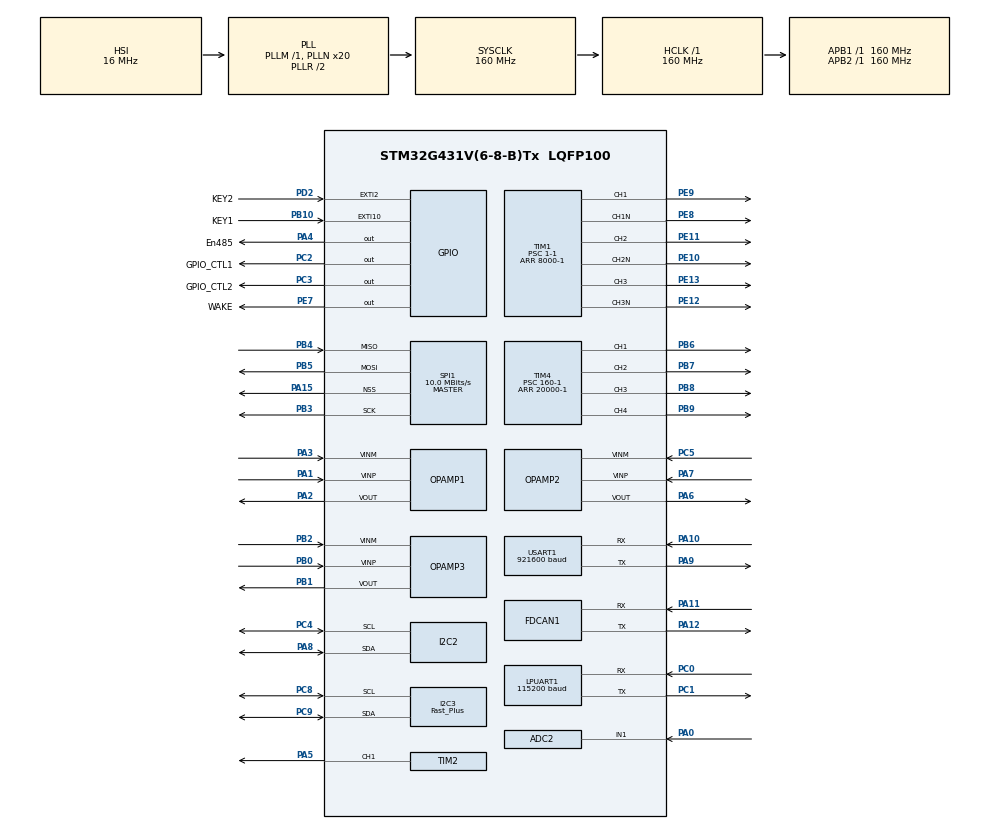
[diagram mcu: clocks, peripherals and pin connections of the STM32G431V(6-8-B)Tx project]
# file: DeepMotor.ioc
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ADC1.Channel-0\#ChannelRegularConversion=ADC_CHANNEL_3
ADC1.EnableInjectedConversion=ENABLE
ADC1.ExternalTrigInjecConv=ADC_EXTERNALTRIGINJEC_T1_CC4
ADC1.InjNumberOfConversion=2
ADC1.InjectedChannel-1\#ChannelInjectedConversion=ADC_CHANNEL_3
ADC1.InjectedChannel-2\#ChannelInjectedConversion=ADC_CHANNEL_12
ADC1.InjectedOffsetNumber-1\#ChannelInjectedConversion=ADC_OFFSET_NONE
ADC1.InjectedOffsetNumber-2\#ChannelInjectedConversion=ADC_OFFSET_NONE
ADC1.InjectedRank-1\#ChannelInjectedConversion=1
ADC1.InjectedRank-2\#ChannelInjectedConversion=2
ADC1.InjectedSamplingTime-1\#ChannelInjectedConversion=ADC_SAMPLETIME_2CYCLES_5
ADC1.InjectedSamplingTime-2\#ChannelInjectedConversion=ADC_SAMPLETIME_2CYCLES_5
ADC1.NbrOfConversionFlag=1
ADC1.OffsetNumber-0\#ChannelRegularConversion=ADC_OFFSET_NONE
ADC1.Rank-0\#ChannelRegularConversion=1
ADC1.SamplingTime-0\#ChannelRegularConversion=ADC_SAMPLETIME_2CYCLES_5
ADC1.master=1
ADC2.Channel-0\#ChannelRegularConversion=ADC_CHANNEL_1
ADC2.EnableInjectedConversion=ENABLE
ADC2.ExternalTrigInjecConv=ADC_EXTERNALTRIGINJEC_T1_CC4
ADC2.InjNumberOfConversion=1
ADC2.InjectedChannel-1\#ChannelInjectedConversion=ADC_CHANNEL_3
ADC2.InjectedOffsetNumber-1\#ChannelInjectedConversion=ADC_OFFSET_NONE
ADC2.InjectedRank-1\#ChannelInjectedConversion=1
ADC2.InjectedSamplingTime-1\#ChannelInjectedConversion=ADC_SAMPLETIME_2CYCLES_5
ADC2.NbrOfConversionFlag=1
ADC2.OffsetNumber-0\#ChannelRegularConversion=ADC_OFFSET_NONE
ADC2.Rank-0\#ChannelRegularConversion=1
ADC2.Rank1_Channel=ADC_CHANNEL_3
ADC2.SamplingTime-0\#ChannelRegularConversion=ADC_SAMPLETIME_2CYCLES_5
COMP1.TriggerMode=COMP_TRIGGERMODE_IT_RISING
Dma.Request0=USART1_TX
Dma.Request1=SPI1_RX
Dma.Request2=SPI1_TX
Dma.SPI1_RX.1.Direction=DMA_PERIPH_TO_MEMORY
Dma.SPI1_RX.1.EventEnable=DISABLE
Dma.SPI1_RX.1.Instance=DMA1_Channel2
Dma.SPI1_RX.1.MemDataAlignment=DMA_MDATAALIGN_HALFWORD
Dma.SPI1_RX.1.MemInc=DMA_MINC_ENABLE
Dma.SPI1_RX.1.Mode=DMA_NORMAL
Dma.SPI1_RX.1.PeriphDataAlignment=DMA_PDATAALIGN_HALFWORD
Dma.SPI1_RX.1.PeriphInc=DMA_PINC_DISABLE
Dma.SPI1_RX.1.Polarity=HAL_DMAMUX_REQ_GEN_RISING
Dma.SPI1_RX.1.Priority=DMA_PRIORITY_LOW
Dma.SPI1_RX.1.RequestNumber=1
Dma.SPI1_RX.1.SignalID=NONE
Dma.SPI1_RX.1.SyncEnable=DISABLE
Dma.SPI1_RX.1.SyncPolarity=HAL_DMAMUX_SYNC_NO_EVENT
Dma.SPI1_RX.1.SyncRequestNumber=1
Dma.SPI1_RX.1.SyncSignalID=NONE
Dma.SPI1_TX.2.Direction=DMA_MEMORY_TO_PERIPH
Dma.SPI1_TX.2.EventEnable=DISABLE
Dma.SPI1_TX.2.Instance=DMA1_Channel3
Dma.SPI1_TX.2.MemDataAlignment=DMA_MDATAALIGN_HALFWORD
Dma.SPI1_TX.2.MemInc=DMA_MINC_ENABLE
Dma.SPI1_TX.2.Mode=DMA_NORMAL
Dma.SPI1_TX.2.PeriphDataAlignment=DMA_PDATAALIGN_HALFWORD
Dma.SPI1_TX.2.PeriphInc=DMA_PINC_DISABLE
Dma.SPI1_TX.2.Polarity=HAL_DMAMUX_REQ_GEN_RISING
Dma.SPI1_TX.2.Priority=DMA_PRIORITY_LOW
Dma.SPI1_TX.2.RequestNumber=1
Dma.SPI1_TX.2.SignalID=NONE
Dma.SPI1_TX.2.SyncEnable=DISABLE
Dma.SPI1_TX.2.SyncPolarity=HAL_DMAMUX_SYNC_NO_EVENT
Dma.SPI1_TX.2.SyncRequestNumber=1
Dma.SPI1_TX.2.SyncSignalID=NONE
Dma.USART1_TX.0.Direction=DMA_MEMORY_TO_PERIPH
Dma.USART1_TX.0.EventEnable=DISABLE
Dma.USART1_TX.0.Instance=DMA1_Channel1
Dma.USART1_TX.0.MemDataAlignment=DMA_MDATAALIGN_BYTE
Dma.USART1_TX.0.MemInc=DMA_MINC_ENABLE
Dma.USART1_TX.0.Mode=DMA_NORMAL
Dma.USART1_TX.0.PeriphDataAlignment=DMA_PDATAALIGN_BYTE
Dma.USART1_TX.0.PeriphInc=DMA_PINC_DISABLE
Dma.USART1_TX.0.Polarity=HAL_DMAMUX_REQ_GEN_RISING
Dma.USART1_TX.0.Priority=DMA_PRIORITY_LOW
Dma.USART1_TX.0.RequestNumber=1
Dma.USART1_TX.0.SignalID=NONE
Dma.USART1_TX.0.SyncEnable=DISABLE
Dma.USART1_TX.0.SyncPolarity=HAL_DMAMUX_SYNC_NO_EVENT
Dma.USART1_TX.0.SyncRequestNumber=1
Dma.USART1_TX.0.SyncSignalID=NONE
FDCAN1.CalculateBaudRateNominal=1000000
FDCAN1.CalculateTimeBitNominal=1000
FDCAN1.CalculateTimeQuantumNominal=62.5
FDCAN1.DataPrescaler=10
FDCAN1.DataTimeSeg1=10
FDCAN1.DataTimeSeg2=5
FDCAN1.Mode=FDCAN_MODE_NORMAL
FDCAN1.NominalPrescaler=10
FDCAN1.NominalTimeSeg1=10
FDCAN1.NominalTimeSeg2=5
I2C2.Timing=0x30D29DE4
I2C3.I2C_Speed_Mode=I2C_Fast_Plus
I2C3.Timing=0x10B30F25
LPUART1.BaudRate=115200
Mcu.Family=STM32G4
Mcu.Name=STM32G431V(6-8-B)Tx
Mcu.Package=LQFP100
NVIC.ADC1_2_IRQn=true\:0\:0\:false\:false\:true\:true\:true\:true
NVIC.COMP1_2_3_IRQn=true\:0\:0\:false\:false\:true\:false\:true\:true
NVIC.DMA1_Channel1_IRQn=true\:0\:0\:false\:false\:true\:false\:true\:true
NVIC.DMA1_Channel2_IRQn=true\:0\:0\:false\:false\:true\:false\:true\:true
NVIC.DMA1_Channel3_IRQn=true\:0\:0\:false\:false\:true\:false\:true\:true
NVIC.EXTI15_10_IRQn=true\:0\:0\:false\:false\:true\:true\:true\:true
NVIC.EXTI2_IRQn=true\:0\:0\:false\:false\:true\:true\:true\:true
NVIC.FDCAN1_IT0_IRQn=true\:0\:0\:false\:false\:true\:true\:true\:true
NVIC.PriorityGroup=NVIC_PRIORITYGROUP_4
NVIC.TIM1_BRK_TIM15_IRQn=true\:0\:0\:false\:false\:true\:true\:true\:true
NVIC.TIM1_CC_IRQn=true\:0\:0\:false\:false\:true\:true\:true\:true
NVIC.TIM1_UP_TIM16_IRQn=true\:0\:0\:false\:false\:true\:true\:true\:true
NVIC.USART1_IRQn=true\:0\:0\:false\:false\:true\:true\:true\:true
PA0.Mode=IN1-Single-Ended
PA0.Signal=ADC2_IN1
PA1.Mode=Standalone
PA1.Signal=OPAMP1_VINP
PA10.Mode=Asynchronous
PA10.Signal=USART1_RX
PA11.Mode=FDCAN_Activate
PA11.Signal=FDCAN1_RX
PA12.Mode=FDCAN_Activate
PA12.Signal=FDCAN1_TX
PA13.Mode=Serial_Wire
PA13.Signal=SYS_JTMS-SWDIO
PA14.Mode=Serial_Wire
PA14.Signal=SYS_JTCK-SWCLK
PA15.GPIO_PuPd=GPIO_PULLUP
PA15.Mode=NSS_Signal_Hard_Output
PA15.Signal=SPI1_NSS
PA2.Signal=SharedAnalog_PA2
PA3.Mode=Standalone
PA3.Signal=OPAMP1_VINM
PA4.GPIO_Label=En485
PA4.Signal=GPIO_Output
PA5.Signal=S_TIM2_CH1
PA6.Signal=SharedAnalog_PA6
PA7.Mode=Standalone
PA7.Signal=OPAMP2_VINP
PA8.Mode=I2C
PA8.Signal=I2C2_SDA
PA9.Mode=Asynchronous
PA9.Signal=USART1_TX
PB0.Mode=Standalone
PB0.Signal=OPAMP3_VINP
PB1.Signal=SharedAnalog_PB1
PB10.GPIO_Label=KEY1
PB10.Signal=GPXTI10
PB2.Mode=Standalone
PB2.Signal=OPAMP3_VINM
PB3.GPIO_PuPd=GPIO_PULLUP
PB3.Mode=Full_Duplex_Master
PB3.Signal=SPI1_SCK
PB4.GPIO_PuPd=GPIO_PULLUP
PB4.Mode=Full_Duplex_Master
PB4.Signal=SPI1_MISO
PB5.GPIO_PuPd=GPIO_PULLUP
PB5.Mode=Full_Duplex_Master
PB5.Signal=SPI1_MOSI
PB6.GPIO_PuPd=GPIO_NOPULL
PB6.Signal=S_TIM4_CH1
PB7.GPIO_PuPd=GPIO_NOPULL
PB7.Signal=S_TIM4_CH2
PB8-BOOT0.Signal=S_TIM4_CH3
PB9.GPIO_PuPd=GPIO_NOPULL
PB9.Signal=S_TIM4_CH4
PC0.Mode=Asynchronous
PC0.Signal=LPUART1_RX
PC1.Mode=Asynchronous
PC1.Signal=LPUART1_TX
PC2.GPIO_Label=GPIO_CTL1
PC2.Signal=GPIO_Output
PC3.GPIO_Label=GPIO_CTL2
PC3.Signal=GPIO_Output
PC4.Mode=I2C
PC4.Signal=I2C2_SCL
PC5.Mode=Standalone
PC5.Signal=OPAMP2_VINM
PC8.Mode=I2C
PC8.Signal=I2C3_SCL
PC9.Mode=I2C
PC9.Signal=I2C3_SDA
PD2.GPIO_Label=KEY2
PD2.Signal=GPXTI2
PE10.Mode=PWM Generation2 CH2 CH2N
PE10.Signal=TIM1_CH2N
PE11.Signal=S_TIM1_CH2
PE12.Mode=PWM Generation3 CH3 CH3N
PE12.Signal=TIM1_CH3N
PE13.Signal=S_TIM1_CH3
PE7.GPIO_Label=WAKE
PE7.PinState=GPIO_PIN_SET
PE7.Signal=GPIO_Output
PE8.Mode=PWM Generation1 CH1 CH1N
PE8.Signal=TIM1_CH1N
PE9.Signal=S_TIM1_CH1
ProjectManager.HeapSize=0x200
ProjectManager.StackSize=0x400
ProjectManager.TargetToolchain=MDK-ARM V5
RCC.ADC12Freq_Value=160000000
RCC.AHBFreq_Value=160000000
RCC.APB1Freq_Value=160000000
RCC.APB1TimFreq_Value=160000000
RCC.APB2Freq_Value=160000000
RCC.APB2TimFreq_Value=160000000
RCC.CortexFreq_Value=160000000
RCC.EXTERNAL_CLOCK_VALUE=12288000
RCC.HCLKFreq_Value=160000000
RCC.HSE_VALUE=24000000
RCC.HSI48_VALUE=48000000
RCC.HSI_VALUE=16000000
RCC.LSE_VALUE=32768
RCC.PLLN=20
RCC.SYSCLKFreq_VALUE=160000000
RCC.SYSCLKSource=RCC_SYSCLKSOURCE_PLLCLK
RCC.USBFreq_Value=160000000
RCC.VCOOutputFreq_Value=320000000
SH.S_TIM1_CH1.0=TIM1_CH1,PWM Generation1 CH1 CH1N
SH.S_TIM1_CH2.0=TIM1_CH2,PWM Generation2 CH2 CH2N
SH.S_TIM1_CH3.0=TIM1_CH3,PWM Generation3 CH3 CH3N
SH.S_TIM2_CH1.0=TIM2_CH1,PWM Generation1 CH1
SH.S_TIM4_CH1.0=TIM4_CH1,PWM Generation1 CH1
SH.S_TIM4_CH2.0=TIM4_CH2,PWM Generation2 CH2
SH.S_TIM4_CH3.0=TIM4_CH3,PWM Generation3 CH3
SH.S_TIM4_CH4.0=TIM4_CH4,PWM Generation4 CH4
SH.SharedAnalog_PA2.0=OPAMP1_VOUT,Standalone
SH.SharedAnalog_PA2.1=ADC1_IN3,IN3-Single-Ended
SH.SharedAnalog_PA6.0=OPAMP2_VOUT,Standalone
SH.SharedAnalog_PA6.1=ADC2_IN3,IN3-Single-Ended
SH.SharedAnalog_PB1.0=OPAMP3_VOUT,Standalone
SH.SharedAnalog_PB1.1=ADC1_IN12,IN12-Single-Ended
SH.SharedAnalog_PB1.2=COMP1_INP,INP
SPI1.BaudRatePrescaler=SPI_BAUDRATEPRESCALER_16
SPI1.CLKPhase=SPI_PHASE_2EDGE
SPI1.CalculateBaudRate=10.0 MBits/s
SPI1.DataSize=SPI_DATASIZE_16BIT
SPI1.Direction=SPI_DIRECTION_2LINES
SPI1.Mode=SPI_MODE_MASTER
SPI1.VirtualNSS=VM_NSSHARD
SPI1.VirtualType=VM_MASTER
STMicroelectronics.X-CUBE-ALGOBUILD.1.3.0.LibraryCcDSPOoLibraryJjDSPOoLibrary=true
TIM1.BreakFilter=2
TIM1.BreakState=TIM_BREAK_ENABLE
TIM1.Channel-PWM\ Generation1\ CH1\ CH1N=TIM_CHANNEL_1
TIM1.Channel-PWM\ Generation2\ CH2\ CH2N=TIM_CHANNEL_2
TIM1.Channel-PWM\ Generation3\ CH3\ CH3N=TIM_CHANNEL_3
TIM1.Channel-PWM\ Generation4\ No\ Output=TIM_CHANNEL_4
TIM1.ClockDivision=TIM_CLOCKDIVISION_DIV2
TIM1.CounterMode=TIM_COUNTERMODE_CENTERALIGNED1
TIM1.DeadTime=120
TIM1.OCMode_PWM-PWM\ Generation4\ No\ Output=TIM_OCMODE_PWM2
TIM1.PeriodNoDither=8000-1
TIM1.Prescaler=1-1
TIM1.PulseNoDither_4=8000-2
TIM1.RepetitionCounter=1
TIM1.SourceBRKCOMP1=TIM_BREAKINPUTSOURCE_ENABLE
TIM1.TIM_MasterOutputTrigger=TIM_TRGO_OC4REF
TIM2.Channel-PWM\ Generation1\ CH1=TIM_CHANNEL_1
TIM2.PeriodNoDither=20000-1
TIM2.Prescaler=160-1
TIM2.PulseNoDither_1=1000
TIM4.Channel-PWM\ Generation1\ CH1=TIM_CHANNEL_1
TIM4.Channel-PWM\ Generation2\ CH2=TIM_CHANNEL_2
TIM4.Channel-PWM\ Generation3\ CH3=TIM_CHANNEL_3
TIM4.Channel-PWM\ Generation4\ CH4=TIM_CHANNEL_4
TIM4.PeriodNoDither=20000-1
TIM4.Prescaler=160-1
TIM4.PulseNoDither_1=500
TIM4.PulseNoDither_2=1000
TIM4.PulseNoDither_3=1500
USART1.BaudRate=921600
USART1.VirtualMode-Asynchronous=VM_ASYNC
VP_COMP1_VS_DAC3OUT1.Mode=INM_DAC3OUT1
VP_DAC3_VS_DACI1.Mode=DAC_OUT1_Int
VP_STMicroelectronics.X-CUBE-ALGOBUILD_VS_DSPOoLibraryJjLibrary_1.3.0_1.3.0.Mode=DSPOoLibraryJjLibrary
VP_SYS_VS_DBSignals.Mode=DisableDeadBatterySignals
VP_TIM1_VS_ClockSourceINT.Mode=Internal
VP_TIM1_VS_no_output4.Mode=PWM Generation4 No Output
VP_TIM2_VS_ClockSourceINT.Mode=Internal
VP_TIM4_VS_ClockSourceINT.Mode=Internal
board=custom

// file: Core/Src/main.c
/* USER CODE BEGIN Header */
/**
  ******************************************************************************
  * @file           : main.c
  * @brief          : Main program body
  ******************************************************************************
  * @attention
  *
  * Copyright (c) 2023 STMicroelectronics.
  * All rights reserved.
  *
  * This software is licensed under terms that can be found in the LICENSE file
  * in the root directory of this software component.
  * If no LICENSE file comes with this software, it is provided AS-IS.
  *
  ******************************************************************************
  */

/* USER CODE END Header */
#include "main.h"
#include "adc.h"
#include "comp.h"
#include "dac.h"
#include "dma.h"
#include "fdcan.h"
#include "i2c.h"
#include "usart.h"
#include "opamp.h"
#include "spi.h"
#include "tim.h"
#include "gpio.h"

/* USER CODE BEGIN Includes */

#define ADC4_SAMPLINGTIME_COMMON_1 LL_ADC_SAMPLINGTIME_COMMON_1
#define ADC4_SAMPLINGTIME_COMMON_2 LL_ADC_SAMPLINGTIME_COMMON_2
#define ADC4_SAMPLINGTIME_COMMON_1 LL_ADC_SAMPLINGTIME_COMMON_1
#define ADC4_SAMPLINGTIME_COMMON_2 LL_ADC_SAMPLINGTIME_COMMON_2
#define ADC4_SAMPLINGTIME_COMMON_1 LL_ADC_SAMPLINGTIME_COMMON_1
#define ADC4_SAMPLINGTIME_COMMON_2 LL_ADC_SAMPLINGTIME_COMMON_2
#define ADC4_SAMPLINGTIME_COMMON_1 LL_ADC_SAMPLINGTIME_COMMON_1
#define ADC4_SAMPLINGTIME_COMMON_2 LL_ADC_SAMPLINGTIME_COMMON_2
#define ADC4_SAMPLINGTIME_COMMON_1 LL_ADC_SAMPLINGTIME_COMMON_1
#define ADC4_SAMPLINGTIME_COMMON_2 LL_ADC_SAMPLINGTIME_COMMON_2
#define ADC4_SAMPLINGTIME_COMMON_1 LL_ADC_SAMPLINGTIME_COMMON_1
#define ADC4_SAMPLINGTIME_COMMON_2 LL_ADC_SAMPLINGTIME_COMMON_2
#define ADC4_SAMPLINGTIME_COMMON_1 LL_ADC_SAMPLINGTIME_COMMON_1
#define ADC4_SAMPLINGTIME_COMMON_2 LL_ADC_SAMPLINGTIME_COMMON_2
#define ADC4_SAMPLINGTIME_COMMON_1 LL_ADC_SAMPLINGTIME_COMMON_1
#define ADC4_SAMPLINGTIME_COMMON_2 LL_ADC_SAMPLINGTIME_COMMON_2
#define ADC4_SAMPLINGTIME_COMMON_1 LL_ADC_SAMPLINGTIME_COMMON_1
#define ADC4_SAMPLINGTIME_COMMON_2 LL_ADC_SAMPLINGTIME_COMMON_2
#define ADC4_SAMPLINGTIME_COMMON_1 LL_ADC_SAMPLINGTIME_COMMON_1
#define ADC4_SAMPLINGTIME_COMMON_2 LL_ADC_SAMPLINGTIME_COMMON_2
#define ADC4_SAMPLINGTIME_COMMON_1 LL_ADC_SAMPLINGTIME_COMMON_1
#define ADC4_SAMPLINGTIME_COMMON_2 LL_ADC_SAMPLINGTIME_COMMON_2
#define ADC4_SAMPLINGTIME_COMMON_1 LL_ADC_SAMPLINGTIME_COMMON_1
#define ADC4_SAMPLINGTIME_COMMON_2 LL_ADC_SAMPLINGTIME_COMMON_2
#define ADC4_SAMPLINGTIME_COMMON_1 LL_ADC_SAMPLINGTIME_COMMON_1
#define ADC4_SAMPLINGTIME_COMMON_2 LL_ADC_SAMPLINGTIME_COMMON_2
#define ADC4_SAMPLINGTIME_COMMON_1 LL_ADC_SAMPLINGTIME_COMMON_1
#define ADC4_SAMPLINGTIME_COMMON_2 LL_ADC_SAMPLINGTIME_COMMON_2
#define ADC4_SAMPLINGTIME_COMMON_1 LL_ADC_SAMPLINGTIME_COMMON_1
#define ADC4_SAMPLINGTIME_COMMON_2 LL_ADC_SAMPLINGTIME_COMMON_2
#define ADC4_SAMPLINGTIME_COMMON_1 LL_ADC_SAMPLINGTIME_COMMON_1
#define ADC4_SAMPLINGTIME_COMMON_2 LL_ADC_SAMPLINGTIME_COMMON_2
#define ADC4_SAMPLINGTIME_COMMON_1 LL_ADC_SAMPLINGTIME_COMMON_1
#define ADC4_SAMPLINGTIME_COMMON_2 LL_ADC_SAMPLINGTIME_COMMON_2
#define ADC4_SAMPLINGTIME_COMMON_1 LL_ADC_SAMPLINGTIME_COMMON_1
#define ADC4_SAMPLINGTIME_COMMON_2 LL_ADC_SAMPLINGTIME_COMMON_2
#define ADC4_SAMPLINGTIME_COMMON_1 LL_ADC_SAMPLINGTIME_COMMON_1
#define ADC4_SAMPLINGTIME_COMMON_2 LL_ADC_SAMPLINGTIME_COMMON_2
#define ADC4_SAMPLINGTIME_COMMON_1 LL_ADC_SAMPLINGTIME_COMMON_1
#define ADC4_SAMPLINGTIME_COMMON_2 LL_ADC_SAMPLINGTIME_COMMON_2
#define ADC4_SAMPLINGTIME_COMMON_1 LL_ADC_SAMPLINGTIME_COMMON_1
#define ADC4_SAMPLINGTIME_COMMON_2 LL_ADC_SAMPLINGTIME_COMMON_2
#define ADC4_SAMPLINGTIME_COMMON_1 LL_ADC_SAMPLINGTIME_COMMON_1
#define ADC4_SAMPLINGTIME_COMMON_2 LL_ADC_SAMPLINGTIME_COMMON_2
#define ADC4_SAMPLINGTIME_COMMON_1 LL_ADC_SAMPLINGTIME_COMMON_1
#define ADC4_SAMPLINGTIME_COMMON_2 LL_ADC_SAMPLINGTIME_COMMON_2
#define ADC4_SAMPLINGTIME_COMMON_1 LL_ADC_SAMPLINGTIME_COMMON_1
#define ADC4_SAMPLINGTIME_COMMON_2 LL_ADC_SAMPLINGTIME_COMMON_2
#define ADC4_SAMPLINGTIME_COMMON_1 LL_ADC_SAMPLINGTIME_COMMON_1
#define ADC4_SAMPLINGTIME_COMMON_2 LL_ADC_SAMPLINGTIME_COMMON_2
#define ADC4_SAMPLINGTIME_COMMON_1 LL_ADC_SAMPLINGTIME_COMMON_1
#define ADC4_SAMPLINGTIME_COMMON_2 LL_ADC_SAMPLINGTIME_COMMON_2
#define ADC4_SAMPLINGTIME_COMMON_1 LL_ADC_SAMPLINGTIME_COMMON_1
#define ADC4_SAMPLINGTIME_COMMON_2 LL_ADC_SAMPLINGTIME_COMMON_2
#define ADC4_SAMPLINGTIME_COMMON_1 LL_ADC_SAMPLINGTIME_COMMON_1
#define ADC4_SAMPLINGTIME_COMMON_2 LL_ADC_SAMPLINGTIME_COMMON_2
#define ADC4_SAMPLINGTIME_COMMON_1 LL_ADC_SAMPLINGTIME_COMMON_1
#define ADC4_SAMPLINGTIME_COMMON_2 LL_ADC_SAMPLINGTIME_COMMON_2
#define ADC4_SAMPLINGTIME_COMMON_1 LL_ADC_SAMPLINGTIME_COMMON_1
#define ADC4_SAMPLINGTIME_COMMON_2 LL_ADC_SAMPLINGTIME_COMMON_2
#define ADC4_SAMPLINGTIME_COMMON_1 LL_ADC_SAMPLINGTIME_COMMON_1
#define ADC4_SAMPLINGTIME_COMMON_2 LL_ADC_SAMPLINGTIME_COMMON_2
#define ADC4_SAMPLINGTIME_COMMON_1 LL_ADC_SAMPLINGTIME_COMMON_1
#define ADC4_SAMPLINGTIME_COMMON_2 LL_ADC_SAMPLINGTIME_COMMON_2
#define ADC4_SAMPLINGTIME_COMMON_1 LL_ADC_SAMPLINGTIME_COMMON_1
#define ADC4_SAMPLINGTIME_COMMON_2 LL_ADC_SAMPLINGTIME_COMMON_2
#define ADC4_SAMPLINGTIME_COMMON_1 LL_ADC_SAMPLINGTIME_COMMON_1
#define ADC4_SAMPLINGTIME_COMMON_2 LL_ADC_SAMPLINGTIME_COMMON_2
#define ADC4_SAMPLINGTIME_COMMON_1 LL_ADC_SAMPLINGTIME_COMMON_1
#define ADC4_SAMPLINGTIME_COMMON_2 LL_ADC_SAMPLINGTIME_COMMON_2
#define ADC4_SAMPLINGTIME_COMMON_1 LL_ADC_SAMPLINGTIME_COMMON_1
#define ADC4_SAMPLINGTIME_COMMON_2 LL_ADC_SAMPLINGTIME_COMMON_2
#define ADC4_SAMPLINGTIME_COMMON_1 LL_ADC_SAMPLINGTIME_COMMON_1
#define ADC4_SAMPLINGTIME_COMMON_2 LL_ADC_SAMPLINGTIME_COMMON_2
#define ADC4_SAMPLINGTIME_COMMON_1 LL_ADC_SAMPLINGTIME_COMMON_1
#define ADC4_SAMPLINGTIME_COMMON_2 LL_ADC_SAMPLINGTIME_COMMON_2
#define ADC4_SAMPLINGTIME_COMMON_1 LL_ADC_SAMPLINGTIME_COMMON_1
#define ADC4_SAMPLINGTIME_COMMON_2 LL_ADC_SAMPLINGTIME_COMMON_2
#define ADC4_SAMPLINGTIME_COMMON_1 LL_ADC_SAMPLINGTIME_COMMON_1
#define ADC4_SAMPLINGTIME_COMMON_2 LL_ADC_SAMPLINGTIME_COMMON_2
#define ADC4_SAMPLINGTIME_COMMON_1 LL_ADC_SAMPLINGTIME_COMMON_1
#define ADC4_SAMPLINGTIME_COMMON_2 LL_ADC_SAMPLINGTIME_COMMON_2
#define ADC4_SAMPLINGTIME_COMMON_1 LL_ADC_SAMPLINGTIME_COMMON_1
#define ADC4_SAMPLINGTIME_COMMON_2 LL_ADC_SAMPLINGTIME_COMMON_2
#define ADC4_SAMPLINGTIME_COMMON_1 LL_ADC_SAMPLINGTIME_COMMON_1
#define ADC4_SAMPLINGTIME_COMMON_2 LL_ADC_SAMPLINGTIME_COMMON_2
#define ADC4_SAMPLINGTIME_COMMON_1 LL_ADC_SAMPLINGTIME_COMMON_1
#define ADC4_SAMPLINGTIME_COMMON_2 LL_ADC_SAMPLINGTIME_COMMON_2
#define ADC4_SAMPLINGTIME_COMMON_1 LL_ADC_SAMPLINGTIME_COMMON_1
#define ADC4_SAMPLINGTIME_COMMON_2 LL_ADC_SAMPLINGTIME_COMMON_2
#define ADC4_SAMPLINGTIME_COMMON_1 LL_ADC_SAMPLINGTIME_COMMON_1
#define ADC4_SAMPLINGTIME_COMMON_2 LL_ADC_SAMPLINGTIME_COMMON_2
#define ADC4_SAMPLINGTIME_COMMON_1 LL_ADC_SAMPLINGTIME_COMMON_1
#define ADC4_SAMPLINGTIME_COMMON_2 LL_ADC_SAMPLINGTIME_COMMON_2
#define ADC4_SAMPLINGTIME_COMMON_1 LL_ADC_SAMPLINGTIME_COMMON_1
#define ADC4_SAMPLINGTIME_COMMON_2 LL_ADC_SAMPLINGTIME_COMMON_2
#define ADC4_SAMPLINGTIME_COMMON_1 LL_ADC_SAMPLINGTIME_COMMON_1
#define ADC4_SAMPLINGTIME_COMMON_2 LL_ADC_SAMPLINGTIME_COMMON_2
#define ADC4_SAMPLINGTIME_COMMON_1 LL_ADC_SAMPLINGTIME_COMMON_1
#define ADC4_SAMPLINGTIME_COMMON_2 LL_ADC_SAMPLINGTIME_COMMON_2
#define ADC4_SAMPLINGTIME_COMMON_1 LL_ADC_SAMPLINGTIME_COMMON_1
#define ADC4_SAMPLINGTIME_COMMON_2 LL_ADC_SAMPLINGTIME_COMMON_2
#define ADC4_SAMPLINGTIME_COMMON_1 LL_ADC_SAMPLINGTIME_COMMON_1
#define ADC4_SAMPLINGTIME_COMMON_2 LL_ADC_SAMPLINGTIME_COMMON_2
#define ADC4_SAMPLINGTIME_COMMON_1 LL_ADC_SAMPLINGTIME_COMMON_1
#define ADC4_SAMPLINGTIME_COMMON_2 LL_ADC_SAMPLINGTIME_COMMON_2
#define ADC4_SAMPLINGTIME_COMMON_1 LL_ADC_SAMPLINGTIME_COMMON_1
#define ADC4_SAMPLINGTIME_COMMON_2 LL_ADC_SAMPLINGTIME_COMMON_2
#define ADC4_SAMPLINGTIME_COMMON_1 LL_ADC_SAMPLINGTIME_COMMON_1
#define ADC4_SAMPLINGTIME_COMMON_2 LL_ADC_SAMPLINGTIME_COMMON_2
#define ADC4_SAMPLINGTIME_COMMON_1 LL_ADC_SAMPLINGTIME_COMMON_1
#define ADC4_SAMPLINGTIME_COMMON_2 LL_ADC_SAMPLINGTIME_COMMON_2
#define ADC4_SAMPLINGTIME_COMMON_1 LL_ADC_SAMPLINGTIME_COMMON_1
#define ADC4_SAMPLINGTIME_COMMON_2 LL_ADC_SAMPLINGTIME_COMMON_2
#define ADC4_SAMPLINGTIME_COMMON_1 LL_ADC_SAMPLINGTIME_COMMON_1
#define ADC4_SAMPLINGTIME_COMMON_2 LL_ADC_SAMPLINGTIME_COMMON_2
#define ADC4_SAMPLINGTIME_COMMON_1 LL_ADC_SAMPLINGTIME_COMMON_1
#define ADC4_SAMPLINGTIME_COMMON_2 LL_ADC_SAMPLINGTIME_COMMON_2
#define ADC4_SAMPLINGTIME_COMMON_1 LL_ADC_SAMPLINGTIME_COMMON_1
#define ADC4_SAMPLINGTIME_COMMON_2 LL_ADC_SAMPLINGTIME_COMMON_2
#define ADC4_SAMPLINGTIME_COMMON_1 LL_ADC_SAMPLINGTIME_COMMON_1
#define ADC4_SAMPLINGTIME_COMMON_2 LL_ADC_SAMPLINGTIME_COMMON_2
#define ADC4_SAMPLINGTIME_COMMON_1 LL_ADC_SAMPLINGTIME_COMMON_1
#define ADC4_SAMPLINGTIME_COMMON_2 LL_ADC_SAMPLINGTIME_COMMON_2
#define ADC4_SAMPLINGTIME_COMMON_1 LL_ADC_SAMPLINGTIME_COMMON_1
#define ADC4_SAMPLINGTIME_COMMON_2 LL_ADC_SAMPLINGTIME_COMMON_2
#define ADC4_SAMPLINGTIME_COMMON_1 LL_ADC_SAMPLINGTIME_COMMON_1
#define ADC4_SAMPLINGTIME_COMMON_2 LL_ADC_SAMPLINGTIME_COMMON_2
#define ADC4_SAMPLINGTIME_COMMON_1 LL_ADC_SAMPLINGTIME_COMMON_1
#define ADC4_SAMPLINGTIME_COMMON_2 LL_ADC_SAMPLINGTIME_COMMON_2
#define ADC4_SAMPLINGTIME_COMMON_1 LL_ADC_SAMPLINGTIME_COMMON_1
#define ADC4_SAMPLINGTIME_COMMON_2 LL_ADC_SAMPLINGTIME_COMMON_2
#define ADC4_SAMPLINGTIME_COMMON_1 LL_ADC_SAMPLINGTIME_COMMON_1
#define ADC4_SAMPLINGTIME_COMMON_2 LL_ADC_SAMPLINGTIME_COMMON_2
#define ADC4_SAMPLINGTIME_COMMON_1 LL_ADC_SAMPLINGTIME_COMMON_1
#define ADC4_SAMPLINGTIME_COMMON_2 LL_ADC_SAMPLINGTIME_COMMON_2
#define ADC4_SAMPLINGTIME_COMMON_1 LL_ADC_SAMPLINGTIME_COMMON_1
#define ADC4_SAMPLINGTIME_COMMON_2 LL_ADC_SAMPLINGTIME_COMMON_2
#define ADC4_SAMPLINGTIME_COMMON_1 LL_ADC_SAMPLINGTIME_COMMON_1
#define ADC4_SAMPLINGTIME_COMMON_2 LL_ADC_SAMPLINGTIME_COMMON_2
#define ADC4_SAMPLINGTIME_COMMON_1 LL_ADC_SAMPLINGTIME_COMMON_1
#define ADC4_SAMPLINGTIME_COMMON_2 LL_ADC_SAMPLINGTIME_COMMON_2
#define ADC4_SAMPLINGTIME_COMMON_1 LL_ADC_SAMPLINGTIME_COMMON_1
#define ADC4_SAMPLINGTIME_COMMON_2 LL_ADC_SAMPLINGTIME_COMMON_2
#define ADC4_SAMPLINGTIME_COMMON_1 LL_ADC_SAMPLINGTIME_COMMON_1
#define ADC4_SAMPLINGTIME_COMMON_2 LL_ADC_SAMPLINGTIME_COMMON_2
#define ADC4_SAMPLINGTIME_COMMON_1 LL_ADC_SAMPLINGTIME_COMMON_1
#define ADC4_SAMPLINGTIME_COMMON_2 LL_ADC_SAMPLINGTIME_COMMON_2
#define ADC4_SAMPLINGTIME_COMMON_1 LL_ADC_SAMPLINGTIME_COMMON_1
#define ADC4_SAMPLINGTIME_COMMON_2 LL_ADC_SAMPLINGTIME_COMMON_2
#define ADC4_SAMPLINGTIME_COMMON_1 LL_ADC_SAMPLINGTIME_COMMON_1
#define ADC4_SAMPLINGTIME_COMMON_2 LL_ADC_SAMPLINGTIME_COMMON_2
#define ADC4_SAMPLINGTIME_COMMON_1 LL_ADC_SAMPLINGTIME_COMMON_1
#define ADC4_SAMPLINGTIME_COMMON_2 LL_ADC_SAMPLINGTIME_COMMON_2
#define ADC4_SAMPLINGTIME_COMMON_1 LL_ADC_SAMPLINGTIME_COMMON_1
#define ADC4_SAMPLINGTIME_COMMON_2 LL_ADC_SAMPLINGTIME_COMMON_2
#define ADC4_SAMPLINGTIME_COMMON_1 LL_ADC_SAMPLINGTIME_COMMON_1
#define ADC4_SAMPLINGTIME_COMMON_2 LL_ADC_SAMPLINGTIME_COMMON_2
#define ADC4_SAMPLINGTIME_COMMON_1 LL_ADC_SAMPLINGTIME_COMMON_1
#define ADC4_SAMPLINGTIME_COMMON_2 LL_ADC_SAMPLINGTIME_COMMON_2
#define ADC4_SAMPLINGTIME_COMMON_1 LL_ADC_SAMPLINGTIME_COMMON_1
#define ADC4_SAMPLINGTIME_COMMON_2 LL_ADC_SAMPLINGTIME_COMMON_2
#define ADC4_SAMPLINGTIME_COMMON_1 LL_ADC_SAMPLINGTIME_COMMON_1
#define ADC4_SAMPLINGTIME_COMMON_2 LL_ADC_SAMPLINGTIME_COMMON_2
#define ADC4_SAMPLINGTIME_COMMON_1 LL_ADC_SAMPLINGTIME_COMMON_1
#define ADC4_SAMPLINGTIME_COMMON_2 LL_ADC_SAMPLINGTIME_COMMON_2
#define ADC4_SAMPLINGTIME_COMMON_1 LL_ADC_SAMPLINGTIME_COMMON_1
#define ADC4_SAMPLINGTIME_COMMON_2 LL_ADC_SAMPLINGTIME_COMMON_2
#define ADC4_SAMPLINGTIME_COMMON_1 LL_ADC_SAMPLINGTIME_COMMON_1
#define ADC4_SAMPLINGTIME_COMMON_2 LL_ADC_SAMPLINGTIME_COMMON_2
#define ADC4_SAMPLINGTIME_COMMON_1 LL_ADC_SAMPLINGTIME_COMMON_1
#define ADC4_SAMPLINGTIME_COMMON_2 LL_ADC_SAMPLINGTIME_COMMON_2
#define ADC4_SAMPLINGTIME_COMMON_1 LL_ADC_SAMPLINGTIME_COMMON_1
#define ADC4_SAMPLINGTIME_COMMON_2 LL_ADC_SAMPLINGTIME_COMMON_2
#define ADC4_SAMPLINGTIME_COMMON_1 LL_ADC_SAMPLINGTIME_COMMON_1
#define ADC4_SAMPLINGTIME_COMMON_2 LL_ADC_SAMPLINGTIME_COMMON_2
#define ADC4_SAMPLINGTIME_COMMON_1 LL_ADC_SAMPLINGTIME_COMMON_1
#define ADC4_SAMPLINGTIME_COMMON_2 LL_ADC_SAMPLINGTIME_COMMON_2
#define ADC4_SAMPLINGTIME_COMMON_1 LL_ADC_SAMPLINGTIME_COMMON_1
#define ADC4_SAMPLINGTIME_COMMON_2 LL_ADC_SAMPLINGTIME_COMMON_2
#define ADC4_SAMPLINGTIME_COMMON_1 LL_ADC_SAMPLINGTIME_COMMON_1
#define ADC4_SAMPLINGTIME_COMMON_2 LL_ADC_SAMPLINGTIME_COMMON_2
#define ADC4_SAMPLINGTIME_COMMON_1 LL_ADC_SAMPLINGTIME_COMMON_1
#define ADC4_SAMPLINGTIME_COMMON_2 LL_ADC_SAMPLINGTIME_COMMON_2
#define ADC4_SAMPLINGTIME_COMMON_1 LL_ADC_SAMPLINGTIME_COMMON_1
#define ADC4_SAMPLINGTIME_COMMON_2 LL_ADC_SAMPLINGTIME_COMMON_2
#define ADC4_SAMPLINGTIME_COMMON_1 LL_ADC_SAMPLINGTIME_COMMON_1
#define ADC4_SAMPLINGTIME_COMMON_2 LL_ADC_SAMPLINGTIME_COMMON_2
#define ADC4_SAMPLINGTIME_COMMON_1 LL_ADC_SAMPLINGTIME_COMMON_1
#define ADC4_SAMPLINGTIME_COMMON_2 LL_ADC_SAMPLINGTIME_COMMON_2
#define ADC4_SAMPLINGTIME_COMMON_1 LL_ADC_SAMPLINGTIME_COMMON_1
#define ADC4_SAMPLINGTIME_COMMON_2 LL_ADC_SAMPLINGTIME_COMMON_2
#define ADC4_SAMPLINGTIME_COMMON_1 LL_ADC_SAMPLINGTIME_COMMON_1
#define ADC4_SAMPLINGTIME_COMMON_2 LL_ADC_SAMPLINGTIME_COMMON_2
#define ADC4_SAMPLINGTIME_COMMON_1 LL_ADC_SAMPLINGTIME_COMMON_1
#define ADC4_SAMPLINGTIME_COMMON_2 LL_ADC_SAMPLINGTIME_COMMON_2
#define ADC4_SAMPLINGTIME_COMMON_1 LL_ADC_SAMPLINGTIME_COMMON_1
#define ADC4_SAMPLINGTIME_COMMON_2 LL_ADC_SAMPLINGTIME_COMMON_2
#define ADC4_SAMPLINGTIME_COMMON_1 LL_ADC_SAMPLINGTIME_COMMON_1
#define ADC4_SAMPLINGTIME_COMMON_2 LL_ADC_SAMPLINGTIME_COMMON_2
#define ADC4_SAMPLINGTIME_COMMON_1 LL_ADC_SAMPLINGTIME_COMMON_1
#define ADC4_SAMPLINGTIME_COMMON_2 LL_ADC_SAMPLINGTIME_COMMON_2
#define ADC4_SAMPLINGTIME_COMMON_1 LL_ADC_SAMPLINGTIME_COMMON_1
#define ADC4_SAMPLINGTIME_COMMON_2 LL_ADC_SAMPLINGTIME_COMMON_2
#define ADC4_SAMPLINGTIME_COMMON_1 LL_ADC_SAMPLINGTIME_COMMON_1
#define ADC4_SAMPLINGTIME_COMMON_2 LL_ADC_SAMPLINGTIME_COMMON_2
#define ADC4_SAMPLINGTIME_COMMON_1 LL_ADC_SAMPLINGTIME_COMMON_1
#define ADC4_SAMPLINGTIME_COMMON_2 LL_ADC_SAMPLINGTIME_COMMON_2
#define ADC4_SAMPLINGTIME_COMMON_1 LL_ADC_SAMPLINGTIME_COMMON_1
#define ADC4_SAMPLINGTIME_COMMON_2 LL_ADC_SAMPLINGTIME_COMMON_2
#define ADC4_SAMPLINGTIME_COMMON_1 LL_ADC_SAMPLINGTIME_COMMON_1
#define ADC4_SAMPLINGTIME_COMMON_2 LL_ADC_SAMPLINGTIME_COMMON_2
#define ADC4_SAMPLINGTIME_COMMON_1 LL_ADC_SAMPLINGTIME_COMMON_1
#define ADC4_SAMPLINGTIME_COMMON_2 LL_ADC_SAMPLINGTIME_COMMON_2
#define ADC4_SAMPLINGTIME_COMMON_1 LL_ADC_SAMPLINGTIME_COMMON_1
#define ADC4_SAMPLINGTIME_COMMON_2 LL_ADC_SAMPLINGTIME_COMMON_2
#define ADC4_SAMPLINGTIME_COMMON_1 LL_ADC_SAMPLINGTIME_COMMON_1
#define ADC4_SAMPLINGTIME_COMMON_2 LL_ADC_SAMPLINGTIME_COMMON_2
#define ADC4_SAMPLINGTIME_COMMON_1 LL_ADC_SAMPLINGTIME_COMMON_1
#define ADC4_SAMPLINGTIME_COMMON_2 LL_ADC_SAMPLINGTIME_COMMON_2
#define ADC4_SAMPLINGTIME_COMMON_1 LL_ADC_SAMPLINGTIME_COMMON_1
#define ADC4_SAMPLINGTIME_COMMON_2 LL_ADC_SAMPLINGTIME_COMMON_2
#define ADC4_SAMPLINGTIME_COMMON_1 LL_ADC_SAMPLINGTIME_COMMON_1
#define ADC4_SAMPLINGTIME_COMMON_2 LL_ADC_SAMPLINGTIME_COMMON_2
#define ADC4_SAMPLINGTIME_COMMON_1 LL_ADC_SAMPLINGTIME_COMMON_1
#define ADC4_SAMPLINGTIME_COMMON_2 LL_ADC_SAMPLINGTIME_COMMON_2
#define ADC4_SAMPLINGTIME_COMMON_1 LL_ADC_SAMPLINGTIME_COMMON_1
#define ADC4_SAMPLINGTIME_COMMON_2 LL_ADC_SAMPLINGTIME_COMMON_2
#define ADC4_SAMPLINGTIME_COMMON_1 LL_ADC_SAMPLINGTIME_COMMON_1
#define ADC4_SAMPLINGTIME_COMMON_2 LL_ADC_SAMPLINGTIME_COMMON_2
#define ADC4_SAMPLINGTIME_COMMON_1 LL_ADC_SAMPLINGTIME_COMMON_1
#define ADC4_SAMPLINGTIME_COMMON_2 LL_ADC_SAMPLINGTIME_COMMON_2
#define ADC4_SAMPLINGTIME_COMMON_1 LL_ADC_SAMPLINGTIME_COMMON_1
#define ADC4_SAMPLINGTIME_COMMON_2 LL_ADC_SAMPLINGTIME_COMMON_2
#define ADC4_SAMPLINGTIME_COMMON_1 LL_ADC_SAMPLINGTIME_COMMON_1
#define ADC4_SAMPLINGTIME_COMMON_2 LL_ADC_SAMPLINGTIME_COMMON_2
#define ADC4_SAMPLINGTIME_COMMON_1 LL_ADC_SAMPLINGTIME_COMMON_1
#define ADC4_SAMPLINGTIME_COMMON_2 LL_ADC_SAMPLINGTIME_COMMON_2
#define ADC4_SAMPLINGTIME_COMMON_1 LL_ADC_SAMPLINGTIME_COMMON_1
#define ADC4_SAMPLINGTIME_COMMON_2 LL_ADC_SAMPLINGTIME_COMMON_2
#define ADC4_SAMPLINGTIME_COMMON_1 LL_ADC_SAMPLINGTIME_COMMON_1
#define ADC4_SAMPLINGTIME_COMMON_2 LL_ADC_SAMPLINGTIME_COMMON_2
#define ADC4_SAMPLINGTIME_COMMON_1 LL_ADC_SAMPLINGTIME_COMMON_1
#define ADC4_SAMPLINGTIME_COMMON_2 LL_ADC_SAMPLINGTIME_COMMON_2
#define ADC4_SAMPLINGTIME_COMMON_1 LL_ADC_SAMPLINGTIME_COMMON_1
#define ADC4_SAMPLINGTIME_COMMON_2 LL_ADC_SAMPLINGTIME_COMMON_2
#define ADC4_SAMPLINGTIME_COMMON_1 LL_ADC_SAMPLINGTIME_COMMON_1
#define ADC4_SAMPLINGTIME_COMMON_2 LL_ADC_SAMPLINGTIME_COMMON_2
#define ADC4_SAMPLINGTIME_COMMON_1 LL_ADC_SAMPLINGTIME_COMMON_1
#define ADC4_SAMPLINGTIME_COMMON_2 LL_ADC_SAMPLINGTIME_COMMON_2
#define ADC4_SAMPLINGTIME_COMMON_1 LL_ADC_SAMPLINGTIME_COMMON_1
#define ADC4_SAMPLINGTIME_COMMON_2 LL_ADC_SAMPLINGTIME_COMMON_2
#define ADC4_SAMPLINGTIME_COMMON_1 LL_ADC_SAMPLINGTIME_COMMON_1
#define ADC4_SAMPLINGTIME_COMMON_2 LL_ADC_SAMPLINGTIME_COMMON_2
#define ADC4_SAMPLINGTIME_COMMON_1 LL_ADC_SAMPLINGTIME_COMMON_1
#define ADC4_SAMPLINGTIME_COMMON_2 LL_ADC_SAMPLINGTIME_COMMON_2
#define ADC4_SAMPLINGTIME_COMMON_1 LL_ADC_SAMPLINGTIME_COMMON_1
#define ADC4_SAMPLINGTIME_COMMON_2 LL_ADC_SAMPLINGTIME_COMMON_2
#define ADC4_SAMPLINGTIME_COMMON_1 LL_ADC_SAMPLINGTIME_COMMON_1
#define ADC4_SAMPLINGTIME_COMMON_2 LL_ADC_SAMPLINGTIME_COMMON_2
#define ADC4_SAMPLINGTIME_COMMON_1 LL_ADC_SAMPLINGTIME_COMMON_1
#define ADC4_SAMPLINGTIME_COMMON_2 LL_ADC_SAMPLINGTIME_COMMON_2
#define ADC4_SAMPLINGTIME_COMMON_1 LL_ADC_SAMPLINGTIME_COMMON_1
#define ADC4_SAMPLINGTIME_COMMON_2 LL_ADC_SAMPLINGTIME_COMMON_2
#define ADC4_SAMPLINGTIME_COMMON_1 LL_ADC_SAMPLINGTIME_COMMON_1
#define ADC4_SAMPLINGTIME_COMMON_2 LL_ADC_SAMPLINGTIME_COMMON_2
#define ADC4_SAMPLINGTIME_COMMON_1 LL_ADC_SAMPLINGTIME_COMMON_1
#define ADC4_SAMPLINGTIME_COMMON_2 LL_ADC_SAMPLINGTIME_COMMON_2
#define ADC4_SAMPLINGTIME_COMMON_1 LL_ADC_SAMPLINGTIME_COMMON_1
#define ADC4_SAMPLINGTIME_COMMON_2 LL_ADC_SAMPLINGTIME_COMMON_2
#define ADC4_SAMPLINGTIME_COMMON_1 LL_ADC_SAMPLINGTIME_COMMON_1
#define ADC4_SAMPLINGTIME_COMMON_2 LL_ADC_SAMPLINGTIME_COMMON_2
#define ADC4_SAMPLINGTIME_COMMON_1 LL_ADC_SAMPLINGTIME_COMMON_1
#define ADC4_SAMPLINGTIME_COMMON_2 LL_ADC_SAMPLINGTIME_COMMON_2
#define ADC4_SAMPLINGTIME_COMMON_1 LL_ADC_SAMPLINGTIME_COMMON_1
#define ADC4_SAMPLINGTIME_COMMON_2 LL_ADC_SAMPLINGTIME_COMMON_2
#define ADC4_SAMPLINGTIME_COMMON_1 LL_ADC_SAMPLINGTIME_COMMON_1
#define ADC4_SAMPLINGTIME_COMMON_2 LL_ADC_SAMPLINGTIME_COMMON_2
#define ADC4_SAMPLINGTIME_COMMON_1 LL_ADC_SAMPLINGTIME_COMMON_1
#define ADC4_SAMPLINGTIME_COMMON_2 LL_ADC_SAMPLINGTIME_COMMON_2
#define ADC4_SAMPLINGTIME_COMMON_1 LL_ADC_SAMPLINGTIME_COMMON_1
#define ADC4_SAMPLINGTIME_COMMON_2 LL_ADC_SAMPLINGTIME_COMMON_2
#define ADC4_SAMPLINGTIME_COMMON_1 LL_ADC_SAMPLINGTIME_COMMON_1
#define ADC4_SAMPLINGTIME_COMMON_2 LL_ADC_SAMPLINGTIME_COMMON_2
#define ADC4_SAMPLINGTIME_COMMON_1 LL_ADC_SAMPLINGTIME_COMMON_1
#define ADC4_SAMPLINGTIME_COMMON_2 LL_ADC_SAMPLINGTIME_COMMON_2
#define ADC4_SAMPLINGTIME_COMMON_1 LL_ADC_SAMPLINGTIME_COMMON_1
#define ADC4_SAMPLINGTIME_COMMON_2 LL_ADC_SAMPLINGTIME_COMMON_2
#define ADC4_SAMPLINGTIME_COMMON_1 LL_ADC_SAMPLINGTIME_COMMON_1
#define ADC4_SAMPLINGTIME_COMMON_2 LL_ADC_SAMPLINGTIME_COMMON_2
#define ADC4_SAMPLINGTIME_COMMON_1 LL_ADC_SAMPLINGTIME_COMMON_1
#define ADC4_SAMPLINGTIME_COMMON_2 LL_ADC_SAMPLINGTIME_COMMON_2
#define ADC4_SAMPLINGTIME_COMMON_1 LL_ADC_SAMPLINGTIME_COMMON_1
#define ADC4_SAMPLINGTIME_COMMON_2 LL_ADC_SAMPLINGTIME_COMMON_2
#define ADC4_SAMPLINGTIME_COMMON_1 LL_ADC_SAMPLINGTIME_COMMON_1
#define ADC4_SAMPLINGTIME_COMMON_2 LL_ADC_SAMPLINGTIME_COMMON_2
#define ADC4_SAMPLINGTIME_COMMON_1 LL_ADC_SAMPLINGTIME_COMMON_1
#define ADC4_SAMPLINGTIME_COMMON_2 LL_ADC_SAMPLINGTIME_COMMON_2
#define ADC4_SAMPLINGTIME_COMMON_1 LL_ADC_SAMPLINGTIME_COMMON_1
#define ADC4_SAMPLINGTIME_COMMON_2 LL_ADC_SAMPLINGTIME_COMMON_2
#define ADC4_SAMPLINGTIME_COMMON_1 LL_ADC_SAMPLINGTIME_COMMON_1
#define ADC4_SAMPLINGTIME_COMMON_2 LL_ADC_SAMPLINGTIME_COMMON_2
#define ADC4_SAMPLINGTIME_COMMON_1 LL_ADC_SAMPLINGTIME_COMMON_1
#define ADC4_SAMPLINGTIME_COMMON_2 LL_ADC_SAMPLINGTIME_COMMON_2
#define ADC4_SAMPLINGTIME_COMMON_1 LL_ADC_SAMPLINGTIME_COMMON_1
#define ADC4_SAMPLINGTIME_COMMON_2 LL_ADC_SAMPLINGTIME_COMMON_2
#define ADC4_SAMPLINGTIME_COMMON_1 LL_ADC_SAMPLINGTIME_COMMON_1
#define ADC4_SAMPLINGTIME_COMMON_2 LL_ADC_SAMPLINGTIME_COMMON_2
#define ADC4_SAMPLINGTIME_COMMON_1 LL_ADC_SAMPLINGTIME_COMMON_1
#define ADC4_SAMPLINGTIME_COMMON_2 LL_ADC_SAMPLINGTIME_COMMON_2
#define ADC4_SAMPLINGTIME_COMMON_1 LL_ADC_SAMPLINGTIME_COMMON_1
#define ADC4_SAMPLINGTIME_COMMON_2 LL_ADC_SAMPLINGTIME_COMMON_2
#define ADC4_SAMPLINGTIME_COMMON_1 LL_ADC_SAMPLINGTIME_COMMON_1
#define ADC4_SAMPLINGTIME_COMMON_2 LL_ADC_SAMPLINGTIME_COMMON_2
#define ADC4_SAMPLINGTIME_COMMON_1 LL_ADC_SAMPLINGTIME_COMMON_1
#define ADC4_SAMPLINGTIME_COMMON_2 LL_ADC_SAMPLINGTIME_COMMON_2
#define ADC4_SAMPLINGTIME_COMMON_1 LL_ADC_SAMPLINGTIME_COMMON_1
#define ADC4_SAMPLINGTIME_COMMON_2 LL_ADC_SAMPLINGTIME_COMMON_2
#define ADC4_SAMPLINGTIME_COMMON_1 LL_ADC_SAMPLINGTIME_COMMON_1
#define ADC4_SAMPLINGTIME_COMMON_2 LL_ADC_SAMPLINGTIME_COMMON_2
#define ADC4_SAMPLINGTIME_COMMON_1 LL_ADC_SAMPLINGTIME_COMMON_1
#define ADC4_SAMPLINGTIME_COMMON_2 LL_ADC_SAMPLINGTIME_COMMON_2
#define ADC4_SAMPLINGTIME_COMMON_1 LL_ADC_SAMPLINGTIME_COMMON_1
#define ADC4_SAMPLINGTIME_COMMON_2 LL_ADC_SAMPLINGTIME_COMMON_2
#define ADC4_SAMPLINGTIME_COMMON_1 LL_ADC_SAMPLINGTIME_COMMON_1
#define ADC4_SAMPLINGTIME_COMMON_2 LL_ADC_SAMPLINGTIME_COMMON_2
#define ADC4_SAMPLINGTIME_COMMON_1 LL_ADC_SAMPLINGTIME_COMMON_1
#define ADC4_SAMPLINGTIME_COMMON_2 LL_ADC_SAMPLINGTIME_COMMON_2
#define ADC4_SAMPLINGTIME_COMMON_1 LL_ADC_SAMPLINGTIME_COMMON_1
#define ADC4_SAMPLINGTIME_COMMON_2 LL_ADC_SAMPLINGTIME_COMMON_2
#define ADC4_SAMPLINGTIME_COMMON_1 LL_ADC_SAMPLINGTIME_COMMON_1
#define ADC4_SAMPLINGTIME_COMMON_2 LL_ADC_SAMPLINGTIME_COMMON_2
#define ADC4_SAMPLINGTIME_COMMON_1 LL_ADC_SAMPLINGTIME_COMMON_1
#define ADC4_SAMPLINGTIME_COMMON_2 LL_ADC_SAMPLINGTIME_COMMON_2
#define ADC4_SAMPLINGTIME_COMMON_1 LL_ADC_SAMPLINGTIME_COMMON_1
#define ADC4_SAMPLINGTIME_COMMON_2 LL_ADC_SAMPLINGTIME_COMMON_2
#define ADC4_SAMPLINGTIME_COMMON_1 LL_ADC_SAMPLINGTIME_COMMON_1
#define ADC4_SAMPLINGTIME_COMMON_2 LL_ADC_SAMPLINGTIME_COMMON_2
#define ADC4_SAMPLINGTIME_COMMON_1 LL_ADC_SAMPLINGTIME_COMMON_1
#define ADC4_SAMPLINGTIME_COMMON_2 LL_ADC_SAMPLINGTIME_COMMON_2
#define ADC4_SAMPLINGTIME_COMMON_1 LL_ADC_SAMPLINGTIME_COMMON_1
#define ADC4_SAMPLINGTIME_COMMON_2 LL_ADC_SAMPLINGTIME_COMMON_2
#define ADC4_SAMPLINGTIME_COMMON_1 LL_ADC_SAMPLINGTIME_COMMON_1
#define ADC4_SAMPLINGTIME_COMMON_2 LL_ADC_SAMPLINGTIME_COMMON_2
#define ADC4_SAMPLINGTIME_COMMON_1 LL_ADC_SAMPLINGTIME_COMMON_1
#define ADC4_SAMPLINGTIME_COMMON_2 LL_ADC_SAMPLINGTIME_COMMON_2
#define ADC4_SAMPLINGTIME_COMMON_1 LL_ADC_SAMPLINGTIME_COMMON_1
#define ADC4_SAMPLINGTIME_COMMON_2 LL_ADC_SAMPLINGTIME_COMMON_2
#define ADC4_SAMPLINGTIME_COMMON_1 LL_ADC_SAMPLINGTIME_COMMON_1
#define ADC4_SAMPLINGTIME_COMMON_2 LL_ADC_SAMPLINGTIME_COMMON_2
#define ADC4_SAMPLINGTIME_COMMON_1 LL_ADC_SAMPLINGTIME_COMMON_1
#define ADC4_SAMPLINGTIME_COMMON_2 LL_ADC_SAMPLINGTIME_COMMON_2
#define ADC4_SAMPLINGTIME_COMMON_1 LL_ADC_SAMPLINGTIME_COMMON_1
#define ADC4_SAMPLINGTIME_COMMON_2 LL_ADC_SAMPLINGTIME_COMMON_2
#define ADC4_SAMPLINGTIME_COMMON_1 LL_ADC_SAMPLINGTIME_COMMON_1
#define ADC4_SAMPLINGTIME_COMMON_2 LL_ADC_SAMPLINGTIME_COMMON_2
#define ADC4_SAMPLINGTIME_COMMON_1 LL_ADC_SAMPLINGTIME_COMMON_1
#define ADC4_SAMPLINGTIME_COMMON_2 LL_ADC_SAMPLINGTIME_COMMON_2
#define ADC4_SAMPLINGTIME_COMMON_1 LL_ADC_SAMPLINGTIME_COMMON_1
#define ADC4_SAMPLINGTIME_COMMON_2 LL_ADC_SAMPLINGTIME_COMMON_2
#define ADC4_SAMPLINGTIME_COMMON_1 LL_ADC_SAMPLINGTIME_COMMON_1
#define ADC4_SAMPLINGTIME_COMMON_2 LL_ADC_SAMPLINGTIME_COMMON_2
#define ADC4_SAMPLINGTIME_COMMON_1 LL_ADC_SAMPLINGTIME_COMMON_1
#define ADC4_SAMPLINGTIME_COMMON_2 LL_ADC_SAMPLINGTIME_COMMON_2
#define ADC4_SAMPLINGTIME_COMMON_1 LL_ADC_SAMPLINGTIME_COMMON_1
#define ADC4_SAMPLINGTIME_COMMON_2 LL_ADC_SAMPLINGTIME_COMMON_2
#define ADC4_SAMPLINGTIME_COMMON_1 LL_ADC_SAMPLINGTIME_COMMON_1
#define ADC4_SAMPLINGTIME_COMMON_2 LL_ADC_SAMPLINGTIME_COMMON_2
#define ADC4_SAMPLINGTIME_COMMON_1 LL_ADC_SAMPLINGTIME_COMMON_1
#define ADC4_SAMPLINGTIME_COMMON_2 LL_ADC_SAMPLINGTIME_COMMON_2
#define ADC4_SAMPLINGTIME_COMMON_1 LL_ADC_SAMPLINGTIME_COMMON_1
#define ADC4_SAMPLINGTIME_COMMON_2 LL_ADC_SAMPLINGTIME_COMMON_2
#define ADC4_SAMPLINGTIME_COMMON_1 LL_ADC_SAMPLINGTIME_COMMON_1
#define ADC4_SAMPLINGTIME_COMMON_2 LL_ADC_SAMPLINGTIME_COMMON_2
#define ADC4_SAMPLINGTIME_COMMON_1 LL_ADC_SAMPLINGTIME_COMMON_1
#define ADC4_SAMPLINGTIME_COMMON_2 LL_ADC_SAMPLINGTIME_COMMON_2
#define ADC4_SAMPLINGTIME_COMMON_1 LL_ADC_SAMPLINGTIME_COMMON_1
#define ADC4_SAMPLINGTIME_COMMON_2 LL_ADC_SAMPLINGTIME_COMMON_2
#define ADC4_SAMPLINGTIME_COMMON_1 LL_ADC_SAMPLINGTIME_COMMON_1
#define ADC4_SAMPLINGTIME_COMMON_2 LL_ADC_SAMPLINGTIME_COMMON_2
#define ADC4_SAMPLINGTIME_COMMON_1 LL_ADC_SAMPLINGTIME_COMMON_1
#define ADC4_SAMPLINGTIME_COMMON_2 LL_ADC_SAMPLINGTIME_COMMON_2
#define ADC4_SAMPLINGTIME_COMMON_1 LL_ADC_SAMPLINGTIME_COMMON_1
#define ADC4_SAMPLINGTIME_COMMON_2 LL_ADC_SAMPLINGTIME_COMMON_2
#define ADC4_SAMPLINGTIME_COMMON_1 LL_ADC_SAMPLINGTIME_COMMON_1
#define ADC4_SAMPLINGTIME_COMMON_2 LL_ADC_SAMPLINGTIME_COMMON_2
#define ADC4_SAMPLINGTIME_COMMON_1 LL_ADC_SAMPLINGTIME_COMMON_1
#define ADC4_SAMPLINGTIME_COMMON_2 LL_ADC_SAMPLINGTIME_COMMON_2
#define ADC4_SAMPLINGTIME_COMMON_1 LL_ADC_SAMPLINGTIME_COMMON_1
#define ADC4_SAMPLINGTIME_COMMON_2 LL_ADC_SAMPLINGTIME_COMMON_2
#define ADC4_SAMPLINGTIME_COMMON_1 LL_ADC_SAMPLINGTIME_COMMON_1
#define ADC4_SAMPLINGTIME_COMMON_2 LL_ADC_SAMPLINGTIME_COMMON_2
#define ADC4_SAMPLINGTIME_COMMON_1 LL_ADC_SAMPLINGTIME_COMMON_1
#define ADC4_SAMPLINGTIME_COMMON_2 LL_ADC_SAMPLINGTIME_COMMON_2
#define ADC4_SAMPLINGTIME_COMMON_1 LL_ADC_SAMPLINGTIME_COMMON_1
#define ADC4_SAMPLINGTIME_COMMON_2 LL_ADC_SAMPLINGTIME_COMMON_2
#define ADC4_SAMPLINGTIME_COMMON_1 LL_ADC_SAMPLINGTIME_COMMON_1
#define ADC4_SAMPLINGTIME_COMMON_2 LL_ADC_SAMPLINGTIME_COMMON_2
#define ADC4_SAMPLINGTIME_COMMON_1 LL_ADC_SAMPLINGTIME_COMMON_1
#define ADC4_SAMPLINGTIME_COMMON_2 LL_ADC_SAMPLINGTIME_COMMON_2
#define ADC4_SAMPLINGTIME_COMMON_1 LL_ADC_SAMPLINGTIME_COMMON_1
#define ADC4_SAMPLINGTIME_COMMON_2 LL_ADC_SAMPLINGTIME_COMMON_2
#define ADC4_SAMPLINGTIME_COMMON_1 LL_ADC_SAMPLINGTIME_COMMON_1
#define ADC4_SAMPLINGTIME_COMMON_2 LL_ADC_SAMPLINGTIME_COMMON_2
#define ADC4_SAMPLINGTIME_COMMON_1 LL_ADC_SAMPLINGTIME_COMMON_1
#define ADC4_SAMPLINGTIME_COMMON_2 LL_ADC_SAMPLINGTIME_COMMON_2
#define ADC4_SAMPLINGTIME_COMMON_1 LL_ADC_SAMPLINGTIME_COMMON_1
#define ADC4_SAMPLINGTIME_COMMON_2 LL_ADC_SAMPLINGTIME_COMMON_2
#define ADC4_SAMPLINGTIME_COMMON_1 LL_ADC_SAMPLINGTIME_COMMON_1
#define ADC4_SAMPLINGTIME_COMMON_2 LL_ADC_SAMPLINGTIME_COMMON_2
#define ADC4_SAMPLINGTIME_COMMON_1 LL_ADC_SAMPLINGTIME_COMMON_1
#define ADC4_SAMPLINGTIME_COMMON_2 LL_ADC_SAMPLINGTIME_COMMON_2
#define ADC4_SAMPLINGTIME_COMMON_1 LL_ADC_SAMPLINGTIME_COMMON_1
#define ADC4_SAMPLINGTIME_COMMON_2 LL_ADC_SAMPLINGTIME_COMMON_2
#define ADC4_SAMPLINGTIME_COMMON_1 LL_ADC_SAMPLINGTIME_COMMON_1
#define ADC4_SAMPLINGTIME_COMMON_2 LL_ADC_SAMPLINGTIME_COMMON_2
#define ADC4_SAMPLINGTIME_COMMON_1 LL_ADC_SAMPLINGTIME_COMMON_1
#define ADC4_SAMPLINGTIME_COMMON_2 LL_ADC_SAMPLINGTIME_COMMON_2
#define ADC4_SAMPLINGTIME_COMMON_1 LL_ADC_SAMPLINGTIME_COMMON_1
#define ADC4_SAMPLINGTIME_COMMON_2 LL_ADC_SAMPLINGTIME_COMMON_2
#define ADC4_SAMPLINGTIME_COMMON_1 LL_ADC_SAMPLINGTIME_COMMON_1
#define ADC4_SAMPLINGTIME_COMMON_2 LL_ADC_SAMPLINGTIME_COMMON_2
#define ADC4_SAMPLINGTIME_COMMON_1 LL_ADC_SAMPLINGTIME_COMMON_1
#define ADC4_SAMPLINGTIME_COMMON_2 LL_ADC_SAMPLINGTIME_COMMON_2
#define ADC4_SAMPLINGTIME_COMMON_1 LL_ADC_SAMPLINGTIME_COMMON_1
#define ADC4_SAMPLINGTIME_COMMON_2 LL_ADC_SAMPLINGTIME_COMMON_2
#define ADC4_SAMPLINGTIME_COMMON_1 LL_ADC_SAMPLINGTIME_COMMON_1
#define ADC4_SAMPLINGTIME_COMMON_2 LL_ADC_SAMPLINGTIME_COMMON_2
#define ADC4_SAMPLINGTIME_COMMON_1 LL_ADC_SAMPLINGTIME_COMMON_1
#define ADC4_SAMPLINGTIME_COMMON_2 LL_ADC_SAMPLINGTIME_COMMON_2
#define ADC4_SAMPLINGTIME_COMMON_1 LL_ADC_SAMPLINGTIME_COMMON_1
#define ADC4_SAMPLINGTIME_COMMON_2 LL_ADC_SAMPLINGTIME_COMMON_2
#define ADC4_SAMPLINGTIME_COMMON_1 LL_ADC_SAMPLINGTIME_COMMON_1
#define ADC4_SAMPLINGTIME_COMMON_2 LL_ADC_SAMPLINGTIME_COMMON_2
#define ADC4_SAMPLINGTIME_COMMON_1 LL_ADC_SAMPLINGTIME_COMMON_1
#define ADC4_SAMPLINGTIME_COMMON_2 LL_ADC_SAMPLINGTIME_COMMON_2
#define ADC4_SAMPLINGTIME_COMMON_1 LL_ADC_SAMPLINGTIME_COMMON_1
#define ADC4_SAMPLINGTIME_COMMON_2 LL_ADC_SAMPLINGTIME_COMMON_2
#define ADC4_SAMPLINGTIME_COMMON_1 LL_ADC_SAMPLINGTIME_COMMON_1
#define ADC4_SAMPLINGTIME_COMMON_2 LL_ADC_SAMPLINGTIME_COMMON_2
#define ADC4_SAMPLINGTIME_COMMON_1 LL_ADC_SAMPLINGTIME_COMMON_1
#define ADC4_SAMPLINGTIME_COMMON_2 LL_ADC_SAMPLINGTIME_COMMON_2
#define ADC4_SAMPLINGTIME_COMMON_1 LL_ADC_SAMPLINGTIME_COMMON_1
#define ADC4_SAMPLINGTIME_COMMON_2 LL_ADC_SAMPLINGTIME_COMMON_2
#define ADC4_SAMPLINGTIME_COMMON_1 LL_ADC_SAMPLINGTIME_COMMON_1
#define ADC4_SAMPLINGTIME_COMMON_2 LL_ADC_SAMPLINGTIME_COMMON_2
#define ADC4_SAMPLINGTIME_COMMON_1 LL_ADC_SAMPLINGTIME_COMMON_1
#define ADC4_SAMPLINGTIME_COMMON_2 LL_ADC_SAMPLINGTIME_COMMON_2
#define ADC4_SAMPLINGTIME_COMMON_1 LL_ADC_SAMPLINGTIME_COMMON_1
#define ADC4_SAMPLINGTIME_COMMON_2 LL_ADC_SAMPLINGTIME_COMMON_2
#define ADC4_SAMPLINGTIME_COMMON_1 LL_ADC_SAMPLINGTIME_COMMON_1
#define ADC4_SAMPLINGTIME_COMMON_2 LL_ADC_SAMPLINGTIME_COMMON_2
#define ADC4_SAMPLINGTIME_COMMON_1 LL_ADC_SAMPLINGTIME_COMMON_1
#define ADC4_SAMPLINGTIME_COMMON_2 LL_ADC_SAMPLINGTIME_COMMON_2
#define ADC4_SAMPLINGTIME_COMMON_1 LL_ADC_SAMPLINGTIME_COMMON_1
#define ADC4_SAMPLINGTIME_COMMON_2 LL_ADC_SAMPLINGTIME_COMMON_2
#define ADC4_SAMPLINGTIME_COMMON_1 LL_ADC_SAMPLINGTIME_COMMON_1
#define ADC4_SAMPLINGTIME_COMMON_2 LL_ADC_SAMPLINGTIME_COMMON_2
#define ADC4_SAMPLINGTIME_COMMON_1 LL_ADC_SAMPLINGTIME_COMMON_1
#define ADC4_SAMPLINGTIME_COMMON_2 LL_ADC_SAMPLINGTIME_COMMON_2
#define ADC4_SAMPLINGTIME_COMMON_1 LL_ADC_SAMPLINGTIME_COMMON_1
#define ADC4_SAMPLINGTIME_COMMON_2 LL_ADC_SAMPLINGTIME_COMMON_2
#define ADC4_SAMPLINGTIME_COMMON_1 LL_ADC_SAMPLINGTIME_COMMON_1
#define ADC4_SAMPLINGTIME_COMMON_2 LL_ADC_SAMPLINGTIME_COMMON_2
#define ADC4_SAMPLINGTIME_COMMON_1 LL_ADC_SAMPLINGTIME_COMMON_1
#define ADC4_SAMPLINGTIME_COMMON_2 LL_ADC_SAMPLINGTIME_COMMON_2
#define ADC4_SAMPLINGTIME_COMMON_1 LL_ADC_SAMPLINGTIME_COMMON_1
#define ADC4_SAMPLINGTIME_COMMON_2 LL_ADC_SAMPLINGTIME_COMMON_2
#define ADC4_SAMPLINGTIME_COMMON_1 LL_ADC_SAMPLINGTIME_COMMON_1
#define ADC4_SAMPLINGTIME_COMMON_2 LL_ADC_SAMPLINGTIME_COMMON_2
#define ADC4_SAMPLINGTIME_COMMON_1 LL_ADC_SAMPLINGTIME_COMMON_1
#define ADC4_SAMPLINGTIME_COMMON_2 LL_ADC_SAMPLINGTIME_COMMON_2
#define ADC4_SAMPLINGTIME_COMMON_1 LL_ADC_SAMPLINGTIME_COMMON_1
#define ADC4_SAMPLINGTIME_COMMON_2 LL_ADC_SAMPLINGTIME_COMMON_2
#define ADC4_SAMPLINGTIME_COMMON_1 LL_ADC_SAMPLINGTIME_COMMON_1
#define ADC4_SAMPLINGTIME_COMMON_2 LL_ADC_SAMPLINGTIME_COMMON_2
#define ADC4_SAMPLINGTIME_COMMON_1 LL_ADC_SAMPLINGTIME_COMMON_1
#define ADC4_SAMPLINGTIME_COMMON_2 LL_ADC_SAMPLINGTIME_COMMON_2
#define ADC4_SAMPLINGTIME_COMMON_1 LL_ADC_SAMPLINGTIME_COMMON_1
#define ADC4_SAMPLINGTIME_COMMON_2 LL_ADC_SAMPLINGTIME_COMMON_2
#define ADC4_SAMPLINGTIME_COMMON_1 LL_ADC_SAMPLINGTIME_COMMON_1
#define ADC4_SAMPLINGTIME_COMMON_2 LL_ADC_SAMPLINGTIME_COMMON_2
#define ADC4_SAMPLINGTIME_COMMON_1 LL_ADC_SAMPLINGTIME_COMMON_1
#define ADC4_SAMPLINGTIME_COMMON_2 LL_ADC_SAMPLINGTIME_COMMON_2
#define ADC4_SAMPLINGTIME_COMMON_1 LL_ADC_SAMPLINGTIME_COMMON_1
#define ADC4_SAMPLINGTIME_COMMON_2 LL_ADC_SAMPLINGTIME_COMMON_2
#define ADC4_SAMPLINGTIME_COMMON_1 LL_ADC_SAMPLINGTIME_COMMON_1
#define ADC4_SAMPLINGTIME_COMMON_2 LL_ADC_SAMPLINGTIME_COMMON_2
#define ADC4_SAMPLINGTIME_COMMON_1 LL_ADC_SAMPLINGTIME_COMMON_1
#define ADC4_SAMPLINGTIME_COMMON_2 LL_ADC_SAMPLINGTIME_COMMON_2
#define ADC4_SAMPLINGTIME_COMMON_1 LL_ADC_SAMPLINGTIME_COMMON_1
#define ADC4_SAMPLINGTIME_COMMON_2 LL_ADC_SAMPLINGTIME_COMMON_2
#define ADC4_SAMPLINGTIME_COMMON_1 LL_ADC_SAMPLINGTIME_COMMON_1
#define ADC4_SAMPLINGTIME_COMMON_2 LL_ADC_SAMPLINGTIME_COMMON_2
#define ADC4_SAMPLINGTIME_COMMON_1 LL_ADC_SAMPLINGTIME_COMMON_1
#define ADC4_SAMPLINGTIME_COMMON_2 LL_ADC_SAMPLINGTIME_COMMON_2
#define ADC4_SAMPLINGTIME_COMMON_1 LL_ADC_SAMPLINGTIME_COMMON_1
#define ADC4_SAMPLINGTIME_COMMON_2 LL_ADC_SAMPLINGTIME_COMMON_2
#define ADC4_SAMPLINGTIME_COMMON_1 LL_ADC_SAMPLINGTIME_COMMON_1
#define ADC4_SAMPLINGTIME_COMMON_2 LL_ADC_SAMPLINGTIME_COMMON_2
#define ADC4_SAMPLINGTIME_COMMON_1 LL_ADC_SAMPLINGTIME_COMMON_1
#define ADC4_SAMPLINGTIME_COMMON_2 LL_ADC_SAMPLINGTIME_COMMON_2
#define ADC4_SAMPLINGTIME_COMMON_1 LL_ADC_SAMPLINGTIME_COMMON_1
#define ADC4_SAMPLINGTIME_COMMON_2 LL_ADC_SAMPLINGTIME_COMMON_2
#define ADC4_SAMPLINGTIME_COMMON_1 LL_ADC_SAMPLINGTIME_COMMON_1
#define ADC4_SAMPLINGTIME_COMMON_2 LL_ADC_SAMPLINGTIME_COMMON_2
#define ADC4_SAMPLINGTIME_COMMON_1 LL_ADC_SAMPLINGTIME_COMMON_1
#define ADC4_SAMPLINGTIME_COMMON_2 LL_ADC_SAMPLINGTIME_COMMON_2
#define ADC4_SAMPLINGTIME_COMMON_1 LL_ADC_SAMPLINGTIME_COMMON_1
#define ADC4_SAMPLINGTIME_COMMON_2 LL_ADC_SAMPLINGTIME_COMMON_2
#define ADC4_SAMPLINGTIME_COMMON_1 LL_ADC_SAMPLINGTIME_COMMON_1
#define ADC4_SAMPLINGTIME_COMMON_2 LL_ADC_SAMPLINGTIME_COMMON_2
#define ADC4_SAMPLINGTIME_COMMON_1 LL_ADC_SAMPLINGTIME_COMMON_1
#define ADC4_SAMPLINGTIME_COMMON_2 LL_ADC_SAMPLINGTIME_COMMON_2
#define ADC4_SAMPLINGTIME_COMMON_1 LL_ADC_SAMPLINGTIME_COMMON_1
#define ADC4_SAMPLINGTIME_COMMON_2 LL_ADC_SAMPLINGTIME_COMMON_2
#define ADC4_SAMPLINGTIME_COMMON_1 LL_ADC_SAMPLINGTIME_COMMON_1
#define ADC4_SAMPLINGTIME_COMMON_2 LL_ADC_SAMPLINGTIME_COMMON_2
#define ADC4_SAMPLINGTIME_COMMON_1 LL_ADC_SAMPLINGTIME_COMMON_1
#define ADC4_SAMPLINGTIME_COMMON_2 LL_ADC_SAMPLINGTIME_COMMON_2
#define ADC4_SAMPLINGTIME_COMMON_1 LL_ADC_SAMPLINGTIME_COMMON_1
#define ADC4_SAMPLINGTIME_COMMON_2 LL_ADC_SAMPLINGTIME_COMMON_2
#define ADC4_SAMPLINGTIME_COMMON_1 LL_ADC_SAMPLINGTIME_COMMON_1
#define ADC4_SAMPLINGTIME_COMMON_2 LL_ADC_SAMPLINGTIME_COMMON_2
#define ADC4_SAMPLINGTIME_COMMON_1 LL_ADC_SAMPLINGTIME_COMMON_1
#define ADC4_SAMPLINGTIME_COMMON_2 LL_ADC_SAMPLINGTIME_COMMON_2
#define ADC4_SAMPLINGTIME_COMMON_1 LL_ADC_SAMPLINGTIME_COMMON_1
#define ADC4_SAMPLINGTIME_COMMON_2 LL_ADC_SAMPLINGTIME_COMMON_2
#define ADC4_SAMPLINGTIME_COMMON_1 LL_ADC_SAMPLINGTIME_COMMON_1
#define ADC4_SAMPLINGTIME_COMMON_2 LL_ADC_SAMPLINGTIME_COMMON_2
#define ADC4_SAMPLINGTIME_COMMON_1 LL_ADC_SAMPLINGTIME_COMMON_1
#define ADC4_SAMPLINGTIME_COMMON_2 LL_ADC_SAMPLINGTIME_COMMON_2
#define ADC4_SAMPLINGTIME_COMMON_1 LL_ADC_SAMPLINGTIME_COMMON_1
#define ADC4_SAMPLINGTIME_COMMON_2 LL_ADC_SAMPLINGTIME_COMMON_2
#define ADC4_SAMPLINGTIME_COMMON_1 LL_ADC_SAMPLINGTIME_COMMON_1
#define ADC4_SAMPLINGTIME_COMMON_2 LL_ADC_SAMPLINGTIME_COMMON_2
#define ADC4_SAMPLINGTIME_COMMON_1 LL_ADC_SAMPLINGTIME_COMMON_1
#define ADC4_SAMPLINGTIME_COMMON_2 LL_ADC_SAMPLINGTIME_COMMON_2
#define ADC4_SAMPLINGTIME_COMMON_1 LL_ADC_SAMPLINGTIME_COMMON_1
#define ADC4_SAMPLINGTIME_COMMON_2 LL_ADC_SAMPLINGTIME_COMMON_2
#define ADC4_SAMPLINGTIME_COMMON_1 LL_ADC_SAMPLINGTIME_COMMON_1
#define ADC4_SAMPLINGTIME_COMMON_2 LL_ADC_SAMPLINGTIME_COMMON_2
#define ADC4_SAMPLINGTIME_COMMON_1 LL_ADC_SAMPLINGTIME_COMMON_1
#define ADC4_SAMPLINGTIME_COMMON_2 LL_ADC_SAMPLINGTIME_COMMON_2
#define ADC4_SAMPLINGTIME_COMMON_1 LL_ADC_SAMPLINGTIME_COMMON_1
#define ADC4_SAMPLINGTIME_COMMON_2 LL_ADC_SAMPLINGTIME_COMMON_2
#define ADC4_SAMPLINGTIME_COMMON_1 LL_ADC_SAMPLINGTIME_COMMON_1
#define ADC4_SAMPLINGTIME_COMMON_2 LL_ADC_SAMPLINGTIME_COMMON_2
#define ADC4_SAMPLINGTIME_COMMON_1 LL_ADC_SAMPLINGTIME_COMMON_1
#define ADC4_SAMPLINGTIME_COMMON_2 LL_ADC_SAMPLINGTIME_COMMON_2
#define ADC4_SAMPLINGTIME_COMMON_1 LL_ADC_SAMPLINGTIME_COMMON_1
#define ADC4_SAMPLINGTIME_COMMON_2 LL_ADC_SAMPLINGTIME_COMMON_2
#define ADC4_SAMPLINGTIME_COMMON_1 LL_ADC_SAMPLINGTIME_COMMON_1
#define ADC4_SAMPLINGTIME_COMMON_2 LL_ADC_SAMPLINGTIME_COMMON_2
#define ADC4_SAMPLINGTIME_COMMON_1 LL_ADC_SAMPLINGTIME_COMMON_1
#define ADC4_SAMPLINGTIME_COMMON_2 LL_ADC_SAMPLINGTIME_COMMON_2
#define ADC4_SAMPLINGTIME_COMMON_1 LL_ADC_SAMPLINGTIME_COMMON_1
#define ADC4_SAMPLINGTIME_COMMON_2 LL_ADC_SAMPLINGTIME_COMMON_2
#define ADC4_SAMPLINGTIME_COMMON_1 LL_ADC_SAMPLINGTIME_COMMON_1
#define ADC4_SAMPLINGTIME_COMMON_2 LL_ADC_SAMPLINGTIME_COMMON_2
#define ADC4_SAMPLINGTIME_COMMON_1 LL_ADC_SAMPLINGTIME_COMMON_1
#define ADC4_SAMPLINGTIME_COMMON_2 LL_ADC_SAMPLINGTIME_COMMON_2
#define ADC4_SAMPLINGTIME_COMMON_1 LL_ADC_SAMPLINGTIME_COMMON_1
#define ADC4_SAMPLINGTIME_COMMON_2 LL_ADC_SAMPLINGTIME_COMMON_2
#define ADC4_SAMPLINGTIME_COMMON_1 LL_ADC_SAMPLINGTIME_COMMON_1
#define ADC4_SAMPLINGTIME_COMMON_2 LL_ADC_SAMPLINGTIME_COMMON_2
#define ADC4_SAMPLINGTIME_COMMON_1 LL_ADC_SAMPLINGTIME_COMMON_1
#define ADC4_SAMPLINGTIME_COMMON_2 LL_ADC_SAMPLINGTIME_COMMON_2
#define ADC4_SAMPLINGTIME_COMMON_1 LL_ADC_SAMPLINGTIME_COMMON_1
#define ADC4_SAMPLINGTIME_COMMON_2 LL_ADC_SAMPLINGTIME_COMMON_2
#define ADC4_SAMPLINGTIME_COMMON_1 LL_ADC_SAMPLINGTIME_COMMON_1
#define ADC4_SAMPLINGTIME_COMMON_2 LL_ADC_SAMPLINGTIME_COMMON_2
#define ADC4_SAMPLINGTIME_COMMON_1 LL_ADC_SAMPLINGTIME_COMMON_1
#define ADC4_SAMPLINGTIME_COMMON_2 LL_ADC_SAMPLINGTIME_COMMON_2
#define ADC4_SAMPLINGTIME_COMMON_1 LL_ADC_SAMPLINGTIME_COMMON_1
#define ADC4_SAMPLINGTIME_COMMON_2 LL_ADC_SAMPLINGTIME_COMMON_2
#define ADC4_SAMPLINGTIME_COMMON_1 LL_ADC_SAMPLINGTIME_COMMON_1
#define ADC4_SAMPLINGTIME_COMMON_2 LL_ADC_SAMPLINGTIME_COMMON_2
#define ADC4_SAMPLINGTIME_COMMON_1 LL_ADC_SAMPLINGTIME_COMMON_1
#define ADC4_SAMPLINGTIME_COMMON_2 LL_ADC_SAMPLINGTIME_COMMON_2
#define ADC4_SAMPLINGTIME_COMMON_1 LL_ADC_SAMPLINGTIME_COMMON_1
#define ADC4_SAMPLINGTIME_COMMON_2 LL_ADC_SAMPLINGTIME_COMMON_2
#define ADC4_SAMPLINGTIME_COMMON_1 LL_ADC_SAMPLINGTIME_COMMON_1
#define ADC4_SAMPLINGTIME_COMMON_2 LL_ADC_SAMPLINGTIME_COMMON_2
#define ADC4_SAMPLINGTIME_COMMON_1 LL_ADC_SAMPLINGTIME_COMMON_1
#define ADC4_SAMPLINGTIME_COMMON_2 LL_ADC_SAMPLINGTIME_COMMON_2
#define ADC4_SAMPLINGTIME_COMMON_1 LL_ADC_SAMPLINGTIME_COMMON_1
#define ADC4_SAMPLINGTIME_COMMON_2 LL_ADC_SAMPLINGTIME_COMMON_2
#define ADC4_SAMPLINGTIME_COMMON_1 LL_ADC_SAMPLINGTIME_COMMON_1
#define ADC4_SAMPLINGTIME_COMMON_2 LL_ADC_SAMPLINGTIME_COMMON_2
#define ADC4_SAMPLINGTIME_COMMON_1 LL_ADC_SAMPLINGTIME_COMMON_1
#define ADC4_SAMPLINGTIME_COMMON_2 LL_ADC_SAMPLINGTIME_COMMON_2
#define ADC4_SAMPLINGTIME_COMMON_1 LL_ADC_SAMPLINGTIME_COMMON_1
#define ADC4_SAMPLINGTIME_COMMON_2 LL_ADC_SAMPLINGTIME_COMMON_2
#define ADC4_SAMPLINGTIME_COMMON_1 LL_ADC_SAMPLINGTIME_COMMON_1
#define ADC4_SAMPLINGTIME_COMMON_2 LL_ADC_SAMPLINGTIME_COMMON_2
#define ADC4_SAMPLINGTIME_COMMON_1 LL_ADC_SAMPLINGTIME_COMMON_1
#define ADC4_SAMPLINGTIME_COMMON_2 LL_ADC_SAMPLINGTIME_COMMON_2
#define ADC4_SAMPLINGTIME_COMMON_1 LL_ADC_SAMPLINGTIME_COMMON_1
#define ADC4_SAMPLINGTIME_COMMON_2 LL_ADC_SAMPLINGTIME_COMMON_2
#define ADC4_SAMPLINGTIME_COMMON_1 LL_ADC_SAMPLINGTIME_COMMON_1
#define ADC4_SAMPLINGTIME_COMMON_2 LL_ADC_SAMPLINGTIME_COMMON_2
#define ADC4_SAMPLINGTIME_COMMON_1 LL_ADC_SAMPLINGTIME_COMMON_1
#define ADC4_SAMPLINGTIME_COMMON_2 LL_ADC_SAMPLINGTIME_COMMON_2
#define ADC4_SAMPLINGTIME_COMMON_1 LL_ADC_SAMPLINGTIME_COMMON_1
#define ADC4_SAMPLINGTIME_COMMON_2 LL_ADC_SAMPLINGTIME_COMMON_2
#define ADC4_SAMPLINGTIME_COMMON_1 LL_ADC_SAMPLINGTIME_COMMON_1
#define ADC4_SAMPLINGTIME_COMMON_2 LL_ADC_SAMPLINGTIME_COMMON_2
#define ADC4_SAMPLINGTIME_COMMON_1 LL_ADC_SAMPLINGTIME_COMMON_1
#define ADC4_SAMPLINGTIME_COMMON_2 LL_ADC_SAMPLINGTIME_COMMON_2
#define ADC4_SAMPLINGTIME_COMMON_1 LL_ADC_SAMPLINGTIME_COMMON_1
#define ADC4_SAMPLINGTIME_COMMON_2 LL_ADC_SAMPLINGTIME_COMMON_2
#define ADC4_SAMPLINGTIME_COMMON_1 LL_ADC_SAMPLINGTIME_COMMON_1
#define ADC4_SAMPLINGTIME_COMMON_2 LL_ADC_SAMPLINGTIME_COMMON_2
#define ADC4_SAMPLINGTIME_COMMON_1 LL_ADC_SAMPLINGTIME_COMMON_1
#define ADC4_SAMPLINGTIME_COMMON_2 LL_ADC_SAMPLINGTIME_COMMON_2
#define ADC4_SAMPLINGTIME_COMMON_1 LL_ADC_SAMPLINGTIME_COMMON_1
#define ADC4_SAMPLINGTIME_COMMON_2 LL_ADC_SAMPLINGTIME_COMMON_2
#define ADC4_SAMPLINGTIME_COMMON_1 LL_ADC_SAMPLINGTIME_COMMON_1
#define ADC4_SAMPLINGTIME_COMMON_2 LL_ADC_SAMPLINGTIME_COMMON_2
#define ADC4_SAMPLINGTIME_COMMON_1 LL_ADC_SAMPLINGTIME_COMMON_1
#define ADC4_SAMPLINGTIME_COMMON_2 LL_ADC_SAMPLINGTIME_COMMON_2
#define ADC4_SAMPLINGTIME_COMMON_1 LL_ADC_SAMPLINGTIME_COMMON_1
#define ADC4_SAMPLINGTIME_COMMON_2 LL_ADC_SAMPLINGTIME_COMMON_2
#define ADC4_SAMPLINGTIME_COMMON_1 LL_ADC_SAMPLINGTIME_COMMON_1
#define ADC4_SAMPLINGTIME_COMMON_2 LL_ADC_SAMPLINGTIME_COMMON_2
#define ADC4_SAMPLINGTIME_COMMON_1 LL_ADC_SAMPLINGTIME_COMMON_1
#define ADC4_SAMPLINGTIME_COMMON_2 LL_ADC_SAMPLINGTIME_COMMON_2
#define ADC4_SAMPLINGTIME_COMMON_1 LL_ADC_SAMPLINGTIME_COMMON_1
#define ADC4_SAMPLINGTIME_COMMON_2 LL_ADC_SAMPLINGTIME_COMMON_2
#define ADC4_SAMPLINGTIME_COMMON_1 LL_ADC_SAMPLINGTIME_COMMON_1
#define ADC4_SAMPLINGTIME_COMMON_2 LL_ADC_SAMPLINGTIME_COMMON_2
#define ADC4_SAMPLINGTIME_COMMON_1 LL_ADC_SAMPLINGTIME_COMMON_1
#define ADC4_SAMPLINGTIME_COMMON_2 LL_ADC_SAMPLINGTIME_COMMON_2
#define ADC4_SAMPLINGTIME_COMMON_1 LL_ADC_SAMPLINGTIME_COMMON_1
#define ADC4_SAMPLINGTIME_COMMON_2 LL_ADC_SAMPLINGTIME_COMMON_2
#define ADC4_SAMPLINGTIME_COMMON_1 LL_ADC_SAMPLINGTIME_COMMON_1
#define ADC4_SAMPLINGTIME_COMMON_2 LL_ADC_SAMPLINGTIME_COMMON_2
#define ADC4_SAMPLINGTIME_COMMON_1 LL_ADC_SAMPLINGTIME_COMMON_1
#define ADC4_SAMPLINGTIME_COMMON_2 LL_ADC_SAMPLINGTIME_COMMON_2
#define ADC4_SAMPLINGTIME_COMMON_1 LL_ADC_SAMPLINGTIME_COMMON_1
#define ADC4_SAMPLINGTIME_COMMON_2 LL_ADC_SAMPLINGTIME_COMMON_2
#define ADC4_SAMPLINGTIME_COMMON_1 LL_ADC_SAMPLINGTIME_COMMON_1
#define ADC4_SAMPLINGTIME_COMMON_2 LL_ADC_SAMPLINGTIME_COMMON_2
#define ADC4_SAMPLINGTIME_COMMON_1 LL_ADC_SAMPLINGTIME_COMMON_1
#define ADC4_SAMPLINGTIME_COMMON_2 LL_ADC_SAMPLINGTIME_COMMON_2
#define ADC4_SAMPLINGTIME_COMMON_1 LL_ADC_SAMPLINGTIME_COMMON_1
#define ADC4_SAMPLINGTIME_COMMON_2 LL_ADC_SAMPLINGTIME_COMMON_2
#define ADC4_SAMPLINGTIME_COMMON_1 LL_ADC_SAMPLINGTIME_COMMON_1
#define ADC4_SAMPLINGTIME_COMMON_2 LL_ADC_SAMPLINGTIME_COMMON_2
#define ADC4_SAMPLINGTIME_COMMON_1 LL_ADC_SAMPLINGTIME_COMMON_1
#define ADC4_SAMPLINGTIME_COMMON_2 LL_ADC_SAMPLINGTIME_COMMON_2
#define ADC4_SAMPLINGTIME_COMMON_1 LL_ADC_SAMPLINGTIME_COMMON_1
#define ADC4_SAMPLINGTIME_COMMON_2 LL_ADC_SAMPLINGTIME_COMMON_2
#define ADC4_SAMPLINGTIME_COMMON_1 LL_ADC_SAMPLINGTIME_COMMON_1
#define ADC4_SAMPLINGTIME_COMMON_2 LL_ADC_SAMPLINGTIME_COMMON_2
#define ADC4_SAMPLINGTIME_COMMON_1 LL_ADC_SAMPLINGTIME_COMMON_1
#define ADC4_SAMPLINGTIME_COMMON_2 LL_ADC_SAMPLINGTIME_COMMON_2
#define ADC4_SAMPLINGTIME_COMMON_1 LL_ADC_SAMPLINGTIME_COMMON_1
#define ADC4_SAMPLINGTIME_COMMON_2 LL_ADC_SAMPLINGTIME_COMMON_2
#define ADC4_SAMPLINGTIME_COMMON_1 LL_ADC_SAMPLINGTIME_COMMON_1
#define ADC4_SAMPLINGTIME_COMMON_2 LL_ADC_SAMPLINGTIME_COMMON_2
#define ADC4_SAMPLINGTIME_COMMON_1 LL_ADC_SAMPLINGTIME_COMMON_1
#define ADC4_SAMPLINGTIME_COMMON_2 LL_ADC_SAMPLINGTIME_COMMON_2
#define ADC4_SAMPLINGTIME_COMMON_1 LL_ADC_SAMPLINGTIME_COMMON_1
#define ADC4_SAMPLINGTIME_COMMON_2 LL_ADC_SAMPLINGTIME_COMMON_2
#define ADC4_SAMPLINGTIME_COMMON_1 LL_ADC_SAMPLINGTIME_COMMON_1
#define ADC4_SAMPLINGTIME_COMMON_2 LL_ADC_SAMPLINGTIME_COMMON_2
#define ADC4_SAMPLINGTIME_COMMON_1 LL_ADC_SAMPLINGTIME_COMMON_1
#define ADC4_SAMPLINGTIME_COMMON_2 LL_ADC_SAMPLINGTIME_COMMON_2
#define ADC4_SAMPLINGTIME_COMMON_1 LL_ADC_SAMPLINGTIME_COMMON_1
#define ADC4_SAMPLINGTIME_COMMON_2 LL_ADC_SAMPLINGTIME_COMMON_2
#define ADC4_SAMPLINGTIME_COMMON_1 LL_ADC_SAMPLINGTIME_COMMON_1
#define ADC4_SAMPLINGTIME_COMMON_2 LL_ADC_SAMPLINGTIME_COMMON_2
#define ADC4_SAMPLINGTIME_COMMON_1 LL_ADC_SAMPLINGTIME_COMMON_1
#define ADC4_SAMPLINGTIME_COMMON_2 LL_ADC_SAMPLINGTIME_COMMON_2
#define ADC4_SAMPLINGTIME_COMMON_1 LL_ADC_SAMPLINGTIME_COMMON_1
#define ADC4_SAMPLINGTIME_COMMON_2 LL_ADC_SAMPLINGTIME_COMMON_2
#define ADC4_SAMPLINGTIME_COMMON_1 LL_ADC_SAMPLINGTIME_COMMON_1
#define ADC4_SAMPLINGTIME_COMMON_2 LL_ADC_SAMPLINGTIME_COMMON_2
#define ADC4_SAMPLINGTIME_COMMON_1 LL_ADC_SAMPLINGTIME_COMMON_1
#define ADC4_SAMPLINGTIME_COMMON_2 LL_ADC_SAMPLINGTIME_COMMON_2
#define ADC4_SAMPLINGTIME_COMMON_1 LL_ADC_SAMPLINGTIME_COMMON_1
#define ADC4_SAMPLINGTIME_COMMON_2 LL_ADC_SAMPLINGTIME_COMMON_2
#define ADC4_SAMPLINGTIME_COMMON_1 LL_ADC_SAMPLINGTIME_COMMON_1
#define ADC4_SAMPLINGTIME_COMMON_2 LL_ADC_SAMPLINGTIME_COMMON_2
#define ADC4_SAMPLINGTIME_COMMON_1 LL_ADC_SAMPLINGTIME_COMMON_1
#define ADC4_SAMPLINGTIME_COMMON_2 LL_ADC_SAMPLINGTIME_COMMON_2
#define ADC4_SAMPLINGTIME_COMMON_1 LL_ADC_SAMPLINGTIME_COMMON_1
#define ADC4_SAMPLINGTIME_COMMON_2 LL_ADC_SAMPLINGTIME_COMMON_2
#define ADC4_SAMPLINGTIME_COMMON_1 LL_ADC_SAMPLINGTIME_COMMON_1
#define ADC4_SAMPLINGTIME_COMMON_2 LL_ADC_SAMPLINGTIME_COMMON_2
#define ADC4_SAMPLINGTIME_COMMON_1 LL_ADC_SAMPLINGTIME_COMMON_1
#define ADC4_SAMPLINGTIME_COMMON_2 LL_ADC_SAMPLINGTIME_COMMON_2
#define ADC4_SAMPLINGTIME_COMMON_1 LL_ADC_SAMPLINGTIME_COMMON_1
#define ADC4_SAMPLINGTIME_COMMON_2 LL_ADC_SAMPLINGTIME_COMMON_2
#define ADC4_SAMPLINGTIME_COMMON_1 LL_ADC_SAMPLINGTIME_COMMON_1
#define ADC4_SAMPLINGTIME_COMMON_2 LL_ADC_SAMPLINGTIME_COMMON_2
#define ADC4_SAMPLINGTIME_COMMON_1 LL_ADC_SAMPLINGTIME_COMMON_1
#define ADC4_SAMPLINGTIME_COMMON_2 LL_ADC_SAMPLINGTIME_COMMON_2
#define ADC4_SAMPLINGTIME_COMMON_1 LL_ADC_SAMPLINGTIME_COMMON_1
#define ADC4_SAMPLINGTIME_COMMON_2 LL_ADC_SAMPLINGTIME_COMMON_2
#define ADC4_SAMPLINGTIME_COMMON_1 LL_ADC_SAMPLINGTIME_COMMON_1
#define ADC4_SAMPLINGTIME_COMMON_2 LL_ADC_SAMPLINGTIME_COMMON_2
#define ADC4_SAMPLINGTIME_COMMON_1 LL_ADC_SAMPLINGTIME_COMMON_1
#define ADC4_SAMPLINGTIME_COMMON_2 LL_ADC_SAMPLINGTIME_COMMON_2
#define ADC4_SAMPLINGTIME_COMMON_1 LL_ADC_SAMPLINGTIME_COMMON_1
#define ADC4_SAMPLINGTIME_COMMON_2 LL_ADC_SAMPLINGTIME_COMMON_2
#define ADC4_SAMPLINGTIME_COMMON_1 LL_ADC_SAMPLINGTIME_COMMON_1
#define ADC4_SAMPLINGTIME_COMMON_2 LL_ADC_SAMPLINGTIME_COMMON_2
#define ADC4_SAMPLINGTIME_COMMON_1 LL_ADC_SAMPLINGTIME_COMMON_1
#define ADC4_SAMPLINGTIME_COMMON_2 LL_ADC_SAMPLINGTIME_COMMON_2
#define ADC4_SAMPLINGTIME_COMMON_1 LL_ADC_SAMPLINGTIME_COMMON_1
#define ADC4_SAMPLINGTIME_COMMON_2 LL_ADC_SAMPLINGTIME_COMMON_2
#define ADC4_SAMPLINGTIME_COMMON_1 LL_ADC_SAMPLINGTIME_COMMON_1
#define ADC4_SAMPLINGTIME_COMMON_2 LL_ADC_SAMPLINGTIME_COMMON_2
#define ADC4_SAMPLINGTIME_COMMON_1 LL_ADC_SAMPLINGTIME_COMMON_1
#define ADC4_SAMPLINGTIME_COMMON_2 LL_ADC_SAMPLINGTIME_COMMON_2
#define ADC4_SAMPLINGTIME_COMMON_1 LL_ADC_SAMPLINGTIME_COMMON_1
#define ADC4_SAMPLINGTIME_COMMON_2 LL_ADC_SAMPLINGTIME_COMMON_2
#define ADC4_SAMPLINGTIME_COMMON_1 LL_ADC_SAMPLINGTIME_COMMON_1
#define ADC4_SAMPLINGTIME_COMMON_2 LL_ADC_SAMPLINGTIME_COMMON_2
#define ADC4_SAMPLINGTIME_COMMON_1 LL_ADC_SAMPLINGTIME_COMMON_1
#define ADC4_SAMPLINGTIME_COMMON_2 LL_ADC_SAMPLINGTIME_COMMON_2
#define ADC4_SAMPLINGTIME_COMMON_1 LL_ADC_SAMPLINGTIME_COMMON_1
#define ADC4_SAMPLINGTIME_COMMON_2 LL_ADC_SAMPLINGTIME_COMMON_2
#define ADC4_SAMPLINGTIME_COMMON_1 LL_ADC_SAMPLINGTIME_COMMON_1
#define ADC4_SAMPLINGTIME_COMMON_2 LL_ADC_SAMPLINGTIME_COMMON_2
#define ADC4_SAMPLINGTIME_COMMON_1 LL_ADC_SAMPLINGTIME_COMMON_1
#define ADC4_SAMPLINGTIME_COMMON_2 LL_ADC_SAMPLINGTIME_COMMON_2
#define ADC4_SAMPLINGTIME_COMMON_1 LL_ADC_SAMPLINGTIME_COMMON_1
#define ADC4_SAMPLINGTIME_COMMON_2 LL_ADC_SAMPLINGTIME_COMMON_2
#define ADC4_SAMPLINGTIME_COMMON_1 LL_ADC_SAMPLINGTIME_COMMON_1
#define ADC4_SAMPLINGTIME_COMMON_2 LL_ADC_SAMPLINGTIME_COMMON_2
#define ADC4_SAMPLINGTIME_COMMON_1 LL_ADC_SAMPLINGTIME_COMMON_1
#define ADC4_SAMPLINGTIME_COMMON_2 LL_ADC_SAMPLINGTIME_COMMON_2
#define ADC4_SAMPLINGTIME_COMMON_1 LL_ADC_SAMPLINGTIME_COMMON_1
#define ADC4_SAMPLINGTIME_COMMON_2 LL_ADC_SAMPLINGTIME_COMMON_2
#define ADC4_SAMPLINGTIME_COMMON_1 LL_ADC_SAMPLINGTIME_COMMON_1
#define ADC4_SAMPLINGTIME_COMMON_2 LL_ADC_SAMPLINGTIME_COMMON_2
#define ADC4_SAMPLINGTIME_COMMON_1 LL_ADC_SAMPLINGTIME_COMMON_1
#define ADC4_SAMPLINGTIME_COMMON_2 LL_ADC_SAMPLINGTIME_COMMON_2
#define ADC4_SAMPLINGTIME_COMMON_1 LL_ADC_SAMPLINGTIME_COMMON_1
#define ADC4_SAMPLINGTIME_COMMON_2 LL_ADC_SAMPLINGTIME_COMMON_2
#define ADC4_SAMPLINGTIME_COMMON_1 LL_ADC_SAMPLINGTIME_COMMON_1
#define ADC4_SAMPLINGTIME_COMMON_2 LL_ADC_SAMPLINGTIME_COMMON_2
#define ADC4_SAMPLINGTIME_COMMON_1 LL_ADC_SAMPLINGTIME_COMMON_1
#define ADC4_SAMPLINGTIME_COMMON_2 LL_ADC_SAMPLINGTIME_COMMON_2
#define ADC4_SAMPLINGTIME_COMMON_1 LL_ADC_SAMPLINGTIME_COMMON_1
#define ADC4_SAMPLINGTIME_COMMON_2 LL_ADC_SAMPLINGTIME_COMMON_2
#define ADC4_SAMPLINGTIME_COMMON_1 LL_ADC_SAMPLINGTIME_COMMON_1
#define ADC4_SAMPLINGTIME_COMMON_2 LL_ADC_SAMPLINGTIME_COMMON_2
#define ADC4_SAMPLINGTIME_COMMON_1 LL_ADC_SAMPLINGTIME_COMMON_1
#define ADC4_SAMPLINGTIME_COMMON_2 LL_ADC_SAMPLINGTIME_COMMON_2
#define ADC4_SAMPLINGTIME_COMMON_1 LL_ADC_SAMPLINGTIME_COMMON_1
#define ADC4_SAMPLINGTIME_COMMON_2 LL_ADC_SAMPLINGTIME_COMMON_2
#define ADC4_SAMPLINGTIME_COMMON_1 LL_ADC_SAMPLINGTIME_COMMON_1
#define ADC4_SAMPLINGTIME_COMMON_2 LL_ADC_SAMPLINGTIME_COMMON_2
#define ADC4_SAMPLINGTIME_COMMON_1 LL_ADC_SAMPLINGTIME_COMMON_1
#define ADC4_SAMPLINGTIME_COMMON_2 LL_ADC_SAMPLINGTIME_COMMON_2
#define ADC4_SAMPLINGTIME_COMMON_1 LL_ADC_SAMPLINGTIME_COMMON_1
#define ADC4_SAMPLINGTIME_COMMON_2 LL_ADC_SAMPLINGTIME_COMMON_2
#define ADC4_SAMPLINGTIME_COMMON_1 LL_ADC_SAMPLINGTIME_COMMON_1
#define ADC4_SAMPLINGTIME_COMMON_2 LL_ADC_SAMPLINGTIME_COMMON_2
#define ADC4_SAMPLINGTIME_COMMON_1 LL_ADC_SAMPLINGTIME_COMMON_1
#define ADC4_SAMPLINGTIME_COMMON_2 LL_ADC_SAMPLINGTIME_COMMON_2
#define ADC4_SAMPLINGTIME_COMMON_1 LL_ADC_SAMPLINGTIME_COMMON_1
#define ADC4_SAMPLINGTIME_COMMON_2 LL_ADC_SAMPLINGTIME_COMMON_2
#define ADC4_SAMPLINGTIME_COMMON_1 LL_ADC_SAMPLINGTIME_COMMON_1
#define ADC4_SAMPLINGTIME_COMMON_2 LL_ADC_SAMPLINGTIME_COMMON_2
#define ADC4_SAMPLINGTIME_COMMON_1 LL_ADC_SAMPLINGTIME_COMMON_1
#define ADC4_SAMPLINGTIME_COMMON_2 LL_ADC_SAMPLINGTIME_COMMON_2
#define ADC4_SAMPLINGTIME_COMMON_1 LL_ADC_SAMPLINGTIME_COMMON_1
#define ADC4_SAMPLINGTIME_COMMON_2 LL_ADC_SAMPLINGTIME_COMMON_2
#define ADC4_SAMPLINGTIME_COMMON_1 LL_ADC_SAMPLINGTIME_COMMON_1
#define ADC4_SAMPLINGTIME_COMMON_2 LL_ADC_SAMPLINGTIME_COMMON_2
#define ADC4_SAMPLINGTIME_COMMON_1 LL_ADC_SAMPLINGTIME_COMMON_1
#define ADC4_SAMPLINGTIME_COMMON_2 LL_ADC_SAMPLINGTIME_COMMON_2
#define ADC4_SAMPLINGTIME_COMMON_1 LL_ADC_SAMPLINGTIME_COMMON_1
#define ADC4_SAMPLINGTIME_COMMON_2 LL_ADC_SAMPLINGTIME_COMMON_2
#define ADC4_SAMPLINGTIME_COMMON_1 LL_ADC_SAMPLINGTIME_COMMON_1
#define ADC4_SAMPLINGTIME_COMMON_2 LL_ADC_SAMPLINGTIME_COMMON_2
#define ADC4_SAMPLINGTIME_COMMON_1 LL_ADC_SAMPLINGTIME_COMMON_1
#define ADC4_SAMPLINGTIME_COMMON_2 LL_ADC_SAMPLINGTIME_COMMON_2
#define ADC4_SAMPLINGTIME_COMMON_1 LL_ADC_SAMPLINGTIME_COMMON_1
#define ADC4_SAMPLINGTIME_COMMON_2 LL_ADC_SAMPLINGTIME_COMMON_2
#define ADC4_SAMPLINGTIME_COMMON_1 LL_ADC_SAMPLINGTIME_COMMON_1
#define ADC4_SAMPLINGTIME_COMMON_2 LL_ADC_SAMPLINGTIME_COMMON_2
#define ADC4_SAMPLINGTIME_COMMON_1 LL_ADC_SAMPLINGTIME_COMMON_1
#define ADC4_SAMPLINGTIME_COMMON_2 LL_ADC_SAMPLINGTIME_COMMON_2
#define ADC4_SAMPLINGTIME_COMMON_1 LL_ADC_SAMPLINGTIME_COMMON_1
#define ADC4_SAMPLINGTIME_COMMON_2 LL_ADC_SAMPLINGTIME_COMMON_2
#define ADC4_SAMPLINGTIME_COMMON_1 LL_ADC_SAMPLINGTIME_COMMON_1
#define ADC4_SAMPLINGTIME_COMMON_2 LL_ADC_SAMPLINGTIME_COMMON_2
#define ADC4_SAMPLINGTIME_COMMON_1 LL_ADC_SAMPLINGTIME_COMMON_1
#define ADC4_SAMPLINGTIME_COMMON_2 LL_ADC_SAMPLINGTIME_COMMON_2
#define ADC4_SAMPLINGTIME_COMMON_1 LL_ADC_SAMPLINGTIME_COMMON_1
#define ADC4_SAMPLINGTIME_COMMON_2 LL_ADC_SAMPLINGTIME_COMMON_2
#define ADC4_SAMPLINGTIME_COMMON_1 LL_ADC_SAMPLINGTIME_COMMON_1
#define ADC4_SAMPLINGTIME_COMMON_2 LL_ADC_SAMPLINGTIME_COMMON_2
#define ADC4_SAMPLINGTIME_COMMON_1 LL_ADC_SAMPLINGTIME_COMMON_1
#define ADC4_SAMPLINGTIME_COMMON_2 LL_ADC_SAMPLINGTIME_COMMON_2
#define ADC4_SAMPLINGTIME_COMMON_1 LL_ADC_SAMPLINGTIME_COMMON_1
#define ADC4_SAMPLINGTIME_COMMON_2 LL_ADC_SAMPLINGTIME_COMMON_2
#define ADC4_SAMPLINGTIME_COMMON_1 LL_ADC_SAMPLINGTIME_COMMON_1
#define ADC4_SAMPLINGTIME_COMMON_2 LL_ADC_SAMPLINGTIME_COMMON_2
#define ADC4_SAMPLINGTIME_COMMON_1 LL_ADC_SAMPLINGTIME_COMMON_1
#define ADC4_SAMPLINGTIME_COMMON_2 LL_ADC_SAMPLINGTIME_COMMON_2
#define ADC4_SAMPLINGTIME_COMMON_1 LL_ADC_SAMPLINGTIME_COMMON_1
#define ADC4_SAMPLINGTIME_COMMON_2 LL_ADC_SAMPLINGTIME_COMMON_2
#define ADC4_SAMPLINGTIME_COMMON_1 LL_ADC_SAMPLINGTIME_COMMON_1
#define ADC4_SAMPLINGTIME_COMMON_2 LL_ADC_SAMPLINGTIME_COMMON_2
#define ADC4_SAMPLINGTIME_COMMON_1 LL_ADC_SAMPLINGTIME_COMMON_1
#define ADC4_SAMPLINGTIME_COMMON_2 LL_ADC_SAMPLINGTIME_COMMON_2
#define ADC4_SAMPLINGTIME_COMMON_1 LL_ADC_SAMPLINGTIME_COMMON_1
#define ADC4_SAMPLINGTIME_COMMON_2 LL_ADC_SAMPLINGTIME_COMMON_2
#define ADC4_SAMPLINGTIME_COMMON_1 LL_ADC_SAMPLINGTIME_COMMON_1
#define ADC4_SAMPLINGTIME_COMMON_2 LL_ADC_SAMPLINGTIME_COMMON_2
#define ADC4_SAMPLINGTIME_COMMON_1 LL_ADC_SAMPLINGTIME_COMMON_1
#define ADC4_SAMPLINGTIME_COMMON_2 LL_ADC_SAMPLINGTIME_COMMON_2
#define ADC4_SAMPLINGTIME_COMMON_1 LL_ADC_SAMPLINGTIME_COMMON_1
#define ADC4_SAMPLINGTIME_COMMON_2 LL_ADC_SAMPLINGTIME_COMMON_2
#define ADC4_SAMPLINGTIME_COMMON_1 LL_ADC_SAMPLINGTIME_COMMON_1
#define ADC4_SAMPLINGTIME_COMMON_2 LL_ADC_SAMPLINGTIME_COMMON_2
#define ADC4_SAMPLINGTIME_COMMON_1 LL_ADC_SAMPLINGTIME_COMMON_1
#define ADC4_SAMPLINGTIME_COMMON_2 LL_ADC_SAMPLINGTIME_COMMON_2
#define ADC4_SAMPLINGTIME_COMMON_1 LL_ADC_SAMPLINGTIME_COMMON_1
#define ADC4_SAMPLINGTIME_COMMON_2 LL_ADC_SAMPLINGTIME_COMMON_2
#define ADC4_SAMPLINGTIME_COMMON_1 LL_ADC_SAMPLINGTIME_COMMON_1
#define ADC4_SAMPLINGTIME_COMMON_2 LL_ADC_SAMPLINGTIME_COMMON_2
#define ADC4_SAMPLINGTIME_COMMON_1 LL_ADC_SAMPLINGTIME_COMMON_1
#define ADC4_SAMPLINGTIME_COMMON_2 LL_ADC_SAMPLINGTIME_COMMON_2
#define ADC4_SAMPLINGTIME_COMMON_1 LL_ADC_SAMPLINGTIME_COMMON_1
#define ADC4_SAMPLINGTIME_COMMON_2 LL_ADC_SAMPLINGTIME_COMMON_2
#define ADC4_SAMPLINGTIME_COMMON_1 LL_ADC_SAMPLINGTIME_COMMON_1
#define ADC4_SAMPLINGTIME_COMMON_2 LL_ADC_SAMPLINGTIME_COMMON_2
#define ADC4_SAMPLINGTIME_COMMON_1 LL_ADC_SAMPLINGTIME_COMMON_1
#define ADC4_SAMPLINGTIME_COMMON_2 LL_ADC_SAMPLINGTIME_COMMON_2
#define ADC4_SAMPLINGTIME_COMMON_1 LL_ADC_SAMPLINGTIME_COMMON_1
#define ADC4_SAMPLINGTIME_COMMON_2 LL_ADC_SAMPLINGTIME_COMMON_2
#define ADC4_SAMPLINGTIME_COMMON_1 LL_ADC_SAMPLINGTIME_COMMON_1
#define ADC4_SAMPLINGTIME_COMMON_2 LL_ADC_SAMPLINGTIME_COMMON_2
#define ADC4_SAMPLINGTIME_COMMON_1 LL_ADC_SAMPLINGTIME_COMMON_1
#define ADC4_SAMPLINGTIME_COMMON_2 LL_ADC_SAMPLINGTIME_COMMON_2
#define ADC4_SAMPLINGTIME_COMMON_1 LL_ADC_SAMPLINGTIME_COMMON_1
#define ADC4_SAMPLINGTIME_COMMON_2 LL_ADC_SAMPLINGTIME_COMMON_2
#define ADC4_SAMPLINGTIME_COMMON_1 LL_ADC_SAMPLINGTIME_COMMON_1
#define ADC4_SAMPLINGTIME_COMMON_2 LL_ADC_SAMPLINGTIME_COMMON_2
#define ADC4_SAMPLINGTIME_COMMON_1 LL_ADC_SAMPLINGTIME_COMMON_1
#define ADC4_SAMPLINGTIME_COMMON_2 LL_ADC_SAMPLINGTIME_COMMON_2
#define ADC4_SAMPLINGTIME_COMMON_1 LL_ADC_SAMPLINGTIME_COMMON_1
#define ADC4_SAMPLINGTIME_COMMON_2 LL_ADC_SAMPLINGTIME_COMMON_2
#define ADC4_SAMPLINGTIME_COMMON_1 LL_ADC_SAMPLINGTIME_COMMON_1
#define ADC4_SAMPLINGTIME_COMMON_2 LL_ADC_SAMPLINGTIME_COMMON_2
#define ADC4_SAMPLINGTIME_COMMON_1 LL_ADC_SAMPLINGTIME_COMMON_1
#define ADC4_SAMPLINGTIME_COMMON_2 LL_ADC_SAMPLINGTIME_COMMON_2
#define ADC4_SAMPLINGTIME_COMMON_1 LL_ADC_SAMPLINGTIME_COMMON_1
#define ADC4_SAMPLINGTIME_COMMON_2 LL_ADC_SAMPLINGTIME_COMMON_2
#define ADC4_SAMPLINGTIME_COMMON_1 LL_ADC_SAMPLINGTIME_COMMON_1
#define ADC4_SAMPLINGTIME_COMMON_2 LL_ADC_SAMPLINGTIME_COMMON_2
#define ADC4_SAMPLINGTIME_COMMON_1 LL_ADC_SAMPLINGTIME_COMMON_1
#define ADC4_SAMPLINGTIME_COMMON_2 LL_ADC_SAMPLINGTIME_COMMON_2
#define ADC4_SAMPLINGTIME_COMMON_1 LL_ADC_SAMPLINGTIME_COMMON_1
#define ADC4_SAMPLINGTIME_COMMON_2 LL_ADC_SAMPLINGTIME_COMMON_2
#define ADC4_SAMPLINGTIME_COMMON_1 LL_ADC_SAMPLINGTIME_COMMON_1
#define ADC4_SAMPLINGTIME_COMMON_2 LL_ADC_SAMPLINGTIME_COMMON_2
#define ADC4_SAMPLINGTIME_COMMON_1 LL_ADC_SAMPLINGTIME_COMMON_1
#define ADC4_SAMPLINGTIME_COMMON_2 LL_ADC_SAMPLINGTIME_COMMON_2
#define ADC4_SAMPLINGTIME_COMMON_1 LL_ADC_SAMPLINGTIME_COMMON_1
#define ADC4_SAMPLINGTIME_COMMON_2 LL_ADC_SAMPLINGTIME_COMMON_2
#define ADC4_SAMPLINGTIME_COMMON_1 LL_ADC_SAMPLINGTIME_COMMON_1
#define ADC4_SAMPLINGTIME_COMMON_2 LL_ADC_SAMPLINGTIME_COMMON_2
#define ADC4_SAMPLINGTIME_COMMON_1 LL_ADC_SAMPLINGTIME_COMMON_1
#define ADC4_SAMPLINGTIME_COMMON_2 LL_ADC_SAMPLINGTIME_COMMON_2
#define ADC4_SAMPLINGTIME_COMMON_1 LL_ADC_SAMPLINGTIME_COMMON_1
#define ADC4_SAMPLINGTIME_COMMON_2 LL_ADC_SAMPLINGTIME_COMMON_2
#define ADC4_SAMPLINGTIME_COMMON_1 LL_ADC_SAMPLINGTIME_COMMON_1
#define ADC4_SAMPLINGTIME_COMMON_2 LL_ADC_SAMPLINGTIME_COMMON_2
#define ADC4_SAMPLINGTIME_COMMON_1 LL_ADC_SAMPLINGTIME_COMMON_1
#define ADC4_SAMPLINGTIME_COMMON_2 LL_ADC_SAMPLINGTIME_COMMON_2
#define ADC4_SAMPLINGTIME_COMMON_1 LL_ADC_SAMPLINGTIME_COMMON_1
#define ADC4_SAMPLINGTIME_COMMON_2 LL_ADC_SAMPLINGTIME_COMMON_2
#define ADC4_SAMPLINGTIME_COMMON_1 LL_ADC_SAMPLINGTIME_COMMON_1
#define ADC4_SAMPLINGTIME_COMMON_2 LL_ADC_SAMPLINGTIME_COMMON_2
#define ADC4_SAMPLINGTIME_COMMON_1 LL_ADC_SAMPLINGTIME_COMMON_1
#define ADC4_SAMPLINGTIME_COMMON_2 LL_ADC_SAMPLINGTIME_COMMON_2
#define ADC4_SAMPLINGTIME_COMMON_1 LL_ADC_SAMPLINGTIME_COMMON_1
#define ADC4_SAMPLINGTIME_COMMON_2 LL_ADC_SAMPLINGTIME_COMMON_2
#define ADC4_SAMPLINGTIME_COMMON_1 LL_ADC_SAMPLINGTIME_COMMON_1
#define ADC4_SAMPLINGTIME_COMMON_2 LL_ADC_SAMPLINGTIME_COMMON_2
#define ADC4_SAMPLINGTIME_COMMON_1 LL_ADC_SAMPLINGTIME_COMMON_1
#define ADC4_SAMPLINGTIME_COMMON_2 LL_ADC_SAMPLINGTIME_COMMON_2
#define ADC4_SAMPLINGTIME_COMMON_1 LL_ADC_SAMPLINGTIME_COMMON_1
#define ADC4_SAMPLINGTIME_COMMON_2 LL_ADC_SAMPLINGTIME_COMMON_2
#define ADC4_SAMPLINGTIME_COMMON_1 LL_ADC_SAMPLINGTIME_COMMON_1
#define ADC4_SAMPLINGTIME_COMMON_2 LL_ADC_SAMPLINGTIME_COMMON_2
#define ADC4_SAMPLINGTIME_COMMON_1 LL_ADC_SAMPLINGTIME_COMMON_1
#define ADC4_SAMPLINGTIME_COMMON_2 LL_ADC_SAMPLINGTIME_COMMON_2
#define ADC4_SAMPLINGTIME_COMMON_1 LL_ADC_SAMPLINGTIME_COMMON_1
#define ADC4_SAMPLINGTIME_COMMON_2 LL_ADC_SAMPLINGTIME_COMMON_2
#define ADC4_SAMPLINGTIME_COMMON_1 LL_ADC_SAMPLINGTIME_COMMON_1
#define ADC4_SAMPLINGTIME_COMMON_2 LL_ADC_SAMPLINGTIME_COMMON_2
#define ADC4_SAMPLINGTIME_COMMON_1 LL_ADC_SAMPLINGTIME_COMMON_1
#define ADC4_SAMPLINGTIME_COMMON_2 LL_ADC_SAMPLINGTIME_COMMON_2
#define ADC4_SAMPLINGTIME_COMMON_1 LL_ADC_SAMPLINGTIME_COMMON_1
#define ADC4_SAMPLINGTIME_COMMON_2 LL_ADC_SAMPLINGTIME_COMMON_2
#define ADC4_SAMPLINGTIME_COMMON_1 LL_ADC_SAMPLINGTIME_COMMON_1
#define ADC4_SAMPLINGTIME_COMMON_2 LL_ADC_SAMPLINGTIME_COMMON_2
#define ADC4_SAMPLINGTIME_COMMON_1 LL_ADC_SAMPLINGTIME_COMMON_1
#define ADC4_SAMPLINGTIME_COMMON_2 LL_ADC_SAMPLINGTIME_COMMON_2
#define ADC4_SAMPLINGTIME_COMMON_1 LL_ADC_SAMPLINGTIME_COMMON_1
#define ADC4_SAMPLINGTIME_COMMON_2 LL_ADC_SAMPLINGTIME_COMMON_2
#define ADC4_SAMPLINGTIME_COMMON_1 LL_ADC_SAMPLINGTIME_COMMON_1
#define ADC4_SAMPLINGTIME_COMMON_2 LL_ADC_SAMPLINGTIME_COMMON_2
#define ADC4_SAMPLINGTIME_COMMON_1 LL_ADC_SAMPLINGTIME_COMMON_1
#define ADC4_SAMPLINGTIME_COMMON_2 LL_ADC_SAMPLINGTIME_COMMON_2
#define ADC4_SAMPLINGTIME_COMMON_1 LL_ADC_SAMPLINGTIME_COMMON_1
#define ADC4_SAMPLINGTIME_COMMON_2 LL_ADC_SAMPLINGTIME_COMMON_2
#define ADC4_SAMPLINGTIME_COMMON_1 LL_ADC_SAMPLINGTIME_COMMON_1
#define ADC4_SAMPLINGTIME_COMMON_2 LL_ADC_SAMPLINGTIME_COMMON_2
#define ADC4_SAMPLINGTIME_COMMON_1 LL_ADC_SAMPLINGTIME_COMMON_1
#define ADC4_SAMPLINGTIME_COMMON_2 LL_ADC_SAMPLINGTIME_COMMON_2
#define ADC4_SAMPLINGTIME_COMMON_1 LL_ADC_SAMPLINGTIME_COMMON_1
#define ADC4_SAMPLINGTIME_COMMON_2 LL_ADC_SAMPLINGTIME_COMMON_2
#define ADC4_SAMPLINGTIME_COMMON_1 LL_ADC_SAMPLINGTIME_COMMON_1
#define ADC4_SAMPLINGTIME_COMMON_2 LL_ADC_SAMPLINGTIME_COMMON_2
#define ADC4_SAMPLINGTIME_COMMON_1 LL_ADC_SAMPLINGTIME_COMMON_1
#define ADC4_SAMPLINGTIME_COMMON_2 LL_ADC_SAMPLINGTIME_COMMON_2
#define ADC4_SAMPLINGTIME_COMMON_1 LL_ADC_SAMPLINGTIME_COMMON_1
#define ADC4_SAMPLINGTIME_COMMON_2 LL_ADC_SAMPLINGTIME_COMMON_2
#define ADC4_SAMPLINGTIME_COMMON_1 LL_ADC_SAMPLINGTIME_COMMON_1
#define ADC4_SAMPLINGTIME_COMMON_2 LL_ADC_SAMPLINGTIME_COMMON_2
#define ADC4_SAMPLINGTIME_COMMON_1 LL_ADC_SAMPLINGTIME_COMMON_1
#define ADC4_SAMPLINGTIME_COMMON_2 LL_ADC_SAMPLINGTIME_COMMON_2
#define ADC4_SAMPLINGTIME_COMMON_1 LL_ADC_SAMPLINGTIME_COMMON_1
#define ADC4_SAMPLINGTIME_COMMON_2 LL_ADC_SAMPLINGTIME_COMMON_2
#define ADC4_SAMPLINGTIME_COMMON_1 LL_ADC_SAMPLINGTIME_COMMON_1
#define ADC4_SAMPLINGTIME_COMMON_2 LL_ADC_SAMPLINGTIME_COMMON_2
#define ADC4_SAMPLINGTIME_COMMON_1 LL_ADC_SAMPLINGTIME_COMMON_1
#define ADC4_SAMPLINGTIME_COMMON_2 LL_ADC_SAMPLINGTIME_COMMON_2
#define ADC4_SAMPLINGTIME_COMMON_1 LL_ADC_SAMPLINGTIME_COMMON_1
#define ADC4_SAMPLINGTIME_COMMON_2 LL_ADC_SAMPLINGTIME_COMMON_2
#define ADC4_SAMPLINGTIME_COMMON_1 LL_ADC_SAMPLINGTIME_COMMON_1
#define ADC4_SAMPLINGTIME_COMMON_2 LL_ADC_SAMPLINGTIME_COMMON_2
#define ADC4_SAMPLINGTIME_COMMON_1 LL_ADC_SAMPLINGTIME_COMMON_1
#define ADC4_SAMPLINGTIME_COMMON_2 LL_ADC_SAMPLINGTIME_COMMON_2
#define ADC4_SAMPLINGTIME_COMMON_1 LL_ADC_SAMPLINGTIME_COMMON_1
#define ADC4_SAMPLINGTIME_COMMON_2 LL_ADC_SAMPLINGTIME_COMMON_2
#define ADC4_SAMPLINGTIME_COMMON_1 LL_ADC_SAMPLINGTIME_COMMON_1
#define ADC4_SAMPLINGTIME_COMMON_2 LL_ADC_SAMPLINGTIME_COMMON_2
#define ADC4_SAMPLINGTIME_COMMON_1 LL_ADC_SAMPLINGTIME_COMMON_1
#define ADC4_SAMPLINGTIME_COMMON_2 LL_ADC_SAMPLINGTIME_COMMON_2
#define ADC4_SAMPLINGTIME_COMMON_1 LL_ADC_SAMPLINGTIME_COMMON_1
#define ADC4_SAMPLINGTIME_COMMON_2 LL_ADC_SAMPLINGTIME_COMMON_2
#define ADC4_SAMPLINGTIME_COMMON_1 LL_ADC_SAMPLINGTIME_COMMON_1
#define ADC4_SAMPLINGTIME_COMMON_2 LL_ADC_SAMPLINGTIME_COMMON_2
#define ADC4_SAMPLINGTIME_COMMON_1 LL_ADC_SAMPLINGTIME_COMMON_1
#define ADC4_SAMPLINGTIME_COMMON_2 LL_ADC_SAMPLINGTIME_COMMON_2
#define ADC4_SAMPLINGTIME_COMMON_1 LL_ADC_SAMPLINGTIME_COMMON_1
#define ADC4_SAMPLINGTIME_COMMON_2 LL_ADC_SAMPLINGTIME_COMMON_2
#define ADC4_SAMPLINGTIME_COMMON_1 LL_ADC_SAMPLINGTIME_COMMON_1
#define ADC4_SAMPLINGTIME_COMMON_2 LL_ADC_SAMPLINGTIME_COMMON_2
#define ADC4_SAMPLINGTIME_COMMON_1 LL_ADC_SAMPLINGTIME_COMMON_1
#define ADC4_SAMPLINGTIME_COMMON_2 LL_ADC_SAMPLINGTIME_COMMON_2
#define ADC4_SAMPLINGTIME_COMMON_1 LL_ADC_SAMPLINGTIME_COMMON_1
#define ADC4_SAMPLINGTIME_COMMON_2 LL_ADC_SAMPLINGTIME_COMMON_2
#define ADC4_SAMPLINGTIME_COMMON_1 LL_ADC_SAMPLINGTIME_COMMON_1
#define ADC4_SAMPLINGTIME_COMMON_2 LL_ADC_SAMPLINGTIME_COMMON_2
#define ADC4_SAMPLINGTIME_COMMON_1 LL_ADC_SAMPLINGTIME_COMMON_1
#define ADC4_SAMPLINGTIME_COMMON_2 LL_ADC_SAMPLINGTIME_COMMON_2
#define ADC4_SAMPLINGTIME_COMMON_1 LL_ADC_SAMPLINGTIME_COMMON_1
#define ADC4_SAMPLINGTIME_COMMON_2 LL_ADC_SAMPLINGTIME_COMMON_2
#define ADC4_SAMPLINGTIME_COMMON_1 LL_ADC_SAMPLINGTIME_COMMON_1
#define ADC4_SAMPLINGTIME_COMMON_2 LL_ADC_SAMPLINGTIME_COMMON_2
#define ADC4_SAMPLINGTIME_COMMON_1 LL_ADC_SAMPLINGTIME_COMMON_1
#define ADC4_SAMPLINGTIME_COMMON_2 LL_ADC_SAMPLINGTIME_COMMON_2
#define ADC4_SAMPLINGTIME_COMMON_1 LL_ADC_SAMPLINGTIME_COMMON_1
#define ADC4_SAMPLINGTIME_COMMON_2 LL_ADC_SAMPLINGTIME_COMMON_2
#define ADC4_SAMPLINGTIME_COMMON_1 LL_ADC_SAMPLINGTIME_COMMON_1
#define ADC4_SAMPLINGTIME_COMMON_2 LL_ADC_SAMPLINGTIME_COMMON_2
#define ADC4_SAMPLINGTIME_COMMON_1 LL_ADC_SAMPLINGTIME_COMMON_1
#define ADC4_SAMPLINGTIME_COMMON_2 LL_ADC_SAMPLINGTIME_COMMON_2
#define ADC4_SAMPLINGTIME_COMMON_1 LL_ADC_SAMPLINGTIME_COMMON_1
#define ADC4_SAMPLINGTIME_COMMON_2 LL_ADC_SAMPLINGTIME_COMMON_2
#define ADC4_SAMPLINGTIME_COMMON_1 LL_ADC_SAMPLINGTIME_COMMON_1
#define ADC4_SAMPLINGTIME_COMMON_2 LL_ADC_SAMPLINGTIME_COMMON_2
#define ADC4_SAMPLINGTIME_COMMON_1 LL_ADC_SAMPLINGTIME_COMMON_1
#define ADC4_SAMPLINGTIME_COMMON_2 LL_ADC_SAMPLINGTIME_COMMON_2
#define ADC4_SAMPLINGTIME_COMMON_1 LL_ADC_SAMPLINGTIME_COMMON_1
#define ADC4_SAMPLINGTIME_COMMON_2 LL_ADC_SAMPLINGTIME_COMMON_2
#define ADC4_SAMPLINGTIME_COMMON_1 LL_ADC_SAMPLINGTIME_COMMON_1
#define ADC4_SAMPLINGTIME_COMMON_2 LL_ADC_SAMPLINGTIME_COMMON_2
#define ADC4_SAMPLINGTIME_COMMON_1 LL_ADC_SAMPLINGTIME_COMMON_1
#define ADC4_SAMPLINGTIME_COMMON_2 LL_ADC_SAMPLINGTIME_COMMON_2
#define ADC4_SAMPLINGTIME_COMMON_1 LL_ADC_SAMPLINGTIME_COMMON_1
#define ADC4_SAMPLINGTIME_COMMON_2 LL_ADC_SAMPLINGTIME_COMMON_2
#define ADC4_SAMPLINGTIME_COMMON_1 LL_ADC_SAMPLINGTIME_COMMON_1
#define ADC4_SAMPLINGTIME_COMMON_2 LL_ADC_SAMPLINGTIME_COMMON_2
#define ADC4_SAMPLINGTIME_COMMON_1 LL_ADC_SAMPLINGTIME_COMMON_1
#define ADC4_SAMPLINGTIME_COMMON_2 LL_ADC_SAMPLINGTIME_COMMON_2
#define ADC4_SAMPLINGTIME_COMMON_1 LL_ADC_SAMPLINGTIME_COMMON_1
#define ADC4_SAMPLINGTIME_COMMON_2 LL_ADC_SAMPLINGTIME_COMMON_2
#define ADC4_SAMPLINGTIME_COMMON_1 LL_ADC_SAMPLINGTIME_COMMON_1
#define ADC4_SAMPLINGTIME_COMMON_2 LL_ADC_SAMPLINGTIME_COMMON_2
#define ADC4_SAMPLINGTIME_COMMON_1 LL_ADC_SAMPLINGTIME_COMMON_1
#define ADC4_SAMPLINGTIME_COMMON_2 LL_ADC_SAMPLINGTIME_COMMON_2
#define ADC4_SAMPLINGTIME_COMMON_1 LL_ADC_SAMPLINGTIME_COMMON_1
#define ADC4_SAMPLINGTIME_COMMON_2 LL_ADC_SAMPLINGTIME_COMMON_2
#define ADC4_SAMPLINGTIME_COMMON_1 LL_ADC_SAMPLINGTIME_COMMON_1
#define ADC4_SAMPLINGTIME_COMMON_2 LL_ADC_SAMPLINGTIME_COMMON_2
#define ADC4_SAMPLINGTIME_COMMON_1 LL_ADC_SAMPLINGTIME_COMMON_1
#define ADC4_SAMPLINGTIME_COMMON_2 LL_ADC_SAMPLINGTIME_COMMON_2
#define ADC4_SAMPLINGTIME_COMMON_1 LL_ADC_SAMPLINGTIME_COMMON_1
#define ADC4_SAMPLINGTIME_COMMON_2 LL_ADC_SAMPLINGTIME_COMMON_2
#define ADC4_SAMPLINGTIME_COMMON_1 LL_ADC_SAMPLINGTIME_COMMON_1
#define ADC4_SAMPLINGTIME_COMMON_2 LL_ADC_SAMPLINGTIME_COMMON_2
#define ADC4_SAMPLINGTIME_COMMON_1 LL_ADC_SAMPLINGTIME_COMMON_1
#define ADC4_SAMPLINGTIME_COMMON_2 LL_ADC_SAMPLINGTIME_COMMON_2
#define ADC4_SAMPLINGTIME_COMMON_1 LL_ADC_SAMPLINGTIME_COMMON_1
#define ADC4_SAMPLINGTIME_COMMON_2 LL_ADC_SAMPLINGTIME_COMMON_2
#define ADC4_SAMPLINGTIME_COMMON_1 LL_ADC_SAMPLINGTIME_COMMON_1
#define ADC4_SAMPLINGTIME_COMMON_2 LL_ADC_SAMPLINGTIME_COMMON_2
#define ADC4_SAMPLINGTIME_COMMON_1 LL_ADC_SAMPLINGTIME_COMMON_1
#define ADC4_SAMPLINGTIME_COMMON_2 LL_ADC_SAMPLINGTIME_COMMON_2
#define ADC4_SAMPLINGTIME_COMMON_1 LL_ADC_SAMPLINGTIME_COMMON_1
#define ADC4_SAMPLINGTIME_COMMON_2 LL_ADC_SAMPLINGTIME_COMMON_2
#define ADC4_SAMPLINGTIME_COMMON_1 LL_ADC_SAMPLINGTIME_COMMON_1
#define ADC4_SAMPLINGTIME_COMMON_2 LL_ADC_SAMPLINGTIME_COMMON_2
#define ADC4_SAMPLINGTIME_COMMON_1 LL_ADC_SAMPLINGTIME_COMMON_1
#define ADC4_SAMPLINGTIME_COMMON_2 LL_ADC_SAMPLINGTIME_COMMON_2
#define ADC4_SAMPLINGTIME_COMMON_1 LL_ADC_SAMPLINGTIME_COMMON_1
#define ADC4_SAMPLINGTIME_COMMON_2 LL_ADC_SAMPLINGTIME_COMMON_2
#define ADC4_SAMPLINGTIME_COMMON_1 LL_ADC_SAMPLINGTIME_COMMON_1
#define ADC4_SAMPLINGTIME_COMMON_2 LL_ADC_SAMPLINGTIME_COMMON_2
#define ADC4_SAMPLINGTIME_COMMON_1 LL_ADC_SAMPLINGTIME_COMMON_1
#define ADC4_SAMPLINGTIME_COMMON_2 LL_ADC_SAMPLINGTIME_COMMON_2
#define ADC4_SAMPLINGTIME_COMMON_1 LL_ADC_SAMPLINGTIME_COMMON_1
#define ADC4_SAMPLINGTIME_COMMON_2 LL_ADC_SAMPLINGTIME_COMMON_2
#define ADC4_SAMPLINGTIME_COMMON_1 LL_ADC_SAMPLINGTIME_COMMON_1
#define ADC4_SAMPLINGTIME_COMMON_2 LL_ADC_SAMPLINGTIME_COMMON_2
#define ADC4_SAMPLINGTIME_COMMON_1 LL_ADC_SAMPLINGTIME_COMMON_1
#define ADC4_SAMPLINGTIME_COMMON_2 LL_ADC_SAMPLINGTIME_COMMON_2
#define ADC4_SAMPLINGTIME_COMMON_1 LL_ADC_SAMPLINGTIME_COMMON_1
#define ADC4_SAMPLINGTIME_COMMON_2 LL_ADC_SAMPLINGTIME_COMMON_2
#define ADC4_SAMPLINGTIME_COMMON_1 LL_ADC_SAMPLINGTIME_COMMON_1
#define ADC4_SAMPLINGTIME_COMMON_2 LL_ADC_SAMPLINGTIME_COMMON_2
#define ADC4_SAMPLINGTIME_COMMON_1 LL_ADC_SAMPLINGTIME_COMMON_1
#define ADC4_SAMPLINGTIME_COMMON_2 LL_ADC_SAMPLINGTIME_COMMON_2
#define ADC4_SAMPLINGTIME_COMMON_1 LL_ADC_SAMPLINGTIME_COMMON_1
#define ADC4_SAMPLINGTIME_COMMON_2 LL_ADC_SAMPLINGTIME_COMMON_2
#define ADC4_SAMPLINGTIME_COMMON_1 LL_ADC_SAMPLINGTIME_COMMON_1
#define ADC4_SAMPLINGTIME_COMMON_2 LL_ADC_SAMPLINGTIME_COMMON_2
#define ADC4_SAMPLINGTIME_COMMON_1 LL_ADC_SAMPLINGTIME_COMMON_1
#define ADC4_SAMPLINGTIME_COMMON_2 LL_ADC_SAMPLINGTIME_COMMON_2
#define ADC4_SAMPLINGTIME_COMMON_1 LL_ADC_SAMPLINGTIME_COMMON_1
#define ADC4_SAMPLINGTIME_COMMON_2 LL_ADC_SAMPLINGTIME_COMMON_2
#define ADC4_SAMPLINGTIME_COMMON_1 LL_ADC_SAMPLINGTIME_COMMON_1
#define ADC4_SAMPLINGTIME_COMMON_2 LL_ADC_SAMPLINGTIME_COMMON_2
#define ADC4_SAMPLINGTIME_COMMON_1 LL_ADC_SAMPLINGTIME_COMMON_1
#define ADC4_SAMPLINGTIME_COMMON_2 LL_ADC_SAMPLINGTIME_COMMON_2
#define ADC4_SAMPLINGTIME_COMMON_1 LL_ADC_SAMPLINGTIME_COMMON_1
#define ADC4_SAMPLINGTIME_COMMON_2 LL_ADC_SAMPLINGTIME_COMMON_2
#define ADC4_SAMPLINGTIME_COMMON_1 LL_ADC_SAMPLINGTIME_COMMON_1
#define ADC4_SAMPLINGTIME_COMMON_2 LL_ADC_SAMPLINGTIME_COMMON_2
#define ADC4_SAMPLINGTIME_COMMON_1 LL_ADC_SAMPLINGTIME_COMMON_1
#define ADC4_SAMPLINGTIME_COMMON_2 LL_ADC_SAMPLINGTIME_COMMON_2
#define ADC4_SAMPLINGTIME_COMMON_1 LL_ADC_SAMPLINGTIME_COMMON_1
#define ADC4_SAMPLINGTIME_COMMON_2 LL_ADC_SAMPLINGTIME_COMMON_2
#define ADC4_SAMPLINGTIME_COMMON_1 LL_ADC_SAMPLINGTIME_COMMON_1
#define ADC4_SAMPLINGTIME_COMMON_2 LL_ADC_SAMPLINGTIME_COMMON_2
#define ADC4_SAMPLINGTIME_COMMON_1 LL_ADC_SAMPLINGTIME_COMMON_1
#define ADC4_SAMPLINGTIME_COMMON_2 LL_ADC_SAMPLINGTIME_COMMON_2
#define ADC4_SAMPLINGTIME_COMMON_1 LL_ADC_SAMPLINGTIME_COMMON_1
#define ADC4_SAMPLINGTIME_COMMON_2 LL_ADC_SAMPLINGTIME_COMMON_2
#define ADC4_SAMPLINGTIME_COMMON_1 LL_ADC_SAMPLINGTIME_COMMON_1
#define ADC4_SAMPLINGTIME_COMMON_2 LL_ADC_SAMPLINGTIME_COMMON_2
#define ADC4_SAMPLINGTIME_COMMON_1 LL_ADC_SAMPLINGTIME_COMMON_1
#define ADC4_SAMPLINGTIME_COMMON_2 LL_ADC_SAMPLINGTIME_COMMON_2
#define ADC4_SAMPLINGTIME_COMMON_1 LL_ADC_SAMPLINGTIME_COMMON_1
#define ADC4_SAMPLINGTIME_COMMON_2 LL_ADC_SAMPLINGTIME_COMMON_2
#define ADC4_SAMPLINGTIME_COMMON_1 LL_ADC_SAMPLINGTIME_COMMON_1
#define ADC4_SAMPLINGTIME_COMMON_2 LL_ADC_SAMPLINGTIME_COMMON_2
#define ADC4_SAMPLINGTIME_COMMON_1 LL_ADC_SAMPLINGTIME_COMMON_1
#define ADC4_SAMPLINGTIME_COMMON_2 LL_ADC_SAMPLINGTIME_COMMON_2
#define ADC4_SAMPLINGTIME_COMMON_1 LL_ADC_SAMPLINGTIME_COMMON_1
#define ADC4_SAMPLINGTIME_COMMON_2 LL_ADC_SAMPLINGTIME_COMMON_2
#define ADC4_SAMPLINGTIME_COMMON_1 LL_ADC_SAMPLINGTIME_COMMON_1
#define ADC4_SAMPLINGTIME_COMMON_2 LL_ADC_SAMPLINGTIME_COMMON_2
#define ADC4_SAMPLINGTIME_COMMON_1 LL_ADC_SAMPLINGTIME_COMMON_1
#define ADC4_SAMPLINGTIME_COMMON_2 LL_ADC_SAMPLINGTIME_COMMON_2
#define ADC4_SAMPLINGTIME_COMMON_1 LL_ADC_SAMPLINGTIME_COMMON_1
#define ADC4_SAMPLINGTIME_COMMON_2 LL_ADC_SAMPLINGTIME_COMMON_2
#define ADC4_SAMPLINGTIME_COMMON_1 LL_ADC_SAMPLINGTIME_COMMON_1
#define ADC4_SAMPLINGTIME_COMMON_2 LL_ADC_SAMPLINGTIME_COMMON_2
#define ADC4_SAMPLINGTIME_COMMON_1 LL_ADC_SAMPLINGTIME_COMMON_1
#define ADC4_SAMPLINGTIME_COMMON_2 LL_ADC_SAMPLINGTIME_COMMON_2
#define ADC4_SAMPLINGTIME_COMMON_1 LL_ADC_SAMPLINGTIME_COMMON_1
#define ADC4_SAMPLINGTIME_COMMON_2 LL_ADC_SAMPLINGTIME_COMMON_2
#define ADC4_SAMPLINGTIME_COMMON_1 LL_ADC_SAMPLINGTIME_COMMON_1
#define ADC4_SAMPLINGTIME_COMMON_2 LL_ADC_SAMPLINGTIME_COMMON_2
#define ADC4_SAMPLINGTIME_COMMON_1 LL_ADC_SAMPLINGTIME_COMMON_1
#define ADC4_SAMPLINGTIME_COMMON_2 LL_ADC_SAMPLINGTIME_COMMON_2
#define ADC4_SAMPLINGTIME_COMMON_1 LL_ADC_SAMPLINGTIME_COMMON_1
#define ADC4_SAMPLINGTIME_COMMON_2 LL_ADC_SAMPLINGTIME_COMMON_2
#define ADC4_SAMPLINGTIME_COMMON_1 LL_ADC_SAMPLINGTIME_COMMON_1
#define ADC4_SAMPLINGTIME_COMMON_2 LL_ADC_SAMPLINGTIME_COMMON_2
#define ADC4_SAMPLINGTIME_COMMON_1 LL_ADC_SAMPLINGTIME_COMMON_1
#define ADC4_SAMPLINGTIME_COMMON_2 LL_ADC_SAMPLINGTIME_COMMON_2
#define ADC4_SAMPLINGTIME_COMMON_1 LL_ADC_SAMPLINGTIME_COMMON_1
#define ADC4_SAMPLINGTIME_COMMON_2 LL_ADC_SAMPLINGTIME_COMMON_2
#define ADC4_SAMPLINGTIME_COMMON_1 LL_ADC_SAMPLINGTIME_COMMON_1
#define ADC4_SAMPLINGTIME_COMMON_2 LL_ADC_SAMPLINGTIME_COMMON_2
#define ADC4_SAMPLINGTIME_COMMON_1 LL_ADC_SAMPLINGTIME_COMMON_1
#define ADC4_SAMPLINGTIME_COMMON_2 LL_ADC_SAMPLINGTIME_COMMON_2
#define ADC4_SAMPLINGTIME_COMMON_1 LL_ADC_SAMPLINGTIME_COMMON_1
#define ADC4_SAMPLINGTIME_COMMON_2 LL_ADC_SAMPLINGTIME_COMMON_2
#define ADC4_SAMPLINGTIME_COMMON_1 LL_ADC_SAMPLINGTIME_COMMON_1
#define ADC4_SAMPLINGTIME_COMMON_2 LL_ADC_SAMPLINGTIME_COMMON_2
#define ADC4_SAMPLINGTIME_COMMON_1 LL_ADC_SAMPLINGTIME_COMMON_1
#define ADC4_SAMPLINGTIME_COMMON_2 LL_ADC_SAMPLINGTIME_COMMON_2
#define ADC4_SAMPLINGTIME_COMMON_1 LL_ADC_SAMPLINGTIME_COMMON_1
#define ADC4_SAMPLINGTIME_COMMON_2 LL_ADC_SAMPLINGTIME_COMMON_2
#define ADC4_SAMPLINGTIME_COMMON_1 LL_ADC_SAMPLINGTIME_COMMON_1
#define ADC4_SAMPLINGTIME_COMMON_2 LL_ADC_SAMPLINGTIME_COMMON_2
#define ADC4_SAMPLINGTIME_COMMON_1 LL_ADC_SAMPLINGTIME_COMMON_1
#define ADC4_SAMPLINGTIME_COMMON_2 LL_ADC_SAMPLINGTIME_COMMON_2
#define ADC4_SAMPLINGTIME_COMMON_1 LL_ADC_SAMPLINGTIME_COMMON_1
#define ADC4_SAMPLINGTIME_COMMON_2 LL_ADC_SAMPLINGTIME_COMMON_2
#define ADC4_SAMPLINGTIME_COMMON_1 LL_ADC_SAMPLINGTIME_COMMON_1
#define ADC4_SAMPLINGTIME_COMMON_2 LL_ADC_SAMPLINGTIME_COMMON_2
#define ADC4_SAMPLINGTIME_COMMON_1 LL_ADC_SAMPLINGTIME_COMMON_1
#define ADC4_SAMPLINGTIME_COMMON_2 LL_ADC_SAMPLINGTIME_COMMON_2
#define ADC4_SAMPLINGTIME_COMMON_1 LL_ADC_SAMPLINGTIME_COMMON_1
#define ADC4_SAMPLINGTIME_COMMON_2 LL_ADC_SAMPLINGTIME_COMMON_2
#define ADC4_SAMPLINGTIME_COMMON_1 LL_ADC_SAMPLINGTIME_COMMON_1
#define ADC4_SAMPLINGTIME_COMMON_2 LL_ADC_SAMPLINGTIME_COMMON_2
#define ADC4_SAMPLINGTIME_COMMON_1 LL_ADC_SAMPLINGTIME_COMMON_1
#define ADC4_SAMPLINGTIME_COMMON_2 LL_ADC_SAMPLINGTIME_COMMON_2
#define ADC4_SAMPLINGTIME_COMMON_1 LL_ADC_SAMPLINGTIME_COMMON_1
#define ADC4_SAMPLINGTIME_COMMON_2 LL_ADC_SAMPLINGTIME_COMMON_2
#define ADC4_SAMPLINGTIME_COMMON_1 LL_ADC_SAMPLINGTIME_COMMON_1
#define ADC4_SAMPLINGTIME_COMMON_2 LL_ADC_SAMPLINGTIME_COMMON_2
#define ADC4_SAMPLINGTIME_COMMON_1 LL_ADC_SAMPLINGTIME_COMMON_1
#define ADC4_SAMPLINGTIME_COMMON_2 LL_ADC_SAMPLINGTIME_COMMON_2
#define ADC4_SAMPLINGTIME_COMMON_1 LL_ADC_SAMPLINGTIME_COMMON_1
#define ADC4_SAMPLINGTIME_COMMON_2 LL_ADC_SAMPLINGTIME_COMMON_2
#define ADC4_SAMPLINGTIME_COMMON_1 LL_ADC_SAMPLINGTIME_COMMON_1
#define ADC4_SAMPLINGTIME_COMMON_2 LL_ADC_SAMPLINGTIME_COMMON_2
#define ADC4_SAMPLINGTIME_COMMON_1 LL_ADC_SAMPLINGTIME_COMMON_1
#define ADC4_SAMPLINGTIME_COMMON_2 LL_ADC_SAMPLINGTIME_COMMON_2
#define ADC4_SAMPLINGTIME_COMMON_1 LL_ADC_SAMPLINGTIME_COMMON_1
#define ADC4_SAMPLINGTIME_COMMON_2 LL_ADC_SAMPLINGTIME_COMMON_2
#define ADC4_SAMPLINGTIME_COMMON_1 LL_ADC_SAMPLINGTIME_COMMON_1
#define ADC4_SAMPLINGTIME_COMMON_2 LL_ADC_SAMPLINGTIME_COMMON_2
#define ADC4_SAMPLINGTIME_COMMON_1 LL_ADC_SAMPLINGTIME_COMMON_1
#define ADC4_SAMPLINGTIME_COMMON_2 LL_ADC_SAMPLINGTIME_COMMON_2
#define ADC4_SAMPLINGTIME_COMMON_1 LL_ADC_SAMPLINGTIME_COMMON_1
#define ADC4_SAMPLINGTIME_COMMON_2 LL_ADC_SAMPLINGTIME_COMMON_2
#define ADC4_SAMPLINGTIME_COMMON_1 LL_ADC_SAMPLINGTIME_COMMON_1
#define ADC4_SAMPLINGTIME_COMMON_2 LL_ADC_SAMPLINGTIME_COMMON_2
#define ADC4_SAMPLINGTIME_COMMON_1 LL_ADC_SAMPLINGTIME_COMMON_1
#define ADC4_SAMPLINGTIME_COMMON_2 LL_ADC_SAMPLINGTIME_COMMON_2
#define ADC4_SAMPLINGTIME_COMMON_1 LL_ADC_SAMPLINGTIME_COMMON_1
#define ADC4_SAMPLINGTIME_COMMON_2 LL_ADC_SAMPLINGTIME_COMMON_2
#define ADC4_SAMPLINGTIME_COMMON_1 LL_ADC_SAMPLINGTIME_COMMON_1
#define ADC4_SAMPLINGTIME_COMMON_2 LL_ADC_SAMPLINGTIME_COMMON_2
#define ADC4_SAMPLINGTIME_COMMON_1 LL_ADC_SAMPLINGTIME_COMMON_1
#define ADC4_SAMPLINGTIME_COMMON_2 LL_ADC_SAMPLINGTIME_COMMON_2
#define ADC4_SAMPLINGTIME_COMMON_1 LL_ADC_SAMPLINGTIME_COMMON_1
#define ADC4_SAMPLINGTIME_COMMON_2 LL_ADC_SAMPLINGTIME_COMMON_2
#define ADC4_SAMPLINGTIME_COMMON_1 LL_ADC_SAMPLINGTIME_COMMON_1
#define ADC4_SAMPLINGTIME_COMMON_2 LL_ADC_SAMPLINGTIME_COMMON_2
#define ADC4_SAMPLINGTIME_COMMON_1 LL_ADC_SAMPLINGTIME_COMMON_1
#define ADC4_SAMPLINGTIME_COMMON_2 LL_ADC_SAMPLINGTIME_COMMON_2
#define ADC4_SAMPLINGTIME_COMMON_1 LL_ADC_SAMPLINGTIME_COMMON_1
#define ADC4_SAMPLINGTIME_COMMON_2 LL_ADC_SAMPLINGTIME_COMMON_2
#define ADC4_SAMPLINGTIME_COMMON_1 LL_ADC_SAMPLINGTIME_COMMON_1
#define ADC4_SAMPLINGTIME_COMMON_2 LL_ADC_SAMPLINGTIME_COMMON_2
#define ADC4_SAMPLINGTIME_COMMON_1 LL_ADC_SAMPLINGTIME_COMMON_1
#define ADC4_SAMPLINGTIME_COMMON_2 LL_ADC_SAMPLINGTIME_COMMON_2
#define ADC4_SAMPLINGTIME_COMMON_1 LL_ADC_SAMPLINGTIME_COMMON_1
#define ADC4_SAMPLINGTIME_COMMON_2 LL_ADC_SAMPLINGTIME_COMMON_2
#define ADC4_SAMPLINGTIME_COMMON_1 LL_ADC_SAMPLINGTIME_COMMON_1
#define ADC4_SAMPLINGTIME_COMMON_2 LL_ADC_SAMPLINGTIME_COMMON_2
#define ADC4_SAMPLINGTIME_COMMON_1 LL_ADC_SAMPLINGTIME_COMMON_1
#define ADC4_SAMPLINGTIME_COMMON_2 LL_ADC_SAMPLINGTIME_COMMON_2
#define ADC4_SAMPLINGTIME_COMMON_1 LL_ADC_SAMPLINGTIME_COMMON_1
#define ADC4_SAMPLINGTIME_COMMON_2 LL_ADC_SAMPLINGTIME_COMMON_2
#define ADC4_SAMPLINGTIME_COMMON_1 LL_ADC_SAMPLINGTIME_COMMON_1
#define ADC4_SAMPLINGTIME_COMMON_2 LL_ADC_SAMPLINGTIME_COMMON_2
#define ADC4_SAMPLINGTIME_COMMON_1 LL_ADC_SAMPLINGTIME_COMMON_1
#define ADC4_SAMPLINGTIME_COMMON_2 LL_ADC_SAMPLINGTIME_COMMON_2
#define ADC4_SAMPLINGTIME_COMMON_1 LL_ADC_SAMPLINGTIME_COMMON_1
#define ADC4_SAMPLINGTIME_COMMON_2 LL_ADC_SAMPLINGTIME_COMMON_2
#define ADC4_SAMPLINGTIME_COMMON_1 LL_ADC_SAMPLINGTIME_COMMON_1
#define ADC4_SAMPLINGTIME_COMMON_2 LL_ADC_SAMPLINGTIME_COMMON_2
#define ADC4_SAMPLINGTIME_COMMON_1 LL_ADC_SAMPLINGTIME_COMMON_1
#define ADC4_SAMPLINGTIME_COMMON_2 LL_ADC_SAMPLINGTIME_COMMON_2
#define ADC4_SAMPLINGTIME_COMMON_1 LL_ADC_SAMPLINGTIME_COMMON_1
#define ADC4_SAMPLINGTIME_COMMON_2 LL_ADC_SAMPLINGTIME_COMMON_2
#define ADC4_SAMPLINGTIME_COMMON_1 LL_ADC_SAMPLINGTIME_COMMON_1
#define ADC4_SAMPLINGTIME_COMMON_2 LL_ADC_SAMPLINGTIME_COMMON_2
#define ADC4_SAMPLINGTIME_COMMON_1 LL_ADC_SAMPLINGTIME_COMMON_1
#define ADC4_SAMPLINGTIME_COMMON_2 LL_ADC_SAMPLINGTIME_COMMON_2
#define ADC4_SAMPLINGTIME_COMMON_1 LL_ADC_SAMPLINGTIME_COMMON_1
#define ADC4_SAMPLINGTIME_COMMON_2 LL_ADC_SAMPLINGTIME_COMMON_2
#define ADC4_SAMPLINGTIME_COMMON_1 LL_ADC_SAMPLINGTIME_COMMON_1
#define ADC4_SAMPLINGTIME_COMMON_2 LL_ADC_SAMPLINGTIME_COMMON_2
#define ADC4_SAMPLINGTIME_COMMON_1 LL_ADC_SAMPLINGTIME_COMMON_1
#define ADC4_SAMPLINGTIME_COMMON_2 LL_ADC_SAMPLINGTIME_COMMON_2
#define ADC4_SAMPLINGTIME_COMMON_1 LL_ADC_SAMPLINGTIME_COMMON_1
#define ADC4_SAMPLINGTIME_COMMON_2 LL_ADC_SAMPLINGTIME_COMMON_2
#define ADC4_SAMPLINGTIME_COMMON_1 LL_ADC_SAMPLINGTIME_COMMON_1
#define ADC4_SAMPLINGTIME_COMMON_2 LL_ADC_SAMPLINGTIME_COMMON_2
#define ADC4_SAMPLINGTIME_COMMON_1 LL_ADC_SAMPLINGTIME_COMMON_1
#define ADC4_SAMPLINGTIME_COMMON_2 LL_ADC_SAMPLINGTIME_COMMON_2
#define ADC4_SAMPLINGTIME_COMMON_1 LL_ADC_SAMPLINGTIME_COMMON_1
#define ADC4_SAMPLINGTIME_COMMON_2 LL_ADC_SAMPLINGTIME_COMMON_2
#define ADC4_SAMPLINGTIME_COMMON_1 LL_ADC_SAMPLINGTIME_COMMON_1
#define ADC4_SAMPLINGTIME_COMMON_2 LL_ADC_SAMPLINGTIME_COMMON_2
#define ADC4_SAMPLINGTIME_COMMON_1 LL_ADC_SAMPLINGTIME_COMMON_1
#define ADC4_SAMPLINGTIME_COMMON_2 LL_ADC_SAMPLINGTIME_COMMON_2
#define ADC4_SAMPLINGTIME_COMMON_1 LL_ADC_SAMPLINGTIME_COMMON_1
#define ADC4_SAMPLINGTIME_COMMON_2 LL_ADC_SAMPLINGTIME_COMMON_2
#define ADC4_SAMPLINGTIME_COMMON_1 LL_ADC_SAMPLINGTIME_COMMON_1
#define ADC4_SAMPLINGTIME_COMMON_2 LL_ADC_SAMPLINGTIME_COMMON_2
#define ADC4_SAMPLINGTIME_COMMON_1 LL_ADC_SAMPLINGTIME_COMMON_1
#define ADC4_SAMPLINGTIME_COMMON_2 LL_ADC_SAMPLINGTIME_COMMON_2
#define ADC4_SAMPLINGTIME_COMMON_1 LL_ADC_SAMPLINGTIME_COMMON_1
#define ADC4_SAMPLINGTIME_COMMON_2 LL_ADC_SAMPLINGTIME_COMMON_2
#define ADC4_SAMPLINGTIME_COMMON_1 LL_ADC_SAMPLINGTIME_COMMON_1
#define ADC4_SAMPLINGTIME_COMMON_2 LL_ADC_SAMPLINGTIME_COMMON_2
#define ADC4_SAMPLINGTIME_COMMON_1 LL_ADC_SAMPLINGTIME_COMMON_1
#define ADC4_SAMPLINGTIME_COMMON_2 LL_ADC_SAMPLINGTIME_COMMON_2
#define ADC4_SAMPLINGTIME_COMMON_1 LL_ADC_SAMPLINGTIME_COMMON_1
#define ADC4_SAMPLINGTIME_COMMON_2 LL_ADC_SAMPLINGTIME_COMMON_2
#define ADC4_SAMPLINGTIME_COMMON_1 LL_ADC_SAMPLINGTIME_COMMON_1
#define ADC4_SAMPLINGTIME_COMMON_2 LL_ADC_SAMPLINGTIME_COMMON_2
#define ADC4_SAMPLINGTIME_COMMON_1 LL_ADC_SAMPLINGTIME_COMMON_1
#define ADC4_SAMPLINGTIME_COMMON_2 LL_ADC_SAMPLINGTIME_COMMON_2
#define ADC4_SAMPLINGTIME_COMMON_1 LL_ADC_SAMPLINGTIME_COMMON_1
#define ADC4_SAMPLINGTIME_COMMON_2 LL_ADC_SAMPLINGTIME_COMMON_2
#define ADC4_SAMPLINGTIME_COMMON_1 LL_ADC_SAMPLINGTIME_COMMON_1
#define ADC4_SAMPLINGTIME_COMMON_2 LL_ADC_SAMPLINGTIME_COMMON_2
#define ADC4_SAMPLINGTIME_COMMON_1 LL_ADC_SAMPLINGTIME_COMMON_1
#define ADC4_SAMPLINGTIME_COMMON_2 LL_ADC_SAMPLINGTIME_COMMON_2
#define ADC4_SAMPLINGTIME_COMMON_1 LL_ADC_SAMPLINGTIME_COMMON_1
#define ADC4_SAMPLINGTIME_COMMON_2 LL_ADC_SAMPLINGTIME_COMMON_2
#define ADC4_SAMPLINGTIME_COMMON_1 LL_ADC_SAMPLINGTIME_COMMON_1
#define ADC4_SAMPLINGTIME_COMMON_2 LL_ADC_SAMPLINGTIME_COMMON_2
#define ADC4_SAMPLINGTIME_COMMON_1 LL_ADC_SAMPLINGTIME_COMMON_1
#define ADC4_SAMPLINGTIME_COMMON_2 LL_ADC_SAMPLINGTIME_COMMON_2
#define ADC4_SAMPLINGTIME_COMMON_1 LL_ADC_SAMPLINGTIME_COMMON_1
#define ADC4_SAMPLINGTIME_COMMON_2 LL_ADC_SAMPLINGTIME_COMMON_2
#define ADC4_SAMPLINGTIME_COMMON_1 LL_ADC_SAMPLINGTIME_COMMON_1
#define ADC4_SAMPLINGTIME_COMMON_2 LL_ADC_SAMPLINGTIME_COMMON_2
#define ADC4_SAMPLINGTIME_COMMON_1 LL_ADC_SAMPLINGTIME_COMMON_1
#define ADC4_SAMPLINGTIME_COMMON_2 LL_ADC_SAMPLINGTIME_COMMON_2
#define ADC4_SAMPLINGTIME_COMMON_1 LL_ADC_SAMPLINGTIME_COMMON_1
#define ADC4_SAMPLINGTIME_COMMON_2 LL_ADC_SAMPLINGTIME_COMMON_2
#define ADC4_SAMPLINGTIME_COMMON_1 LL_ADC_SAMPLINGTIME_COMMON_1
#define ADC4_SAMPLINGTIME_COMMON_2 LL_ADC_SAMPLINGTIME_COMMON_2
#define ADC4_SAMPLINGTIME_COMMON_1 LL_ADC_SAMPLINGTIME_COMMON_1
#define ADC4_SAMPLINGTIME_COMMON_2 LL_ADC_SAMPLINGTIME_COMMON_2
#define ADC4_SAMPLINGTIME_COMMON_1 LL_ADC_SAMPLINGTIME_COMMON_1
#define ADC4_SAMPLINGTIME_COMMON_2 LL_ADC_SAMPLINGTIME_COMMON_2
#define ADC4_SAMPLINGTIME_COMMON_1 LL_ADC_SAMPLINGTIME_COMMON_1
#define ADC4_SAMPLINGTIME_COMMON_2 LL_ADC_SAMPLINGTIME_COMMON_2
#define ADC4_SAMPLINGTIME_COMMON_1 LL_ADC_SAMPLINGTIME_COMMON_1
#define ADC4_SAMPLINGTIME_COMMON_2 LL_ADC_SAMPLINGTIME_COMMON_2
#define ADC4_SAMPLINGTIME_COMMON_1 LL_ADC_SAMPLINGTIME_COMMON_1
#define ADC4_SAMPLINGTIME_COMMON_2 LL_ADC_SAMPLINGTIME_COMMON_2
#define ADC4_SAMPLINGTIME_COMMON_1 LL_ADC_SAMPLINGTIME_COMMON_1
#define ADC4_SAMPLINGTIME_COMMON_2 LL_ADC_SAMPLINGTIME_COMMON_2
#define ADC4_SAMPLINGTIME_COMMON_1 LL_ADC_SAMPLINGTIME_COMMON_1
#define ADC4_SAMPLINGTIME_COMMON_2 LL_ADC_SAMPLINGTIME_COMMON_2
#define ADC4_SAMPLINGTIME_COMMON_1 LL_ADC_SAMPLINGTIME_COMMON_1
#define ADC4_SAMPLINGTIME_COMMON_2 LL_ADC_SAMPLINGTIME_COMMON_2
#define ADC4_SAMPLINGTIME_COMMON_1 LL_ADC_SAMPLINGTIME_COMMON_1
#define ADC4_SAMPLINGTIME_COMMON_2 LL_ADC_SAMPLINGTIME_COMMON_2
#define ADC4_SAMPLINGTIME_COMMON_1 LL_ADC_SAMPLINGTIME_COMMON_1
#define ADC4_SAMPLINGTIME_COMMON_2 LL_ADC_SAMPLINGTIME_COMMON_2
#define ADC4_SAMPLINGTIME_COMMON_1 LL_ADC_SAMPLINGTIME_COMMON_1
#define ADC4_SAMPLINGTIME_COMMON_2 LL_ADC_SAMPLINGTIME_COMMON_2
#define ADC4_SAMPLINGTIME_COMMON_1 LL_ADC_SAMPLINGTIME_COMMON_1
#define ADC4_SAMPLINGTIME_COMMON_2 LL_ADC_SAMPLINGTIME_COMMON_2
#define ADC4_SAMPLINGTIME_COMMON_1 LL_ADC_SAMPLINGTIME_COMMON_1
#define ADC4_SAMPLINGTIME_COMMON_2 LL_ADC_SAMPLINGTIME_COMMON_2
#define ADC4_SAMPLINGTIME_COMMON_1 LL_ADC_SAMPLINGTIME_COMMON_1
#define ADC4_SAMPLINGTIME_COMMON_2 LL_ADC_SAMPLINGTIME_COMMON_2
#define ADC4_SAMPLINGTIME_COMMON_1 LL_ADC_SAMPLINGTIME_COMMON_1
#define ADC4_SAMPLINGTIME_COMMON_2 LL_ADC_SAMPLINGTIME_COMMON_2
#define ADC4_SAMPLINGTIME_COMMON_1 LL_ADC_SAMPLINGTIME_COMMON_1
#define ADC4_SAMPLINGTIME_COMMON_2 LL_ADC_SAMPLINGTIME_COMMON_2
#define ADC4_SAMPLINGTIME_COMMON_1 LL_ADC_SAMPLINGTIME_COMMON_1
#define ADC4_SAMPLINGTIME_COMMON_2 LL_ADC_SAMPLINGTIME_COMMON_2
#define ADC4_SAMPLINGTIME_COMMON_1 LL_ADC_SAMPLINGTIME_COMMON_1
#define ADC4_SAMPLINGTIME_COMMON_2 LL_ADC_SAMPLINGTIME_COMMON_2
#define ADC4_SAMPLINGTIME_COMMON_1 LL_ADC_SAMPLINGTIME_COMMON_1
#define ADC4_SAMPLINGTIME_COMMON_2 LL_ADC_SAMPLINGTIME_COMMON_2
#define ADC4_SAMPLINGTIME_COMMON_1 LL_ADC_SAMPLINGTIME_COMMON_1
#define ADC4_SAMPLINGTIME_COMMON_2 LL_ADC_SAMPLINGTIME_COMMON_2
#define ADC4_SAMPLINGTIME_COMMON_1 LL_ADC_SAMPLINGTIME_COMMON_1
#define ADC4_SAMPLINGTIME_COMMON_2 LL_ADC_SAMPLINGTIME_COMMON_2
#define ADC4_SAMPLINGTIME_COMMON_1 LL_ADC_SAMPLINGTIME_COMMON_1
#define ADC4_SAMPLINGTIME_COMMON_2 LL_ADC_SAMPLINGTIME_COMMON_2
#define ADC4_SAMPLINGTIME_COMMON_1 LL_ADC_SAMPLINGTIME_COMMON_1
#define ADC4_SAMPLINGTIME_COMMON_2 LL_ADC_SAMPLINGTIME_COMMON_2
#define ADC4_SAMPLINGTIME_COMMON_1 LL_ADC_SAMPLINGTIME_COMMON_1
#define ADC4_SAMPLINGTIME_COMMON_2 LL_ADC_SAMPLINGTIME_COMMON_2
#define ADC4_SAMPLINGTIME_COMMON_1 LL_ADC_SAMPLINGTIME_COMMON_1
#define ADC4_SAMPLINGTIME_COMMON_2 LL_ADC_SAMPLINGTIME_COMMON_2
#define ADC4_SAMPLINGTIME_COMMON_1 LL_ADC_SAMPLINGTIME_COMMON_1
#define ADC4_SAMPLINGTIME_COMMON_2 LL_ADC_SAMPLINGTIME_COMMON_2
#define ADC4_SAMPLINGTIME_COMMON_1 LL_ADC_SAMPLINGTIME_COMMON_1
#define ADC4_SAMPLINGTIME_COMMON_2 LL_ADC_SAMPLINGTIME_COMMON_2
#define ADC4_SAMPLINGTIME_COMMON_1 LL_ADC_SAMPLINGTIME_COMMON_1
#define ADC4_SAMPLINGTIME_COMMON_2 LL_ADC_SAMPLINGTIME_COMMON_2
#define ADC4_SAMPLINGTIME_COMMON_1 LL_ADC_SAMPLINGTIME_COMMON_1
#define ADC4_SAMPLINGTIME_COMMON_2 LL_ADC_SAMPLINGTIME_COMMON_2
#define ADC4_SAMPLINGTIME_COMMON_1 LL_ADC_SAMPLINGTIME_COMMON_1
#define ADC4_SAMPLINGTIME_COMMON_2 LL_ADC_SAMPLINGTIME_COMMON_2
#define ADC4_SAMPLINGTIME_COMMON_1 LL_ADC_SAMPLINGTIME_COMMON_1
#define ADC4_SAMPLINGTIME_COMMON_2 LL_ADC_SAMPLINGTIME_COMMON_2
#define ADC4_SAMPLINGTIME_COMMON_1 LL_ADC_SAMPLINGTIME_COMMON_1
#define ADC4_SAMPLINGTIME_COMMON_2 LL_ADC_SAMPLINGTIME_COMMON_2
#define ADC4_SAMPLINGTIME_COMMON_1 LL_ADC_SAMPLINGTIME_COMMON_1
#define ADC4_SAMPLINGTIME_COMMON_2 LL_ADC_SAMPLINGTIME_COMMON_2
#define ADC4_SAMPLINGTIME_COMMON_1 LL_ADC_SAMPLINGTIME_COMMON_1
#define ADC4_SAMPLINGTIME_COMMON_2 LL_ADC_SAMPLINGTIME_COMMON_2
#define ADC4_SAMPLINGTIME_COMMON_1 LL_ADC_SAMPLINGTIME_COMMON_1
#define ADC4_SAMPLINGTIME_COMMON_2 LL_ADC_SAMPLINGTIME_COMMON_2
#define ADC4_SAMPLINGTIME_COMMON_1 LL_ADC_SAMPLINGTIME_COMMON_1
#define ADC4_SAMPLINGTIME_COMMON_2 LL_ADC_SAMPLINGTIME_COMMON_2
#define ADC4_SAMPLINGTIME_COMMON_1 LL_ADC_SAMPLINGTIME_COMMON_1
#define ADC4_SAMPLINGTIME_COMMON_2 LL_ADC_SAMPLINGTIME_COMMON_2
#define ADC4_SAMPLINGTIME_COMMON_1 LL_ADC_SAMPLINGTIME_COMMON_1
#define ADC4_SAMPLINGTIME_COMMON_2 LL_ADC_SAMPLINGTIME_COMMON_2
#define ADC4_SAMPLINGTIME_COMMON_1 LL_ADC_SAMPLINGTIME_COMMON_1
#define ADC4_SAMPLINGTIME_COMMON_2 LL_ADC_SAMPLINGTIME_COMMON_2
#define ADC4_SAMPLINGTIME_COMMON_1 LL_ADC_SAMPLINGTIME_COMMON_1
#define ADC4_SAMPLINGTIME_COMMON_2 LL_ADC_SAMPLINGTIME_COMMON_2
#define ADC4_SAMPLINGTIME_COMMON_1 LL_ADC_SAMPLINGTIME_COMMON_1
#define ADC4_SAMPLINGTIME_COMMON_2 LL_ADC_SAMPLINGTIME_COMMON_2
#define ADC4_SAMPLINGTIME_COMMON_1 LL_ADC_SAMPLINGTIME_COMMON_1
#define ADC4_SAMPLINGTIME_COMMON_2 LL_ADC_SAMPLINGTIME_COMMON_2
#define ADC4_SAMPLINGTIME_COMMON_1 LL_ADC_SAMPLINGTIME_COMMON_1
#define ADC4_SAMPLINGTIME_COMMON_2 LL_ADC_SAMPLINGTIME_COMMON_2
#define ADC4_SAMPLINGTIME_COMMON_1 LL_ADC_SAMPLINGTIME_COMMON_1
#define ADC4_SAMPLINGTIME_COMMON_2 LL_ADC_SAMPLINGTIME_COMMON_2
#define ADC4_SAMPLINGTIME_COMMON_1 LL_ADC_SAMPLINGTIME_COMMON_1
#define ADC4_SAMPLINGTIME_COMMON_2 LL_ADC_SAMPLINGTIME_COMMON_2
#define ADC4_SAMPLINGTIME_COMMON_1 LL_ADC_SAMPLINGTIME_COMMON_1
#define ADC4_SAMPLINGTIME_COMMON_2 LL_ADC_SAMPLINGTIME_COMMON_2
#define ADC4_SAMPLINGTIME_COMMON_1 LL_ADC_SAMPLINGTIME_COMMON_1
#define ADC4_SAMPLINGTIME_COMMON_2 LL_ADC_SAMPLINGTIME_COMMON_2
#define ADC4_SAMPLINGTIME_COMMON_1 LL_ADC_SAMPLINGTIME_COMMON_1
#define ADC4_SAMPLINGTIME_COMMON_2 LL_ADC_SAMPLINGTIME_COMMON_2
#define ADC4_SAMPLINGTIME_COMMON_1 LL_ADC_SAMPLINGTIME_COMMON_1
#define ADC4_SAMPLINGTIME_COMMON_2 LL_ADC_SAMPLINGTIME_COMMON_2
#define ADC4_SAMPLINGTIME_COMMON_1 LL_ADC_SAMPLINGTIME_COMMON_1
#define ADC4_SAMPLINGTIME_COMMON_2 LL_ADC_SAMPLINGTIME_COMMON_2
#define ADC4_SAMPLINGTIME_COMMON_1 LL_ADC_SAMPLINGTIME_COMMON_1
#define ADC4_SAMPLINGTIME_COMMON_2 LL_ADC_SAMPLINGTIME_COMMON_2
#define ADC4_SAMPLINGTIME_COMMON_1 LL_ADC_SAMPLINGTIME_COMMON_1
#define ADC4_SAMPLINGTIME_COMMON_2 LL_ADC_SAMPLINGTIME_COMMON_2
#define ADC4_SAMPLINGTIME_COMMON_1 LL_ADC_SAMPLINGTIME_COMMON_1
#define ADC4_SAMPLINGTIME_COMMON_2 LL_ADC_SAMPLINGTIME_COMMON_2
#define ADC4_SAMPLINGTIME_COMMON_1 LL_ADC_SAMPLINGTIME_COMMON_1
#define ADC4_SAMPLINGTIME_COMMON_2 LL_ADC_SAMPLINGTIME_COMMON_2
#define ADC4_SAMPLINGTIME_COMMON_1 LL_ADC_SAMPLINGTIME_COMMON_1
#define ADC4_SAMPLINGTIME_COMMON_2 LL_ADC_SAMPLINGTIME_COMMON_2
#define ADC4_SAMPLINGTIME_COMMON_1 LL_ADC_SAMPLINGTIME_COMMON_1
#define ADC4_SAMPLINGTIME_COMMON_2 LL_ADC_SAMPLINGTIME_COMMON_2
#define ADC4_SAMPLINGTIME_COMMON_1 LL_ADC_SAMPLINGTIME_COMMON_1
#define ADC4_SAMPLINGTIME_COMMON_2 LL_ADC_SAMPLINGTIME_COMMON_2
#define ADC4_SAMPLINGTIME_COMMON_1 LL_ADC_SAMPLINGTIME_COMMON_1
#define ADC4_SAMPLINGTIME_COMMON_2 LL_ADC_SAMPLINGTIME_COMMON_2
#define ADC4_SAMPLINGTIME_COMMON_1 LL_ADC_SAMPLINGTIME_COMMON_1
#define ADC4_SAMPLINGTIME_COMMON_2 LL_ADC_SAMPLINGTIME_COMMON_2
#define ADC4_SAMPLINGTIME_COMMON_1 LL_ADC_SAMPLINGTIME_COMMON_1
#define ADC4_SAMPLINGTIME_COMMON_2 LL_ADC_SAMPLINGTIME_COMMON_2
#define ADC4_SAMPLINGTIME_COMMON_1 LL_ADC_SAMPLINGTIME_COMMON_1
#define ADC4_SAMPLINGTIME_COMMON_2 LL_ADC_SAMPLINGTIME_COMMON_2
#define ADC4_SAMPLINGTIME_COMMON_1 LL_ADC_SAMPLINGTIME_COMMON_1
#define ADC4_SAMPLINGTIME_COMMON_2 LL_ADC_SAMPLINGTIME_COMMON_2
#define ADC4_SAMPLINGTIME_COMMON_1 LL_ADC_SAMPLINGTIME_COMMON_1
#define ADC4_SAMPLINGTIME_COMMON_2 LL_ADC_SAMPLINGTIME_COMMON_2
#define ADC4_SAMPLINGTIME_COMMON_1 LL_ADC_SAMPLINGTIME_COMMON_1
#define ADC4_SAMPLINGTIME_COMMON_2 LL_ADC_SAMPLINGTIME_COMMON_2
#define ADC4_SAMPLINGTIME_COMMON_1 LL_ADC_SAMPLINGTIME_COMMON_1
#define ADC4_SAMPLINGTIME_COMMON_2 LL_ADC_SAMPLINGTIME_COMMON_2
#define ADC4_SAMPLINGTIME_COMMON_1 LL_ADC_SAMPLINGTIME_COMMON_1
#define ADC4_SAMPLINGTIME_COMMON_2 LL_ADC_SAMPLINGTIME_COMMON_2
#define ADC4_SAMPLINGTIME_COMMON_1 LL_ADC_SAMPLINGTIME_COMMON_1
#define ADC4_SAMPLINGTIME_COMMON_2 LL_ADC_SAMPLINGTIME_COMMON_2
#define ADC4_SAMPLINGTIME_COMMON_1 LL_ADC_SAMPLINGTIME_COMMON_1
#define ADC4_SAMPLINGTIME_COMMON_2 LL_ADC_SAMPLINGTIME_COMMON_2
#define ADC4_SAMPLINGTIME_COMMON_1 LL_ADC_SAMPLINGTIME_COMMON_1
#define ADC4_SAMPLINGTIME_COMMON_2 LL_ADC_SAMPLINGTIME_COMMON_2
#define ADC4_SAMPLINGTIME_COMMON_1 LL_ADC_SAMPLINGTIME_COMMON_1
#define ADC4_SAMPLINGTIME_COMMON_2 LL_ADC_SAMPLINGTIME_COMMON_2
#define ADC4_SAMPLINGTIME_COMMON_1 LL_ADC_SAMPLINGTIME_COMMON_1
#define ADC4_SAMPLINGTIME_COMMON_2 LL_ADC_SAMPLINGTIME_COMMON_2
#define ADC4_SAMPLINGTIME_COMMON_1 LL_ADC_SAMPLINGTIME_COMMON_1
#define ADC4_SAMPLINGTIME_COMMON_2 LL_ADC_SAMPLINGTIME_COMMON_2
#define ADC4_SAMPLINGTIME_COMMON_1 LL_ADC_SAMPLINGTIME_COMMON_1
#define ADC4_SAMPLINGTIME_COMMON_2 LL_ADC_SAMPLINGTIME_COMMON_2
#define ADC4_SAMPLINGTIME_COMMON_1 LL_ADC_SAMPLINGTIME_COMMON_1
#define ADC4_SAMPLINGTIME_COMMON_2 LL_ADC_SAMPLINGTIME_COMMON_2
#define ADC4_SAMPLINGTIME_COMMON_1 LL_ADC_SAMPLINGTIME_COMMON_1
#define ADC4_SAMPLINGTIME_COMMON_2 LL_ADC_SAMPLINGTIME_COMMON_2
#define ADC4_SAMPLINGTIME_COMMON_1 LL_ADC_SAMPLINGTIME_COMMON_1
#define ADC4_SAMPLINGTIME_COMMON_2 LL_ADC_SAMPLINGTIME_COMMON_2
#define ADC4_SAMPLINGTIME_COMMON_1 LL_ADC_SAMPLINGTIME_COMMON_1
#define ADC4_SAMPLINGTIME_COMMON_2 LL_ADC_SAMPLINGTIME_COMMON_2
#define ADC4_SAMPLINGTIME_COMMON_1 LL_ADC_SAMPLINGTIME_COMMON_1
#define ADC4_SAMPLINGTIME_COMMON_2 LL_ADC_SAMPLINGTIME_COMMON_2
#define ADC4_SAMPLINGTIME_COMMON_1 LL_ADC_SAMPLINGTIME_COMMON_1
#define ADC4_SAMPLINGTIME_COMMON_2 LL_ADC_SAMPLINGTIME_COMMON_2
#define ADC4_SAMPLINGTIME_COMMON_1 LL_ADC_SAMPLINGTIME_COMMON_1
#define ADC4_SAMPLINGTIME_COMMON_2 LL_ADC_SAMPLINGTIME_COMMON_2
#define ADC4_SAMPLINGTIME_COMMON_1 LL_ADC_SAMPLINGTIME_COMMON_1
#define ADC4_SAMPLINGTIME_COMMON_2 LL_ADC_SAMPLINGTIME_COMMON_2
#define ADC4_SAMPLINGTIME_COMMON_1 LL_ADC_SAMPLINGTIME_COMMON_1
#define ADC4_SAMPLINGTIME_COMMON_2 LL_ADC_SAMPLINGTIME_COMMON_2
#define ADC4_SAMPLINGTIME_COMMON_1 LL_ADC_SAMPLINGTIME_COMMON_1
#define ADC4_SAMPLINGTIME_COMMON_2 LL_ADC_SAMPLINGTIME_COMMON_2
#define ADC4_SAMPLINGTIME_COMMON_1 LL_ADC_SAMPLINGTIME_COMMON_1
#define ADC4_SAMPLINGTIME_COMMON_2 LL_ADC_SAMPLINGTIME_COMMON_2
#define ADC4_SAMPLINGTIME_COMMON_1 LL_ADC_SAMPLINGTIME_COMMON_1
#define ADC4_SAMPLINGTIME_COMMON_2 LL_ADC_SAMPLINGTIME_COMMON_2
#define ADC4_SAMPLINGTIME_COMMON_1 LL_ADC_SAMPLINGTIME_COMMON_1
#define ADC4_SAMPLINGTIME_COMMON_2 LL_ADC_SAMPLINGTIME_COMMON_2
#define ADC4_SAMPLINGTIME_COMMON_1 LL_ADC_SAMPLINGTIME_COMMON_1
#define ADC4_SAMPLINGTIME_COMMON_2 LL_ADC_SAMPLINGTIME_COMMON_2
#define ADC4_SAMPLINGTIME_COMMON_1 LL_ADC_SAMPLINGTIME_COMMON_1
#define ADC4_SAMPLINGTIME_COMMON_2 LL_ADC_SAMPLINGTIME_COMMON_2
#define ADC4_SAMPLINGTIME_COMMON_1 LL_ADC_SAMPLINGTIME_COMMON_1
#define ADC4_SAMPLINGTIME_COMMON_2 LL_ADC_SAMPLINGTIME_COMMON_2
#define ADC4_SAMPLINGTIME_COMMON_1 LL_ADC_SAMPLINGTIME_COMMON_1
#define ADC4_SAMPLINGTIME_COMMON_2 LL_ADC_SAMPLINGTIME_COMMON_2
#define ADC4_SAMPLINGTIME_COMMON_1 LL_ADC_SAMPLINGTIME_COMMON_1
#define ADC4_SAMPLINGTIME_COMMON_2 LL_ADC_SAMPLINGTIME_COMMON_2
#define ADC4_SAMPLINGTIME_COMMON_1 LL_ADC_SAMPLINGTIME_COMMON_1
#define ADC4_SAMPLINGTIME_COMMON_2 LL_ADC_SAMPLINGTIME_COMMON_2
#define ADC4_SAMPLINGTIME_COMMON_1 LL_ADC_SAMPLINGTIME_COMMON_1
#define ADC4_SAMPLINGTIME_COMMON_2 LL_ADC_SAMPLINGTIME_COMMON_2
#define ADC4_SAMPLINGTIME_COMMON_1 LL_ADC_SAMPLINGTIME_COMMON_1
#define ADC4_SAMPLINGTIME_COMMON_2 LL_ADC_SAMPLINGTIME_COMMON_2
#define ADC4_SAMPLINGTIME_COMMON_1 LL_ADC_SAMPLINGTIME_COMMON_1
#define ADC4_SAMPLINGTIME_COMMON_2 LL_ADC_SAMPLINGTIME_COMMON_2
#define ADC4_SAMPLINGTIME_COMMON_1 LL_ADC_SAMPLINGTIME_COMMON_1
#define ADC4_SAMPLINGTIME_COMMON_2 LL_ADC_SAMPLINGTIME_COMMON_2
#define ADC4_SAMPLINGTIME_COMMON_1 LL_ADC_SAMPLINGTIME_COMMON_1
#define ADC4_SAMPLINGTIME_COMMON_2 LL_ADC_SAMPLINGTIME_COMMON_2
#define ADC4_SAMPLINGTIME_COMMON_1 LL_ADC_SAMPLINGTIME_COMMON_1
#define ADC4_SAMPLINGTIME_COMMON_2 LL_ADC_SAMPLINGTIME_COMMON_2
#define ADC4_SAMPLINGTIME_COMMON_1 LL_ADC_SAMPLINGTIME_COMMON_1
#define ADC4_SAMPLINGTIME_COMMON_2 LL_ADC_SAMPLINGTIME_COMMON_2
#define ADC4_SAMPLINGTIME_COMMON_1 LL_ADC_SAMPLINGTIME_COMMON_1
#define ADC4_SAMPLINGTIME_COMMON_2 LL_ADC_SAMPLINGTIME_COMMON_2
#define ADC4_SAMPLINGTIME_COMMON_1 LL_ADC_SAMPLINGTIME_COMMON_1
#define ADC4_SAMPLINGTIME_COMMON_2 LL_ADC_SAMPLINGTIME_COMMON_2
#define ADC4_SAMPLINGTIME_COMMON_1 LL_ADC_SAMPLINGTIME_COMMON_1
#define ADC4_SAMPLINGTIME_COMMON_2 LL_ADC_SAMPLINGTIME_COMMON_2
#define ADC4_SAMPLINGTIME_COMMON_1 LL_ADC_SAMPLINGTIME_COMMON_1
#define ADC4_SAMPLINGTIME_COMMON_2 LL_ADC_SAMPLINGTIME_COMMON_2
#define ADC4_SAMPLINGTIME_COMMON_1 LL_ADC_SAMPLINGTIME_COMMON_1
#define ADC4_SAMPLINGTIME_COMMON_2 LL_ADC_SAMPLINGTIME_COMMON_2
#define ADC4_SAMPLINGTIME_COMMON_1 LL_ADC_SAMPLINGTIME_COMMON_1
#define ADC4_SAMPLINGTIME_COMMON_2 LL_ADC_SAMPLINGTIME_COMMON_2
#define ADC4_SAMPLINGTIME_COMMON_1 LL_ADC_SAMPLINGTIME_COMMON_1
#define ADC4_SAMPLINGTIME_COMMON_2 LL_ADC_SAMPLINGTIME_COMMON_2
#define ADC4_SAMPLINGTIME_COMMON_1 LL_ADC_SAMPLINGTIME_COMMON_1
#define ADC4_SAMPLINGTIME_COMMON_2 LL_ADC_SAMPLINGTIME_COMMON_2
#define ADC4_SAMPLINGTIME_COMMON_1 LL_ADC_SAMPLINGTIME_COMMON_1
#define ADC4_SAMPLINGTIME_COMMON_2 LL_ADC_SAMPLINGTIME_COMMON_2
#define ADC4_SAMPLINGTIME_COMMON_1 LL_ADC_SAMPLINGTIME_COMMON_1
#define ADC4_SAMPLINGTIME_COMMON_2 LL_ADC_SAMPLINGTIME_COMMON_2
#define ADC4_SAMPLINGTIME_COMMON_1 LL_ADC_SAMPLINGTIME_COMMON_1
#define ADC4_SAMPLINGTIME_COMMON_2 LL_ADC_SAMPLINGTIME_COMMON_2
#define ADC4_SAMPLINGTIME_COMMON_1 LL_ADC_SAMPLINGTIME_COMMON_1
#define ADC4_SAMPLINGTIME_COMMON_2 LL_ADC_SAMPLINGTIME_COMMON_2
#define ADC4_SAMPLINGTIME_COMMON_1 LL_ADC_SAMPLINGTIME_COMMON_1
#define ADC4_SAMPLINGTIME_COMMON_2 LL_ADC_SAMPLINGTIME_COMMON_2
#define ADC4_SAMPLINGTIME_COMMON_1 LL_ADC_SAMPLINGTIME_COMMON_1
#define ADC4_SAMPLINGTIME_COMMON_2 LL_ADC_SAMPLINGTIME_COMMON_2
#define ADC4_SAMPLINGTIME_COMMON_1 LL_ADC_SAMPLINGTIME_COMMON_1
#define ADC4_SAMPLINGTIME_COMMON_2 LL_ADC_SAMPLINGTIME_COMMON_2
#define ADC4_SAMPLINGTIME_COMMON_1 LL_ADC_SAMPLINGTIME_COMMON_1
#define ADC4_SAMPLINGTIME_COMMON_2 LL_ADC_SAMPLINGTIME_COMMON_2
#define ADC4_SAMPLINGTIME_COMMON_1 LL_ADC_SAMPLINGTIME_COMMON_1
#define ADC4_SAMPLINGTIME_COMMON_2 LL_ADC_SAMPLINGTIME_COMMON_2
#define ADC4_SAMPLINGTIME_COMMON_1 LL_ADC_SAMPLINGTIME_COMMON_1
#define ADC4_SAMPLINGTIME_COMMON_2 LL_ADC_SAMPLINGTIME_COMMON_2
#define ADC4_SAMPLINGTIME_COMMON_1 LL_ADC_SAMPLINGTIME_COMMON_1
#define ADC4_SAMPLINGTIME_COMMON_2 LL_ADC_SAMPLINGTIME_COMMON_2
#define ADC4_SAMPLINGTIME_COMMON_1 LL_ADC_SAMPLINGTIME_COMMON_1
#define ADC4_SAMPLINGTIME_COMMON_2 LL_ADC_SAMPLINGTIME_COMMON_2
#define ADC4_SAMPLINGTIME_COMMON_1 LL_ADC_SAMPLINGTIME_COMMON_1
#define ADC4_SAMPLINGTIME_COMMON_2 LL_ADC_SAMPLINGTIME_COMMON_2
#define ADC4_SAMPLINGTIME_COMMON_1 LL_ADC_SAMPLINGTIME_COMMON_1
#define ADC4_SAMPLINGTIME_COMMON_2 LL_ADC_SAMPLINGTIME_COMMON_2
#define ADC4_SAMPLINGTIME_COMMON_1 LL_ADC_SAMPLINGTIME_COMMON_1
#define ADC4_SAMPLINGTIME_COMMON_2 LL_ADC_SAMPLINGTIME_COMMON_2
#define ADC4_SAMPLINGTIME_COMMON_1 LL_ADC_SAMPLINGTIME_COMMON_1
#define ADC4_SAMPLINGTIME_COMMON_2 LL_ADC_SAMPLINGTIME_COMMON_2
#define ADC4_SAMPLINGTIME_COMMON_1 LL_ADC_SAMPLINGTIME_COMMON_1
#define ADC4_SAMPLINGTIME_COMMON_2 LL_ADC_SAMPLINGTIME_COMMON_2
#define ADC4_SAMPLINGTIME_COMMON_1 LL_ADC_SAMPLINGTIME_COMMON_1
#define ADC4_SAMPLINGTIME_COMMON_2 LL_ADC_SAMPLINGTIME_COMMON_2
#define ADC4_SAMPLINGTIME_COMMON_1 LL_ADC_SAMPLINGTIME_COMMON_1
#define ADC4_SAMPLINGTIME_COMMON_2 LL_ADC_SAMPLINGTIME_COMMON_2
#define ADC4_SAMPLINGTIME_COMMON_1 LL_ADC_SAMPLINGTIME_COMMON_1
#define ADC4_SAMPLINGTIME_COMMON_2 LL_ADC_SAMPLINGTIME_COMMON_2
#define ADC4_SAMPLINGTIME_COMMON_1 LL_ADC_SAMPLINGTIME_COMMON_1
#define ADC4_SAMPLINGTIME_COMMON_2 LL_ADC_SAMPLINGTIME_COMMON_2
#define ADC4_SAMPLINGTIME_COMMON_1 LL_ADC_SAMPLINGTIME_COMMON_1
#define ADC4_SAMPLINGTIME_COMMON_2 LL_ADC_SAMPLINGTIME_COMMON_2
#define ADC4_SAMPLINGTIME_COMMON_1 LL_ADC_SAMPLINGTIME_COMMON_1
#define ADC4_SAMPLINGTIME_COMMON_2 LL_ADC_SAMPLINGTIME_COMMON_2
#define ADC4_SAMPLINGTIME_COMMON_1 LL_ADC_SAMPLINGTIME_COMMON_1
#define ADC4_SAMPLINGTIME_COMMON_2 LL_ADC_SAMPLINGTIME_COMMON_2
#define ADC4_SAMPLINGTIME_COMMON_1 LL_ADC_SAMPLINGTIME_COMMON_1
#define ADC4_SAMPLINGTIME_COMMON_2 LL_ADC_SAMPLINGTIME_COMMON_2
#define ADC4_SAMPLINGTIME_COMMON_1 LL_ADC_SAMPLINGTIME_COMMON_1
#define ADC4_SAMPLINGTIME_COMMON_2 LL_ADC_SAMPLINGTIME_COMMON_2
#define ADC4_SAMPLINGTIME_COMMON_1 LL_ADC_SAMPLINGTIME_COMMON_1

#include "FOC.h"
#include "NVMemory.h"
#include "scara.h"
#include "camera_platform.h"
extern UART_HandleTypeDef huart1;
/* USER CODE END Includes */

/* USER CODE BEGIN PM */
void FDCAN_Config(void);
/* USER CODE END PM */

/* USER CODE BEGIN PV */
uint8_t Data[32] = "LED Toggle DMA\r\n";

#define ADC_OFFSET_CNT	10

uint16_t IA_Offset, IB_Offset, IC_Offset;
uint16_t adc1_in1, adc1_in2,adc1_in3;
uint8_t ADC_offset = 0;
uint8_t invertStat = 0;
uint16_t rawData;
uint16_t g_sensorData = 0;  // Global variable to store the sensor data
uint16_t DelayCnt = 1;
float load_data[6];
static uint8_t tempData[28] = {0,0,0,0,0,0,0,0,0,0,0,0,0,0,0,0,0,0,0,0,0,0,0,0,0,0,0x80,0x7f};
uint8_t A,B,I;

uint32_t writeValue = 0x99999999,pValue=0;
uint16_t addr = 1;
uint8_t eepromWriteFlag = 1;

/* USER CODE END PV */

void SystemClock_Config(void);

/* USER CODE BEGIN 0 */
// ???????????????????
uint8_t I2C_ReadRegister(uint16_t DevAddress, uint8_t RegAddress)
{
    uint8_t receivedData = 0;
    HAL_StatusTypeDef status;

    // ??????????
    status = HAL_I2C_Master_Transmit(&hi2c3, DevAddress << 1, &RegAddress, 1, HAL_MAX_DELAY);
    if (status != HAL_OK)
    {
        // ?????????
        Error_Handler();
    }

    // ???????????
    status = HAL_I2C_Master_Receive(&hi2c3, DevAddress << 1, &receivedData, 1, HAL_MAX_DELAY);
    if (status != HAL_OK)
    {
        // ?????????
        Error_Handler();
    }

    return receivedData;
}

void Write_I2C(uint8_t deviceAddress, uint8_t registerAddress, uint8_t data)
{
    // ??????????????????
    uint8_t buffer[2];
    buffer[0] = registerAddress; // ???????
    buffer[1] = data;            // ?????????

    // ??I2C?????????
    if (HAL_I2C_Master_Transmit(&hi2c3, (deviceAddress << 1), buffer, 2, HAL_MAX_DELAY) != HAL_OK)
    {
        // ??????,???????
        Error_Handler();
    }
}

/* USER CODE END 0 */

int main(void)
{

  /* MCU Configuration--------------------------------------------------------*/

  /* Reset of all peripherals, Initializes the Flash interface and the Systick. */
  HAL_Init();

  /* Configure the system clock */
  SystemClock_Config();

  /* USER CODE BEGIN SysInit */
  NV_Init();
  /* USER CODE END SysInit */

  /* Initialize all configured peripherals */
  MX_GPIO_Init();
  MX_DMA_Init();
  MX_USART1_UART_Init();
  MX_ADC1_Init();
  MX_ADC2_Init();
  MX_OPAMP1_Init();
  MX_OPAMP2_Init();
  MX_OPAMP3_Init();
  MX_TIM1_Init();
  MX_COMP1_Init();
  MX_DAC3_Init();
  MX_I2C3_Init();
  MX_SPI1_Init();
  MX_FDCAN1_Init();
  MX_TIM4_Init();
  MX_TIM2_Init();
  MX_I2C2_Init();
  MX_LPUART1_UART_Init();
  /* USER CODE BEGIN 2 */
	HAL_OPAMP_Start(&hopamp1); // ʹ���˷�
	HAL_OPAMP_Start(&hopamp2); // ʹ���˷�
	HAL_OPAMP_Start(&hopamp3); // ʹ���˷�
	HAL_UART_Receive_IT(&huart1, (uint8_t *)&aRxBuffer,1);
	HAL_ADCEx_Calibration_Start(&hadc1, ADC_SINGLE_ENDED);
	HAL_ADCEx_Calibration_Start(&hadc2, ADC_SINGLE_ENDED);
	HAL_GPIO_WritePin(GPIOE, GPIO_PIN_7, GPIO_PIN_SET);  // ����invert
//	TIM1->PSC = 1000;
//	TIM1->ARR = 10000;
	// TIM1->ARR = 8000-1;
	// TIM1->CCR1 = 0;  // �Ƚ�ֵ����������õ�8000
	// TIM1->CCR2 = 0;
	// TIM1->CCR3 = 0;
	// TIM1->CCR4 = 8000-2;

	// HAL_TIM_Base_Start(&htim1);
	// HAL_TIM_PWM_Start(&htim1, TIM_CHANNEL_1);
	// HAL_TIM_PWM_Start(&htim1, TIM_CHANNEL_2);
	// HAL_TIM_PWM_Start(&htim1, TIM_CHANNEL_3);
	// HAL_TIMEx_PWMN_Start(&htim1, TIM_CHANNEL_1);
	// HAL_TIMEx_PWMN_Start(&htim1, TIM_CHANNEL_2);
	// HAL_TIMEx_PWMN_Start(&htim1, TIM_CHANNEL_3);

	// HAL_TIM_PWM_Start(&htim1, TIM_CHANNEL_4);  // start interruput

	// HAL_ADCEx_InjectedStart_IT(&hadc1);
	// HAL_ADCEx_InjectedStart(&hadc2);

	HAL_DAC_Start(&hdac3,DAC_CHANNEL_1);  // �����ڲ��Ƚ����������Ⲩ
	//HAL_DAC_Start(&hdac1,DAC_CHANNEL_1);  // �����ⲿģ�������
	HAL_DAC_SetValue(&hdac3,DAC_CHANNEL_1,DAC_ALIGN_12B_R, 3000);
	//HAL_DAC_SetValue(&hdac1,DAC_CHANNEL_1,DAC_ALIGN_12B_R, 4095);

	// disable without high side power supply
	HAL_COMP_Start(&hcomp1);
	//invertStat = I2C_ReadRegister(0x47, 0x80);
	//Write_I2C(0x47, 0x09, 0xFF);

	FDCAN_Config();

	SysEnable = 0;
	FOC_initialize();
	SpReqPU = 0.01F;

	camera_platform_init();

	// arm_init(&scaraArm); // init arm

//	arm_mov_line(&scaraArm, 0,100,0,330,5); // move line
//	arm_zero(&scaraArm);
//	arm_mov_line(&scaraArm, -150,200,150,200,5); // move line
//
//	arm_reset(&scaraArm);
//
  /* USER CODE END 2 */

  /* Infinite loop */
  /* USER CODE BEGIN WHILE */

      // 启动前先丢弃一次

  while (1)
  {
		// TimerTasks_Scheduler();

       AS5047P_Start_DMA();
       if(as5047p_dma_ready)
       {
        as5047p_dma_ready = 0;
        printf("as5047p_angleDMA: %f\r\n",puAngleDMA);
       }

				//Read_AS5047P_Simple();
        //Read_AS5047P_Complete();

        HAL_Delay(1); // 1ms周期

//		if(eepromWriteFlag)
//		{
//				NV_RequestWriteData(addr, writeValue);  //  anywhere
//				eepromWriteFlag = 0;
//		}
//		NV_Housekeeping();
//		NV_ReadData(addr, &pValue);  // anywhere

//			ref = 0 - ref;       // value
//			motor_write(1, MASTER_ID);
//			HAL_Delay(DelayCnt);

//			memcpy(tempData,(uint8_t *)&load_data,sizeof(load_data));
//			HAL_UART_Transmit_DMA(&huart1, tempData, sizeof(tempData));
//			if((GPIOE->IDR & GPIO_PIN_9) !=0)
//			{
//				load_data[3] = 1.0f;
//			}
//			else
//			{
//				load_data[3] = 0.0f;
//			}
//			HAL_Delay(DelayCnt);  // 1ms
    /* USER CODE END WHILE */

  }
}

void SystemClock_Config(void)
{
  RCC_OscInitTypeDef RCC_OscInitStruct = {0};
  RCC_ClkInitTypeDef RCC_ClkInitStruct = {0};

  /** Configure the main internal regulator output voltage
  */
  HAL_PWREx_ControlVoltageScaling(PWR_REGULATOR_VOLTAGE_SCALE1_BOOST);

  /** Initializes the RCC Oscillators according to the specified parameters
  * in the RCC_OscInitTypeDef structure.
  */
  RCC_OscInitStruct.OscillatorType = RCC_OSCILLATORTYPE_HSI;
  RCC_OscInitStruct.HSIState = RCC_HSI_ON;
  RCC_OscInitStruct.HSICalibrationValue = RCC_HSICALIBRATION_DEFAULT;
  RCC_OscInitStruct.PLL.PLLState = RCC_PLL_ON;
  RCC_OscInitStruct.PLL.PLLSource = RCC_PLLSOURCE_HSI;
  RCC_OscInitStruct.PLL.PLLM = RCC_PLLM_DIV1;
  RCC_OscInitStruct.PLL.PLLN = 20;
  RCC_OscInitStruct.PLL.PLLP = RCC_PLLP_DIV2;
  RCC_OscInitStruct.PLL.PLLQ = RCC_PLLQ_DIV2;
  RCC_OscInitStruct.PLL.PLLR = RCC_PLLR_DIV2;
  if (HAL_RCC_OscConfig(&RCC_OscInitStruct) != HAL_OK)
  {
    Error_Handler();
  }

  /** Initializes the CPU, AHB and APB buses clocks
  */
  RCC_ClkInitStruct.ClockType = RCC_CLOCKTYPE_HCLK|RCC_CLOCKTYPE_SYSCLK
                              |RCC_CLOCKTYPE_PCLK1|RCC_CLOCKTYPE_PCLK2;
  RCC_ClkInitStruct.SYSCLKSource = RCC_SYSCLKSOURCE_PLLCLK;
  RCC_ClkInitStruct.AHBCLKDivider = RCC_SYSCLK_DIV1;
  RCC_ClkInitStruct.APB1CLKDivider = RCC_HCLK_DIV1;
  RCC_ClkInitStruct.APB2CLKDivider = RCC_HCLK_DIV1;

  if (HAL_RCC_ClockConfig(&RCC_ClkInitStruct, FLASH_LATENCY_4) != HAL_OK)
  {
    Error_Handler();
  }
}

/* USER CODE BEGIN 4 */

// adc ע������ж�
void HAL_ADCEx_InjectedConvCpltCallback(ADC_HandleTypeDef *hadc)
{
    /* Prevent unused argument(s) compilation warning */
		static uint8_t cnt;
		real32_T IaAd;
		real32_T IbAd;
		real32_T IcAd;

		TimerTasks_ISR_Handler();

		/* Prevent unused argument(s) compilation warning */
		UNUSED(hadc);
		if(hadc == &hadc1)
		{
				if(ADC_offset == 0)
				{
						cnt++;
						adc1_in1 = hadc1.Instance->JDR1;
					  adc1_in3 = hadc1.Instance->JDR2;
						adc1_in2 = hadc2.Instance->JDR1;

						IA_Offset += adc1_in1;
						IB_Offset += adc1_in2;
						IC_Offset += adc1_in3;
						if(cnt >= ADC_OFFSET_CNT)
						{
								ADC_offset = 1;
								IA_Offset = IA_Offset / ADC_OFFSET_CNT;
								IB_Offset = IB_Offset / ADC_OFFSET_CNT;
								IC_Offset = IC_Offset / ADC_OFFSET_CNT;
						}
				}
				else
				{
						HAL_GPIO_TogglePin(GPIOC, GPIO_PIN_15);
						//Read_SC60228();

						adc1_in1 = hadc1.Instance->JDR1;
						adc1_in3 = hadc1.Instance->JDR2;
					  adc1_in2 = hadc2.Instance->JDR1;

						IaAd = (adc1_in1 - IA_Offset) * 0.0193359375f;  // adc*3.3/(4096*0.005*(1+11/1.5))
						IbAd = (adc1_in2 - IB_Offset) * 0.0193359375f;  // adc*3.3/(4096*0.005*(1+11/1.5))
						IcAd = (adc1_in3 - IC_Offset) * 0.0193359375f;  // adc*3.3/(4096*0.005*(1+11/1.5))

//						Ia = IaSim;
//						Ib = IbSim;
//						Ic = IcSim;

						Ia = -IaAd;
						Ib = -IcAd;
						Ic = -IbAd;

						EposReq = EposOpen;
					  FOC_step();

						TIM1->CCR1 = U;  // �Ƚ�ֵ����������õ�8000
						TIM1->CCR2 = V;
						TIM1->CCR3 = W;
						// puAngle sys_cnt EXT0 EXT1 EXT2 VqReqPU
						load_data[0] = sys_cnt;
						load_data[1] = EXT0;
						load_data[2] = EXT1;
						load_data[3] = EXT2;  //Vpoten;
						load_data[4] = TIM4->CNT;   // Vbus;
						load_data[5] = TIM4->CCR1;   // Vbus;

						memcpy(tempData,(uint8_t *)&load_data,sizeof(load_data));
						//HAL_UART_Transmit_DMA(&huart1, tempData, sizeof(tempData));
				}
		}

    /* NOTE: This function should not be modified. When the callback is needed,
       function HAL_ADCEx_InjectedConvCpltCallback must be implemented in the user file. */
}

// DMA Interruput
//void HAL_SPI_TxRxCpltCallback(SPI_HandleTypeDef *hspi)
//{
//
//		if (hspi->Instance == SPI1) {
//			g_sensorData = (rxBufferDMA[1] << 8) | rxBufferDMA[0];

//			//g_sensorData = g_sensorData>>4;
//			//puAngleDMA = (float)g_sensorData / 4096.0f;
//
//			g_sensorData &= 0x3FFF;
//			puAngle = (float)g_sensorData / 16384.0f;
//
//			__HAL_SPI_DISABLE(&hspi1);
//    }
//
//}

/* USER CODE END 4 */

void Error_Handler(void)
{
  __disable_irq();
  while (1)
  {
  }
}
